VERSION ""

NS_ :

BS_:

BU_: ECM

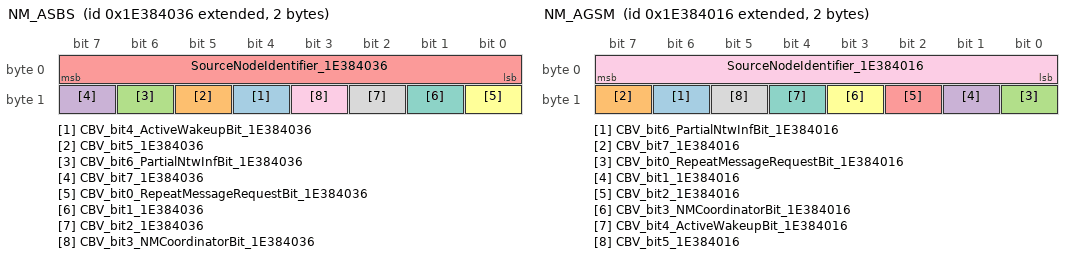
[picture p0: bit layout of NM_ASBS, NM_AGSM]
BO_ 2654486582 NM_ASBS: 2 Vector__XXX
 SG_ CBV_bit4_ActiveWakeupBit_1E384036 : 12|1@0+ (1,0) [0|1] "" ECM
 SG_ CBV_bit5_1E384036 : 13|1@0+ (1,0) [0|1] "" ECM
 SG_ CBV_bit6_PartialNtwInfBit_1E384036 : 14|1@0+ (1,0) [0|1] "" ECM
 SG_ CBV_bit7_1E384036 : 15|1@0+ (1,0) [0|1] "" ECM
 SG_ SourceNodeIdentifier_1E384036 : 7|8@0+ (1,0) [0|255] "-"  ECM
 SG_ CBV_bit0_RepeatMessageRequestBit_1E384036 : 8|1@0+ (1,0) [0|1] "" ECM
 SG_ CBV_bit1_1E384036 : 9|1@0+ (1,0) [0|1] "" ECM
 SG_ CBV_bit2_1E384036 : 10|1@0+ (1,0) [0|1] "" ECM
 SG_ CBV_bit3_NMCoordinatorBit_1E384036 : 11|1@0+ (1,0) [0|1] "" ECM

BO_ 2654486550 NM_AGSM: 2 Vector__XXX
 SG_ CBV_bit6_PartialNtwInfBit_1E384016 : 14|1@0+ (1,0) [0|1] "" ECM
 SG_ CBV_bit7_1E384016 : 15|1@0+ (1,0) [0|1] "" ECM
 SG_ CBV_bit0_RepeatMessageRequestBit_1E384016 : 8|1@0+ (1,0) [0|1] "" ECM
 SG_ CBV_bit1_1E384016 : 9|1@0+ (1,0) [0|1] "" ECM
 SG_ CBV_bit2_1E384016 : 10|1@0+ (1,0) [0|1] "" ECM
 SG_ CBV_bit3_NMCoordinatorBit_1E384016 : 11|1@0+ (1,0) [0|1] "" ECM
 SG_ CBV_bit4_ActiveWakeupBit_1E384016 : 12|1@0+ (1,0) [0|1] "" ECM
 SG_ CBV_bit5_1E384016 : 13|1@0+ (1,0) [0|1] "" ECM
 SG_ SourceNodeIdentifier_1E384016 : 7|8@0+ (1,0) [0|63] "-"  ECM

BO_ 269 HYBRID_POWERTRAIN2: 64 Vector__XXX
 SG_ MaxRegenStat : 299|1@0+ (1,0) [0|1] "" ECM
 SG_ IdleSpeedActiveSts : 302|1@0+ (1,0) [0|0] "-"  ECM
 SG_ CRC_HYBRID_POWERTRAIN2 : 447|8@0+ (1,0) [0|255] "-"  ECM
 SG_ BSGChrgIdleSpeedTarget : 52|13@0+ (1,0) [0|8190] "rpm"  ECM
 SG_ BSGActualTorque : 257|10@0+ (0.32,-163.52) [-163.52|163.2] "Nm"  ECM
 SG_ PropulsionMode : 39|3@0+ (1,0) [0|6] "-"  ECM
 SG_ REPRGD_PFC_CLR_HCP : 303|1@0+ (1,0) [0|1] "-"  ECM
 SG_ EstRegenBrkFWTorq : 371|12@0+ (0.32,-300.16) [-300.16|1009.92] "Nm"  ECM
 SG_ CODE_CLR_HCP : 288|1@0+ (1,0) [0|1] "-"  ECM
 SG_ AeCoast_Ramp : 55|1@0+ (1,0) [0|1] "-"  ECM
 SG_ AHH_ModifyAccel_Req : 4|2@0+ (1,0) [0|2] "" ECM
 SG_ MessageCounter_HYBRID_POWERTRAI_10D : 435|4@0+ (1,0) [0|15] "-"  ECM

BO_ 276 HYBRID_POWERTRAIN1: 64 Vector__XXX
 SG_ TransInpSpdPrfl : 68|13@0+ (1,0) [0|8191] "rpm"  ECM
 SG_ ShiftRangeState : 439|4@0+ (1,0) [0|0] "-"  ECM
 SG_ NiTi_Achieved : 288|1@0+ (1,0) [0|0] "-"  ECM
 SG_ MinCreepWheelTrq_Enable : 286|1@0+ (1,0) [0|1] "" ECM
 SG_ LV_SystemFailure : 421|1@0+ (1,0) [0|0] "-"  ECM
 SG_ InputSpdRaw : 179|12@0+ (1,-2048) [-2048|2046] "rpm"  ECM
 SG_ HybTransSt : 255|8@0+ (1,0) [0|0] "-"  ECM
 SG_ Hybrid_Remedial_Stop : 290|1@0+ (1,0) [0|0] "-"  ECM
 SG_ HybFeedback_Engine : 294|1@0+ (1,0) [0|0] "-"  ECM
 SG_ HybEstEngTorqV : 280|1@0+ (1,0) [0|0] "-"  ECM
 SG_ HybEstEngTorq : 163|12@0+ (0.32,-300.16) [-300.16|1008] "Nm"  ECM
 SG_ HybDFCO_Req : 281|1@0+ (1,0) [0|0] "-"  ECM
 SG_ HybCrnkAbrted : 282|1@0+ (1,0) [0|0] "-"  ECM
 SG_ HybCmndEngTorqRespTyp : 277|2@0+ (1,0) [0|0] "-"  ECM
 SG_ HybCmndEngTorqPrdtd : 147|12@0+ (0.32,-300.16) [-300.16|1008] "Nm"  ECM
 SG_ HybCmndEngTorqImmed : 131|12@0+ (0.32,-300.16) [-300.16|1008] "Nm"  ECM
 SG_ Hyb_EngStrtStopType : 267|4@0+ (1,0) [0|0] "-"  ECM
 SG_ HEV_ESS_Mode : 271|4@0+ (1,0) [0|0] "-"  ECM
 SG_ GeneratorSetpointOverride : 422|1@0+ (1,0) [0|0] "-"  ECM
 SG_ EngTrqReserveCmd : 263|8@0+ (0.32,0) [0|81.28] "Nm"  ECM
 SG_ EngCntrlMode : 283|1@0+ (1,0) [0|0] "-"  ECM
 SG_ EngActDmpgDsblReq : 291|1@0+ (1,0) [0|0] "-"  ECM
 SG_ Eng_Off_Allowed : 292|1@0+ (1,0) [0|0] "-"  ECM
 SG_ ECMPrepIdleRes : 295|1@0+ (1,0) [0|0] "-"  ECM
 SG_ CRC_HYBRID_POWERTRAIN1 : 447|8@0+ (1,0) [0|255] "-"  ECM
 SG_ PropulsionSystemActive : 408|1@0+ (1,0) [0|1] "-"  ECM
 SG_ HybFstTrqRq_Trans : 293|1@0+ (1,0) [0|0] "-"  ECM
 SG_ HCP_Comm_Fail_CAN : 87|3@0+ (1,0) [0|7] "-"  ECM
 SG_ MinCreepWheelTrq : 53|14@0+ (2,-16383) [-16383|16383] "Nm"  ECM
 SG_ NiTi_Disable : 55|1@0+ (1,0) [0|1] "-"  ECM
 SG_ Hyb_MotorB_Speed : 303|16@0+ (1,-16382) [-16382|49152] "rpm"  ECM
 SG_ Hyb_SumTorqueMin : 314|11@0+ (1,-500) [-500|1546] "Nm"  ECM
 SG_ Hyb_SumTorqueMax : 330|11@0+ (1,-500) [-500|1546] "Nm"  ECM
 SG_ Hyb_SumTorqueStatic : 346|11@0+ (1,-500) [-500|1546] "Nm"  ECM
 SG_ DriveModeSts_EPT : 427|4@0+ (1,0) [0|14] "-"  ECM
 SG_ HCP_VTD_Freeze : 7|2@0+ (1,0) [0|3] "-"  ECM
 SG_ MessageCounter_HYBRID_POWERTRAI_114 : 435|4@0+ (1,0) [0|15] "-"  ECM

BO_ 271 ENGINE_HYBD_FD_1: 64 ECM
 SG_ TLC_LRN_Rq : 322|1@0+ (1,0) [0|0] "-"  Vector__XXX
 SG_ T_min_raw_Aggressive : 39|16@0+ (2,-36878) [-36878|94190] "Nm"  Vector__XXX
 SG_ T_max_raw : 55|16@0+ (2,-36878) [-36878|94190] "Nm"  Vector__XXX
 SG_ Sum_FW_ID_Slw : 327|5@0+ (1,0) [0|30] "-"  Vector__XXX
 SG_ Sum_FW_ID_Fst : 367|5@0+ (1,0) [0|30] "-"  Vector__XXX
 SG_ PTCrnkAbrted : 309|1@0+ (1,0) [0|0] "-"  Vector__XXX
 SG_ PT_CrnkAct : 310|1@0+ (1,0) [0|0] "-"  Vector__XXX
 SG_ MinPrdtdEngRunTorqCapV : 213|1@0+ (1,0) [0|0] "-"  Vector__XXX
 SG_ MinPrdtdEngRunTorqCap : 243|12@0+ (0.32,-300.16) [-300.16|1008] "Nm"  Vector__XXX
 SG_ MinImmedEngTorqCapV : 215|1@0+ (1,0) [0|0] "-"  Vector__XXX
 SG_ MinImmedEngTorqCap : 227|12@0+ (0.32,-300.16) [-300.16|1008] "Nm"  Vector__XXX
 SG_ MinEngTorqCapV : 196|1@0+ (1,0) [0|0] "-"  Vector__XXX
 SG_ MinEngTorqCap : 211|12@0+ (0.32,-300.16) [-300.16|1008] "Nm"  Vector__XXX
 SG_ MinAirFlowMinSparkTorqCapV : 197|1@0+ (1,0) [0|0] "-"  Vector__XXX
 SG_ MinAirFlowMinSparkTorqCap : 195|12@0+ (0.32,-300.16) [-300.16|1008] "Nm"  Vector__XXX
 SG_ MessageCounter_ENGINE_HYBD_FD_1 : 435|4@0+ (1,0) [0|15] "-"  Vector__XXX
 SG_ MaxPrdtdEngTorqCapV : 198|1@0+ (1,0) [0|0] "-"  Vector__XXX
 SG_ MaxPrdtdEngTorqCap : 179|12@0+ (0.32,-300.16) [-300.16|1008] "Nm"  Vector__XXX
 SG_ MaxOffEngTorqCap : 163|12@0+ (0.32,-300.16) [-300.16|1008] "Nm"  Vector__XXX
 SG_ HybActEngTorqRespTyp : 149|2@0+ (1,0) [0|0] "-"  Vector__XXX
 SG_ Feedback_HCP : 293|1@0+ (1,0) [0|0] "-"  Vector__XXX
 SG_ ETRQ_Mode : 362|3@0+ (1,0) [0|5] "-"  Vector__XXX
 SG_ ESS_Engine_State_EE : 119|4@0+ (1,0) [0|0] "-"  Vector__XXX
 SG_ EngTrqReserveReq : 351|8@0+ (0.32,0) [0|81.28] "Nm"  Vector__XXX
 SG_ EngSysFld : 294|1@0+ (1,0) [0|0] "-"  Vector__XXX
 SG_ EngRunCrnkAct : 295|1@0+ (1,0) [0|0] "-"  Vector__XXX
 SG_ EngRqStTyp : 103|4@0+ (1,0) [0|0] "-"  Vector__XXX
 SG_ EngOffRecom : 276|1@0+ (1,0) [0|0] "-"  Vector__XXX
 SG_ Engine_Sync_720 : 277|1@0+ (1,0) [0|0] "-"  Vector__XXX
 SG_ EngDFCO_St : 278|1@0+ (1,0) [0|0] "-"  Vector__XXX
 SG_ EngDFCO_Req : 279|1@0+ (1,0) [0|0] "-"  Vector__XXX
 SG_ EngDFCO_Allw : 260|1@0+ (1,0) [0|0] "-"  Vector__XXX
 SG_ EngCmbstnCmnd : 199|1@0+ (1,0) [0|0] "-"  Vector__XXX
 SG_ EngAirFlwStdyStTorqV : 262|1@0+ (1,0) [0|0] "-"  Vector__XXX
 SG_ EngAirFlwStdyStTorq : 275|12@0+ (0.32,-300.16) [-300.16|1008] "Nm"  Vector__XXX
 SG_ EngActuatorsStat : 133|2@0+ (1,0) [0|0] "-"  Vector__XXX
 SG_ EngActStdyStTorqV : 263|1@0+ (1,0) [0|0] "-"  Vector__XXX
 SG_ EngActStdyStTorq : 259|12@0+ (0.32,-300.16) [-300.16|1008] "Nm"  Vector__XXX
 SG_ ECU_A2D_Failure : 244|1@0+ (1,0) [0|0] "-"  Vector__XXX
 SG_ ECM_IMMO_STAT_CANePT : 87|2@0+ (1,0) [0|0] "-"  Vector__XXX
 SG_ DrvrIntndedAxleTorqRawV : 183|1@0+ (1,0) [0|0] "-"  Vector__XXX
 SG_ DrvrIntndedAxleTorqRaw : 23|16@0+ (2,-36878) [-36878|94190] "Nm"  Vector__XXX
 SG_ CylOff : 245|1@0+ (1,0) [0|0] "-"  Vector__XXX
 SG_ CRC_ENGINE_HYBD_FD_1 : 447|8@0+ (1,0) [0|255] "-"  Vector__XXX
 SG_ Crank_Maturing_Fault : 246|1@0+ (1,0) [0|0] "-"  Vector__XXX
 SG_ Crank_Locked : 247|1@0+ (1,0) [0|0] "-"  Vector__XXX
 SG_ CmndFlyWheelTorqRespTyp : 165|2@0+ (1,0) [0|0] "-"  Vector__XXX
 SG_ CmndFlyWheelTorqPrdtd : 115|12@0+ (0.32,-300.16) [-300.16|1008] "Nm"  Vector__XXX
 SG_ CmndFlyWheelTorqPotential : 99|12@0+ (0.32,-300.16) [-300.16|1008] "Nm"  Vector__XXX
 SG_ Cam_Int_2_Locked : 228|1@0+ (1,0) [0|0] "-"  Vector__XXX
 SG_ Cam_Int_1_Locked : 229|1@0+ (1,0) [0|0] "-"  Vector__XXX
 SG_ Cam_Exh_2_Locked : 230|1@0+ (1,0) [0|0] "-"  Vector__XXX
 SG_ Cam_Exh_1_Locked : 231|1@0+ (1,0) [0|0] "-"  Vector__XXX
 SG_ AccPosV : 214|1@0+ (1,0) [0|1] "" Vector__XXX
 SG_ AccPos : 343|8@0+ (0.392157,0) [0|100] "%"  Vector__XXX
 SG_ ECMReq_Remedial_Stop : 135|2@0+ (1,0) [0|0] "-"  Vector__XXX
 SG_ ECM_Comm_Fail_CAN : 375|3@0+ (1,0) [0|7] "-"  Vector__XXX
 SG_ EngCylDeactMd : 151|2@0+ (1,0) [0|0] "-"  Vector__XXX
 SG_ EngCylDeactEnCondMet : 261|1@0+ (1,0) [0|0] "-"  Vector__XXX
 SG_ CmndAxleTorqRespTyp : 167|2@0+ (1,0) [0|0] "-"  Vector__XXX
 SG_ T_Min_Mgate : 7|16@0+ (2,-36878) [-36878|94190] "Nm"  Vector__XXX
 SG_ T_min_raw : 71|16@0+ (2,-36878) [-36878|94190] "Nm"  Vector__XXX
 SG_ ECM_VTD_Freeze : 85|2@0+ (1,0) [0|3] "-"  Vector__XXX
 SG_ MAP_4_BAR_PHEV : 392|9@0+ (0.8,0) [0|408] "kPa"  Vector__XXX
 SG_ RedSpkAuthorityAvbl : 308|1@0+ (1,0) [0|1] "" Vector__XXX
 SG_ EngMinSparkNomCurrAirTorqCap : 82|11@0+ (1,-500) [-500|1547] "Nm"  Vector__XXX

CM_ SG_ 271 MinImmedEngTorqCapV "Minimum immediate engine torque capacity validity; Invalid = [1]";
CM_ SG_ 271 MinPrdtdEngRunTorqCap "Minimum predicted engine run torque capacity (minimum air flow, MBT spark)";
CM_ SG_ 271 HybActEngTorqRespTyp "Hybrid Actual Engine Torque Response Type";
CM_ SG_ 271 MaxOffEngTorqCap "Capacity Max-off";
CM_ SG_ 271 MaxPrdtdEngTorqCap "Maximum predicted engine torque capacity";
CM_ SG_ 271 MaxPrdtdEngTorqCapV "Maximum predicted engine torque capacity validity; Invalid = [1]";
CM_ SG_ 271 MessageCounter_ENGINE_HYBD_FD_1 "This signal is a counter used for safety checks strategies. This counter is incremented of 1 (one) unit at each frame transmission.";
CM_ SG_ 271 MinAirFlowMinSparkTorqCap "Engine Torque capacity at minimum air flow and  minimum spark";
CM_ SG_ 271 EngRunCrnkAct "ECM run crank terminal status, 1=active";
CM_ SG_ 271 EngSysFld "Engine System Failed";
CM_ SG_ 271 EngTrqReserveReq "Engine Torque Reserve Request";
CM_ SG_ 271 ESS_Engine_State_EE "ESS Engine State";
CM_ SG_ 271 ETRQ_Mode "Enumeration of combustion torque mode";
CM_ SG_ 271 Feedback_HCP "Indication that the ECM is receiving valid data from the HCP. 0 - False; 1 - True.";
CM_ SG_ 271 EngDFCO_Allw "Engine deceleration fuel cut off allowed";
CM_ SG_ 271 EngDFCO_Req "Engine deceleration fuel cut off requested";
CM_ SG_ 271 EngDFCO_St "Engine deceleration fuel cut off state";
CM_ SG_ 271 Engine_Sync_720 "Indicates that the crank and cams have synchronized";
CM_ SG_ 271 EngOffRecom "Engine off recommendation";
CM_ SG_ 271 EngRqStTyp "Engine requested start type";
CM_ SG_ 271 EngActStdyStTorq "Engine actual steady state torque (current conditions)";
CM_ SG_ 271 EngActStdyStTorqV "Engine actual steady state torque validity; Invalid = [1]";
CM_ SG_ 271 EngActuatorsStat "Engine Actuator Status for Autostop";
CM_ SG_ 271 EngAirFlwStdyStTorq "Engine airflow steady state torque (potential)";
CM_ SG_ 271 EngAirFlwStdyStTorqV "Engine airflow steady state torque validity; Invalid = [1]";
CM_ SG_ 271 EngCmbstnCmnd "Engine combustion commanded";
CM_ SG_ 271 CRC_ENGINE_HYBD_FD_1 "CRC according to SAE J1850 standard at each frame transmission.";
CM_ SG_ 271 CylOff "Cylinder off due to misfire";
CM_ SG_ 271 DrvrIntndedAxleTorqRaw "Driver Intended Axle Torque Raw";
CM_ SG_ 271 DrvrIntndedAxleTorqRawV "Driver Intended Axle Torque Raw Validity; Invalid = [1]";
CM_ SG_ 271 ECM_IMMO_STAT_CANePT "ECM Immobilizer Status";
CM_ SG_ 271 ECU_A2D_Failure "AVD Failure Flag";
CM_ SG_ 271 Cam_Int_2_Locked "Indicates the camshaft driver has locked the camshaft position (intake cam bank 2)";
CM_ SG_ 271 CmndFlyWheelTorqPotential "Commanded Flywheel Torque Potential";
CM_ SG_ 271 CmndFlyWheelTorqPrdtd "Commanded Flywheel Torque: Predicted Torque";
CM_ SG_ 271 CmndFlyWheelTorqRespTyp "Commanded Flywheel Torque Response Type";
CM_ SG_ 271 Crank_Locked "Indicates that the crankshaft has locked its position";
CM_ SG_ 271 Crank_Maturing_Fault "Indicates ECM is maturing a crank fault diagnostic";
CM_ SG_ 271 ECMReq_Remedial_Stop "Engine Stop Request";
CM_ SG_ 271 AccPos "Accelerator Effective Position";
CM_ SG_ 271 AccPosV "Accelerator Effective Position Validity";
CM_ SG_ 271 Cam_Exh_1_Locked "Indicates the camshaft driver has locked the camshaft position (exhaust cam bank 1)";
CM_ SG_ 271 Cam_Exh_2_Locked "Indicates the camshaft driver has locked the camshaft position (exhaust cam bank 2)";
CM_ SG_ 271 Cam_Int_1_Locked "Indicates the camshaft driver has locked the camshaft position (intake cam bank 1)";
CM_ SG_ 271 EngMinSparkNomCurrAirTorqCap "Engine Torque capacity at current airflow  min and  nominal spark advance.";
CM_ SG_ 271 RedSpkAuthorityAvbl "Reduced Spark Availability Warning";
CM_ SG_ 271 MAP_4_BAR_PHEV "Engine manifold pressure (4 bar range) 10ms cyclic";
CM_ SG_ 271 ECM_VTD_Freeze "ECM request for ITID Freeze";
CM_ SG_ 271 T_min_raw "Driver intended axle torque raw minimum";
CM_ SG_ 271 ECM_Comm_Fail_CAN "Communication fault on CAN detected by ECM.";
CM_ SG_ 271 T_min_raw_Aggressive "Max regen intended torque at min pedal";
CM_ SG_ 271 TLC_LRN_Rq "TLC learning request";
CM_ SG_ 271 T_Min_Mgate "Driver Intended Axle Torque";
CM_ SG_ 271 CmndAxleTorqRespTyp "Commanded Axle Torque Response Type";
CM_ SG_ 271 EngCylDeactEnCondMet "Engine cylinder deactivation enable conditions met";
CM_ SG_ 271 EngCylDeactMd "Engine Cylinder Deactivation Mode";
CM_ SG_ 276 MinCreepWheelTrq_Enable "Enable Minimum Creep Wheel Torque in arbitration";
CM_ SG_ 276 NiTi_Achieved "NiTi is achieved by HCP; True = [1]";
CM_ SG_ 276 ShiftRangeState "Shift range state";
CM_ SG_ 276 TransInpSpdPrfl "Transmission Input Speed Profile";
CM_ SG_ 276 MessageCounter_HYBRID_POWERTRAI_114 "This signal is a counter used for safety checks strategies. This counter is incremented of 1 (one) unit at each frame transmission.";
CM_ SG_ 276 DriveModeSts_EPT "Final eDrive mode status";
CM_ SG_ 276 HybEstEngTorqV "Hybrid estimated engine torque validity. 0 = Valid, 1 = Invalid";
CM_ SG_ 276 HybFeedback_Engine "Indication that the HCP is receiving valid data from the ECM. 0 - False; 1 - True.";
CM_ SG_ 276 Hybrid_Remedial_Stop "Engine Start Allowed.0 = ENG_ON_ALLOWED, 1 = ENG_ON_NOT_ALLOW";
CM_ SG_ 276 HybTransSt "Hybrid transmission state";
CM_ SG_ 276 InputSpdRaw "Trans input speed from HCP.";
CM_ SG_ 276 LV_SystemFailure "Low voltage system failed";
CM_ SG_ 276 HybCmndEngTorqImmed "Hybrid commanded engine torque immediate torque (fast path)";
CM_ SG_ 276 HybCmndEngTorqPrdtd "Hybrid commanded engine torque predicted torque (slow path).";
CM_ SG_ 276 HybCmndEngTorqRespTyp "Hybrid Commanded Engine Torque Response Type";
CM_ SG_ 276 HybCrnkAbrted "Hybrid Crank Aborted";
CM_ SG_ 276 HybDFCO_Req "Hybrid deceleration fuel cut off request";
CM_ SG_ 276 HybEstEngTorq "Hybrid estimated engine torque";
CM_ SG_ 276 EngActDmpgDsblReq "Engine Active Damping Disable Request";
CM_ SG_ 276 EngCntrlMode "EngCntrlMode, [0] = Torque Mode, [1] = Speed Mode";
CM_ SG_ 276 EngTrqReserveCmd "Engine torque reserve command";
CM_ SG_ 276 GeneratorSetpointOverride "Hybrid generator setpoint duty cycle powertrain override active";
CM_ SG_ 276 HEV_ESS_Mode "Engine start stop information:  engine start stop mode";
CM_ SG_ 276 Hyb_EngStrtStopType "Current start/stop type.";
CM_ SG_ 276 HCP_Comm_Fail_CAN "Communication fault on CAN detected by HCP.";
CM_ SG_ 276 HybFstTrqRq_Trans "HCP request for Spark Retard to honor Trans Torque reduction request. 0 - False; 1 - True.";
CM_ SG_ 276 PropulsionSystemActive "Propulsion system active, [1] = active";
CM_ SG_ 276 CRC_HYBRID_POWERTRAIN1 "CRC according to SAE J1850 standard at each frame transmission.";
CM_ SG_ 276 ECMPrepIdleRes "ECM to prep for rolling idle reserve";
CM_ SG_ 276 Eng_Off_Allowed "Engine Stop Allowed. 0 = ENG_OFF_NOT_ALLOWED, 1 = ENG_OFF_ALLOWED";
CM_ SG_ 276 HCP_VTD_Freeze "HCP request for ITID Freeze";
CM_ SG_ 276 Hyb_SumTorqueStatic "Static sum torque (effective sum torque)";
CM_ SG_ 276 Hyb_SumTorqueMax "Maximum sum torque";
CM_ SG_ 276 Hyb_SumTorqueMin "Minimum sum torque";
CM_ SG_ 276 Hyb_MotorB_Speed "Electric motor revolutions per minute";
CM_ SG_ 276 NiTi_Disable "NiTi is disabled by HCP; True = [1]";
CM_ SG_ 276 MinCreepWheelTrq "Minimum Creep  wheel Torque";
CM_ SG_ 269 AHH_ModifyAccel_Req "AHH_ModifyAccel_Req";
CM_ SG_ 269 AeCoast_Ramp "Aggressive E Coasting Ramp rate fro activation / deactivation.";
CM_ SG_ 269 PropulsionMode "Propulsion mode of the vehicle";
CM_ SG_ 269 BSGActualTorque "BSG Actual Torque";
CM_ SG_ 269 BSGChrgIdleSpeedTarget "BSG Charge Idle Speed Target";
CM_ SG_ 269 CRC_HYBRID_POWERTRAIN2 "CRC according to SAE J1850 standard at each frame transmission.";
CM_ SG_ 269 IdleSpeedActiveSts "Flag to indicate idle speed target [1] = TRUE";
CM_ SG_ 269 MaxRegenStat "Availability of Max Regen; Possible = [1].";
CM_ SG_ 269 MessageCounter_HYBRID_POWERTRAI_10D "This signal is a counter used for safety checks strategies. This counter is incremented of 1 (one) unit at each frame transmission.";
CM_ SG_ 269 CODE_CLR_HCP "Clear emission related faults";
CM_ SG_ 269 EstRegenBrkFWTorq "Estimate Regenerative Braking Fly wheel Torque";
CM_ SG_ 269 REPRGD_PFC_CLR_HCP "Set readiness to \"incomplete\"";
CM_ SG_ 2654486550 SourceNodeIdentifier_1E384016 "Source Node Identifier";
CM_ SG_ 2654486550 CBV_bit0_RepeatMessageRequestBit_1E384016 "Repeat Message Request Bit";
CM_ SG_ 2654486550 CBV_bit3_NMCoordinatorBit_1E384016 "NM Coordinator Sleep Bit";
CM_ SG_ 2654486550 CBV_bit4_ActiveWakeupBit_1E384016 "Active Wakeup Bit";
CM_ SG_ 2654486550 CBV_bit6_PartialNtwInfBit_1E384016 "Partial Network Information Bit (PNI)";
CM_ SG_ 2654486582 CBV_bit0_RepeatMessageRequestBit_1E384036 "Repeat Message Request Bit";
CM_ SG_ 2654486582 CBV_bit3_NMCoordinatorBit_1E384036 "NM Coordinator Sleep Bit";
CM_ SG_ 2654486582 CBV_bit4_ActiveWakeupBit_1E384036 "Active Wakeup Bit";
CM_ SG_ 2654486582 CBV_bit6_PartialNtwInfBit_1E384036 "Partial Network Information Bit (PNI)";
CM_ SG_ 2654486582 SourceNodeIdentifier_1E384036 "Source Node Identifier";
CM_ SG_ 271 MinPrdtdEngRunTorqCapV "Minimum predicted engine run torque capacity validity; Invalid = [1]";
CM_ SG_ 271 PT_CrnkAct "Powertrain crank active";
CM_ SG_ 271 PTCrnkAbrted "Powertrain crank aborted";
CM_ SG_ 271 Sum_FW_ID_Fst "Enumeration of system controlling combustion fast path";
CM_ SG_ 271 Sum_FW_ID_Slw "Enumeration of system controlling combustion slow path";
CM_ SG_ 271 T_max_raw "Driver intended axle torque raw maximum";
CM_ SG_ 271 MinAirFlowMinSparkTorqCapV "Engine Torque capacity at minimum air flow and  minimum spark validity; Invalid = [1]";
CM_ SG_ 271 MinEngTorqCap "Minimum engine torque capacity (min air flow, fuel off)";
CM_ SG_ 271 MinEngTorqCapV "Minimum engine torque capacity validity; Invalid = [1]";
CM_ SG_ 271 MinImmedEngTorqCap "Minimum immediate engine torque capacity (current air flow, minimum spark)";
BA_DEF_ SG_ "GenSigTimeoutTime_ADCAM" INT 0 65535;
BA_DEF_ SG_ "GenSigTimeoutTime_EVCU2" INT 0 65535;
BA_DEF_ SG_ "GenSigTimeoutTime_VDCM" INT 0 65535;
BA_DEF_ SG_ "GenSigStartValue" INT 0 2147483647;
BA_DEF_ SG_ "GenSigInactiveValue" INT 0 2147483647;
BA_DEF_ SG_ "GenSigSendType" ENUM "NotUsed","OnWrite","OnWriteWithRepetition","OnChange","OnChangeWithRepetition","IfActive","IfActiveWithRepetition","NoSigSendType";
BA_DEF_ SG_ "SystemSignalLongSymbol" STRING ;
BA_DEF_ SG_ "GenSigTimeoutTime_AGSM" INT 0 65535;
BA_DEF_ SG_ "GenSigTimeoutTime_ASBS" INT 0 65535;
BA_DEF_ SG_ "GenSigTimeoutTime_BCM" INT 0 65535;
BA_DEF_ SG_ "GenSigTimeoutTime_BSM" INT 0 65535;
BA_DEF_ SG_ "GenSigTimeoutTime_CADM" INT 0 65535;
BA_DEF_ SG_ "GenSigTimeoutTime_DMSM" INT 0 65535;
BA_DEF_ SG_ "GenSigTimeoutTime_DTCM" INT 0 65535;
BA_DEF_ SG_ "GenSigTimeoutTime_ECM" INT 0 65535;
BA_DEF_ SG_ "GenSigTimeoutTime_ELSDM" INT 0 65535;
BA_DEF_ SG_ "GenSigTimeoutTime_ESL" INT 0 65535;
BA_DEF_ SG_ "GenSigTimeoutTime_GNMM" INT 0 65535;
BA_DEF_ SG_ "GenSigTimeoutTime_HCP" INT 0 65535;
BA_DEF_ SG_ "GenSigTimeoutTime_IPC" INT 0 65535;
BA_DEF_ SG_ "GenSigTimeoutTime_RFHM" INT 0 65535;
BA_DEF_ SG_ "GenSigTimeoutTime_SGW" INT 0 65535;
BA_DEF_ SG_ "GenSigTimeoutTime_TCM" INT 0 65535;
BA_DEF_ BO_ "DiagRequest" ENUM "No","Yes";
BA_DEF_ BO_ "Type" ENUM "P","C","PE","COC","PE_Cntrl","E","E_Cntrl","OC","S","BAF","DC","EM","MM","ISO-TP","-";
BA_DEF_ BO_ "DiagResponse" ENUM "No","Yes";
BA_DEF_ BO_ "NmMessage" ENUM "No","Yes";
BA_DEF_ BO_ "GenMsgSendType" ENUM "Cyclic","NotUsed","NotUsed","NotUsed","NotUsed","NotUsed","NotUsed","NotUsed","NoMsgSendType";
BA_DEF_ BO_ "GenMsgNrOfRepetition" INT 0 255;
BA_DEF_ BO_ "GenMsgILSupport" ENUM "No","Yes";
BA_DEF_ BO_ "GenMsgStartDelayTime" INT 0 65535;
BA_DEF_ BO_ "GenMsgCycleTimeFast" INT 0 65535;
BA_DEF_ BO_ "GenMsgCycleTime" INT 0 65535;
BA_DEF_ BO_ "GenMsgDelayTime" INT 0 65535;
BA_DEF_ BO_ "NmAsrMessage" ENUM "No","Yes";
BA_DEF_ BO_ "DiagState" ENUM "No","Yes";
BA_DEF_ BO_ "DiagConnection" HEX 0 65535;
BA_DEF_ BO_ "VFrameFormat" ENUM "StandardCAN","ExtendedCAN","reserved","reserved","reserved","reserved","reserved","reserved","reserved","reserved","reserved","reserved","reserved","reserved","StandardCAN_FD","ExtendedCAN_FD";
BA_DEF_ BO_ "CANFD_BRS" ENUM "0","1";
BA_DEF_DEF_ "GenSigTimeoutTime_ADCAM" 2500;
BA_DEF_DEF_ "GenSigTimeoutTime_EVCU2" 2500;
BA_DEF_DEF_ "GenSigTimeoutTime_VDCM" 2500;
BA_DEF_DEF_ "GenSigStartValue" 0;
BA_DEF_DEF_ "GenSigInactiveValue" 0;
BA_DEF_DEF_ "GenSigSendType" "NoSigSendType";
BA_DEF_DEF_ "SystemSignalLongSymbol" "";
BA_DEF_DEF_ "GenSigTimeoutTime_AGSM" 2500;
BA_DEF_DEF_ "GenSigTimeoutTime_ASBS" 2500;
BA_DEF_DEF_ "GenSigTimeoutTime_BCM" 2500;
BA_DEF_DEF_ "GenSigTimeoutTime_BSM" 2500;
BA_DEF_DEF_ "GenSigTimeoutTime_CADM" 2500;
BA_DEF_DEF_ "GenSigTimeoutTime_DMSM" 2500;
BA_DEF_DEF_ "GenSigTimeoutTime_DTCM" 2500;
BA_DEF_DEF_ "GenSigTimeoutTime_ECM" 2500;
BA_DEF_DEF_ "GenSigTimeoutTime_ELSDM" 2500;
BA_DEF_DEF_ "GenSigTimeoutTime_ESL" 2500;
BA_DEF_DEF_ "GenSigTimeoutTime_GNMM" 2500;
BA_DEF_DEF_ "GenSigTimeoutTime_HCP" 2500;
BA_DEF_DEF_ "GenSigTimeoutTime_IPC" 2500;
BA_DEF_DEF_ "GenSigTimeoutTime_RFHM" 2500;
BA_DEF_DEF_ "GenSigTimeoutTime_SGW" 2500;
BA_DEF_DEF_ "GenSigTimeoutTime_TCM" 2500;
BA_DEF_DEF_ "DiagRequest" "No";
BA_DEF_DEF_ "Type" "-";
BA_DEF_DEF_ "DiagResponse" "No";
BA_DEF_DEF_ "NmMessage" "No";
BA_DEF_DEF_ "GenMsgSendType" "NoMsgSendType";
BA_DEF_DEF_ "GenMsgNrOfRepetition" 0;
BA_DEF_DEF_ "GenMsgILSupport" "No";
BA_DEF_DEF_ "GenMsgStartDelayTime" 0;
BA_DEF_DEF_ "GenMsgCycleTimeFast" 0;
BA_DEF_DEF_ "GenMsgCycleTime" 0;
BA_DEF_DEF_ "GenMsgDelayTime" 0;
BA_DEF_DEF_ "NmAsrMessage" "No";
BA_DEF_DEF_ "DiagState" "No";
BA_DEF_DEF_ "DiagConnection" 0;
BA_DEF_DEF_ "VFrameFormat" "StandardCAN_FD";
BA_DEF_DEF_ "CANFD_BRS" "0";
BA_ "GenMsgSendType" BO_ 276 0;
BA_ "GenMsgILSupport" BO_ 276 1;
BA_ "GenMsgCycleTime" BO_ 276 10;
BA_ "CANFD_BRS" BO_ 276 1;
BA_ "Type" BO_ 269 1;
BA_ "GenMsgSendType" BO_ 269 0;
BA_ "GenMsgILSupport" BO_ 269 1;
BA_ "GenMsgStartDelayTime" BO_ 269 50;
BA_ "GenMsgCycleTime" BO_ 269 10;
BA_ "CANFD_BRS" BO_ 269 1;
BA_ "Type" BO_ 2654486550 8;
BA_ "NmMessage" BO_ 2654486550 1;
BA_ "NmAsrMessage" BO_ 2654486550 1;
BA_ "VFrameFormat" BO_ 2654486550 15;
BA_ "CANFD_BRS" BO_ 2654486550 1;
BA_ "Type" BO_ 2654486582 8;
BA_ "NmMessage" BO_ 2654486582 1;
BA_ "NmAsrMessage" BO_ 2654486582 1;
BA_ "VFrameFormat" BO_ 2654486582 15;
BA_ "CANFD_BRS" BO_ 2654486582 1;
BA_ "Type" BO_ 276 1;
BA_ "Type" BO_ 271 1;
BA_ "GenMsgSendType" BO_ 271 0;
BA_ "GenMsgILSupport" BO_ 271 1;
BA_ "GenMsgCycleTime" BO_ 271 10;
BA_ "CANFD_BRS" BO_ 271 1;
BA_ "GenSigTimeoutTime_ADCAM" SG_ 271 MessageCounter_ENGINE_HYBD_FD_1 0;
BA_ "GenSigTimeoutTime_EVCU2" SG_ 271 MessageCounter_ENGINE_HYBD_FD_1 0;
BA_ "GenSigTimeoutTime_VDCM" SG_ 271 MessageCounter_ENGINE_HYBD_FD_1 0;
BA_ "GenSigTimeoutTime_ADCAM" SG_ 271 EngSysFld 0;
BA_ "GenSigTimeoutTime_VDCM" SG_ 271 EngSysFld 0;
BA_ "GenSigTimeoutTime_ADCAM" SG_ 271 CRC_ENGINE_HYBD_FD_1 0;
BA_ "GenSigTimeoutTime_EVCU2" SG_ 271 CRC_ENGINE_HYBD_FD_1 0;
BA_ "GenSigTimeoutTime_VDCM" SG_ 271 CRC_ENGINE_HYBD_FD_1 0;
BA_ "GenSigTimeoutTime_ADCAM" SG_ 271 ECU_A2D_Failure 0;
BA_ "GenSigTimeoutTime_VDCM" SG_ 271 ECU_A2D_Failure 0;
BA_ "GenSigTimeoutTime_AGSM" SG_ 271 MinPrdtdEngRunTorqCapV 0;
BA_ "GenSigTimeoutTime_ASBS" SG_ 271 MinPrdtdEngRunTorqCapV 0;
BA_ "GenSigTimeoutTime_BCM" SG_ 271 MinPrdtdEngRunTorqCapV 0;
BA_ "GenSigTimeoutTime_BSM" SG_ 271 MinPrdtdEngRunTorqCapV 0;
BA_ "GenSigTimeoutTime_CADM" SG_ 271 MinPrdtdEngRunTorqCapV 0;
BA_ "GenSigTimeoutTime_DMSM" SG_ 271 MinPrdtdEngRunTorqCapV 0;
BA_ "GenSigTimeoutTime_DTCM" SG_ 271 MinPrdtdEngRunTorqCapV 0;
BA_ "GenSigTimeoutTime_ECM" SG_ 271 MinPrdtdEngRunTorqCapV 0;
BA_ "GenSigTimeoutTime_ELSDM" SG_ 271 MinPrdtdEngRunTorqCapV 0;
BA_ "GenSigTimeoutTime_ESL" SG_ 271 MinPrdtdEngRunTorqCapV 0;
BA_ "GenSigTimeoutTime_ASBS" SG_ 276 MinCreepWheelTrq 0;
BA_ "GenSigTimeoutTime_BCM" SG_ 276 MinCreepWheelTrq 0;
BA_ "GenSigTimeoutTime_BSM" SG_ 276 MinCreepWheelTrq 0;
BA_ "GenSigTimeoutTime_CADM" SG_ 276 MinCreepWheelTrq 0;
BA_ "GenSigTimeoutTime_DMSM" SG_ 276 MinCreepWheelTrq 0;
BA_ "GenSigTimeoutTime_DTCM" SG_ 276 MinCreepWheelTrq 0;
BA_ "GenSigTimeoutTime_ELSDM" SG_ 276 MinCreepWheelTrq 0;
BA_ "GenSigTimeoutTime_ESL" SG_ 276 MinCreepWheelTrq 0;
BA_ "GenSigTimeoutTime_GNMM" SG_ 276 MinCreepWheelTrq 0;
BA_ "GenSigTimeoutTime_HCP" SG_ 276 MinCreepWheelTrq 0;
BA_ "GenSigTimeoutTime_IPC" SG_ 276 MinCreepWheelTrq 0;
BA_ "GenSigTimeoutTime_RFHM" SG_ 276 MinCreepWheelTrq 0;
BA_ "GenSigTimeoutTime_SGW" SG_ 276 MinCreepWheelTrq 0;
BA_ "GenSigTimeoutTime_TCM" SG_ 276 MinCreepWheelTrq 0;
BA_ "GenSigTimeoutTime_ADCAM" SG_ 269 CODE_CLR_HCP 0;
BA_ "GenSigTimeoutTime_EVCU2" SG_ 269 CODE_CLR_HCP 0;
BA_ "GenSigTimeoutTime_VDCM" SG_ 269 CODE_CLR_HCP 0;
BA_ "GenSigTimeoutTime_ADCAM" SG_ 269 REPRGD_PFC_CLR_HCP 0;
BA_ "GenSigTimeoutTime_EVCU2" SG_ 269 REPRGD_PFC_CLR_HCP 0;
BA_ "GenSigTimeoutTime_VDCM" SG_ 269 REPRGD_PFC_CLR_HCP 0;
BA_ "GenSigTimeoutTime_AGSM" SG_ 269 AHH_ModifyAccel_Req 0;
BA_ "GenSigTimeoutTime_ASBS" SG_ 269 AHH_ModifyAccel_Req 0;
BA_ "GenSigTimeoutTime_BCM" SG_ 269 AHH_ModifyAccel_Req 0;
BA_ "GenSigTimeoutTime_BSM" SG_ 269 AHH_ModifyAccel_Req 0;
BA_ "GenSigTimeoutTime_CADM" SG_ 269 AHH_ModifyAccel_Req 0;
BA_ "GenSigTimeoutTime_DMSM" SG_ 269 AHH_ModifyAccel_Req 0;
BA_ "GenSigTimeoutTime_DTCM" SG_ 269 AHH_ModifyAccel_Req 0;
BA_ "GenSigTimeoutTime_ELSDM" SG_ 269 AHH_ModifyAccel_Req 0;
BA_ "GenSigTimeoutTime_ESL" SG_ 269 AHH_ModifyAccel_Req 0;
BA_ "GenSigTimeoutTime_GNMM" SG_ 269 AHH_ModifyAccel_Req 0;
BA_ "GenSigTimeoutTime_HCP" SG_ 269 AHH_ModifyAccel_Req 0;
BA_ "GenSigTimeoutTime_IPC" SG_ 269 AHH_ModifyAccel_Req 0;
BA_ "GenSigTimeoutTime_RFHM" SG_ 269 AHH_ModifyAccel_Req 0;
BA_ "GenSigTimeoutTime_SGW" SG_ 269 AHH_ModifyAccel_Req 0;
BA_ "GenSigTimeoutTime_TCM" SG_ 269 AHH_ModifyAccel_Req 0;
BA_ "GenSigTimeoutTime_AGSM" SG_ 269 AeCoast_Ramp 0;
BA_ "GenSigTimeoutTime_ASBS" SG_ 269 AeCoast_Ramp 0;
BA_ "GenSigTimeoutTime_BCM" SG_ 269 AeCoast_Ramp 0;
BA_ "GenSigTimeoutTime_BSM" SG_ 269 AeCoast_Ramp 0;
BA_ "GenSigTimeoutTime_CADM" SG_ 269 AeCoast_Ramp 0;
BA_ "GenSigTimeoutTime_DMSM" SG_ 269 AeCoast_Ramp 0;
BA_ "GenSigTimeoutTime_DTCM" SG_ 269 AeCoast_Ramp 0;
BA_ "GenSigTimeoutTime_ELSDM" SG_ 269 AeCoast_Ramp 0;
BA_ "GenSigTimeoutTime_ESL" SG_ 269 AeCoast_Ramp 0;
BA_ "GenSigTimeoutTime_GNMM" SG_ 269 AeCoast_Ramp 0;
BA_ "GenSigTimeoutTime_HCP" SG_ 269 AeCoast_Ramp 0;
BA_ "GenSigTimeoutTime_IPC" SG_ 269 AeCoast_Ramp 0;
BA_ "GenSigTimeoutTime_RFHM" SG_ 269 AeCoast_Ramp 0;
BA_ "GenSigTimeoutTime_SGW" SG_ 269 AeCoast_Ramp 0;
BA_ "GenSigTimeoutTime_TCM" SG_ 269 AeCoast_Ramp 0;
BA_ "GenSigTimeoutTime_AGSM" SG_ 269 PropulsionMode 0;
BA_ "GenSigTimeoutTime_ASBS" SG_ 269 PropulsionMode 0;
BA_ "GenSigTimeoutTime_BCM" SG_ 269 PropulsionMode 0;
BA_ "GenSigTimeoutTime_BSM" SG_ 269 PropulsionMode 0;
BA_ "GenSigTimeoutTime_CADM" SG_ 269 PropulsionMode 0;
BA_ "GenSigTimeoutTime_DMSM" SG_ 269 PropulsionMode 0;
BA_ "GenSigTimeoutTime_DTCM" SG_ 269 PropulsionMode 0;
BA_ "GenSigTimeoutTime_ELSDM" SG_ 269 PropulsionMode 0;
BA_ "GenSigTimeoutTime_ESL" SG_ 269 PropulsionMode 0;
BA_ "GenSigTimeoutTime_GNMM" SG_ 269 PropulsionMode 0;
BA_ "GenSigTimeoutTime_HCP" SG_ 269 PropulsionMode 0;
BA_ "GenSigTimeoutTime_IPC" SG_ 269 PropulsionMode 0;
BA_ "GenSigTimeoutTime_RFHM" SG_ 269 PropulsionMode 0;
BA_ "GenSigTimeoutTime_SGW" SG_ 269 PropulsionMode 0;
BA_ "GenSigTimeoutTime_TCM" SG_ 269 PropulsionMode 0;
BA_ "GenSigTimeoutTime_AGSM" SG_ 269 BSGActualTorque 0;
BA_ "GenSigTimeoutTime_ASBS" SG_ 269 BSGActualTorque 0;
BA_ "GenSigTimeoutTime_BCM" SG_ 269 BSGActualTorque 0;
BA_ "GenSigTimeoutTime_BSM" SG_ 269 BSGActualTorque 0;
BA_ "GenSigTimeoutTime_CADM" SG_ 269 BSGActualTorque 0;
BA_ "GenSigTimeoutTime_DMSM" SG_ 269 BSGActualTorque 0;
BA_ "GenSigTimeoutTime_DTCM" SG_ 269 BSGActualTorque 0;
BA_ "GenSigTimeoutTime_ELSDM" SG_ 269 BSGActualTorque 0;
BA_ "GenSigTimeoutTime_ESL" SG_ 269 BSGActualTorque 0;
BA_ "GenSigTimeoutTime_GNMM" SG_ 269 BSGActualTorque 0;
BA_ "GenSigTimeoutTime_HCP" SG_ 269 BSGActualTorque 0;
BA_ "GenSigTimeoutTime_IPC" SG_ 269 BSGActualTorque 0;
BA_ "GenSigTimeoutTime_RFHM" SG_ 269 BSGActualTorque 0;
BA_ "GenSigTimeoutTime_SGW" SG_ 269 BSGActualTorque 0;
BA_ "GenSigTimeoutTime_TCM" SG_ 269 BSGActualTorque 0;
BA_ "GenSigTimeoutTime_AGSM" SG_ 269 BSGChrgIdleSpeedTarget 0;
BA_ "GenSigTimeoutTime_ASBS" SG_ 269 BSGChrgIdleSpeedTarget 0;
BA_ "GenSigTimeoutTime_BCM" SG_ 269 BSGChrgIdleSpeedTarget 0;
BA_ "GenSigTimeoutTime_BSM" SG_ 269 BSGChrgIdleSpeedTarget 0;
BA_ "GenSigTimeoutTime_CADM" SG_ 269 BSGChrgIdleSpeedTarget 0;
BA_ "GenSigTimeoutTime_DMSM" SG_ 269 BSGChrgIdleSpeedTarget 0;
BA_ "GenSigTimeoutTime_DTCM" SG_ 269 BSGChrgIdleSpeedTarget 0;
BA_ "GenSigTimeoutTime_ELSDM" SG_ 269 BSGChrgIdleSpeedTarget 0;
BA_ "GenSigTimeoutTime_ESL" SG_ 269 BSGChrgIdleSpeedTarget 0;
BA_ "GenSigTimeoutTime_GNMM" SG_ 269 BSGChrgIdleSpeedTarget 0;
BA_ "GenSigTimeoutTime_HCP" SG_ 269 BSGChrgIdleSpeedTarget 0;
BA_ "GenSigTimeoutTime_IPC" SG_ 269 BSGChrgIdleSpeedTarget 0;
BA_ "GenSigTimeoutTime_RFHM" SG_ 269 BSGChrgIdleSpeedTarget 0;
BA_ "GenSigTimeoutTime_SGW" SG_ 269 BSGChrgIdleSpeedTarget 0;
BA_ "GenSigTimeoutTime_TCM" SG_ 269 BSGChrgIdleSpeedTarget 0;
BA_ "GenSigTimeoutTime_AGSM" SG_ 269 CRC_HYBRID_POWERTRAIN2 0;
BA_ "GenSigTimeoutTime_ASBS" SG_ 269 CRC_HYBRID_POWERTRAIN2 0;
BA_ "GenSigTimeoutTime_BCM" SG_ 269 CRC_HYBRID_POWERTRAIN2 0;
BA_ "GenSigTimeoutTime_CADM" SG_ 269 CRC_HYBRID_POWERTRAIN2 0;
BA_ "GenSigTimeoutTime_DMSM" SG_ 269 CRC_HYBRID_POWERTRAIN2 0;
BA_ "GenSigTimeoutTime_DTCM" SG_ 269 CRC_HYBRID_POWERTRAIN2 0;
BA_ "GenSigTimeoutTime_ELSDM" SG_ 269 CRC_HYBRID_POWERTRAIN2 0;
BA_ "GenSigTimeoutTime_ESL" SG_ 269 CRC_HYBRID_POWERTRAIN2 0;
BA_ "GenSigTimeoutTime_GNMM" SG_ 269 CRC_HYBRID_POWERTRAIN2 0;
BA_ "GenSigTimeoutTime_HCP" SG_ 269 CRC_HYBRID_POWERTRAIN2 0;
BA_ "GenSigTimeoutTime_IPC" SG_ 269 CRC_HYBRID_POWERTRAIN2 0;
BA_ "GenSigTimeoutTime_RFHM" SG_ 269 CRC_HYBRID_POWERTRAIN2 0;
BA_ "GenSigTimeoutTime_SGW" SG_ 269 CRC_HYBRID_POWERTRAIN2 0;
BA_ "GenSigTimeoutTime_AGSM" SG_ 269 IdleSpeedActiveSts 0;
BA_ "GenSigTimeoutTime_ASBS" SG_ 269 IdleSpeedActiveSts 0;
BA_ "GenSigTimeoutTime_BCM" SG_ 269 IdleSpeedActiveSts 0;
BA_ "GenSigTimeoutTime_BSM" SG_ 269 IdleSpeedActiveSts 0;
BA_ "GenSigTimeoutTime_CADM" SG_ 269 IdleSpeedActiveSts 0;
BA_ "GenSigTimeoutTime_DMSM" SG_ 269 IdleSpeedActiveSts 0;
BA_ "GenSigTimeoutTime_DTCM" SG_ 269 IdleSpeedActiveSts 0;
BA_ "GenSigTimeoutTime_ELSDM" SG_ 269 IdleSpeedActiveSts 0;
BA_ "GenSigTimeoutTime_ESL" SG_ 269 IdleSpeedActiveSts 0;
BA_ "GenSigTimeoutTime_GNMM" SG_ 269 IdleSpeedActiveSts 0;
BA_ "GenSigTimeoutTime_HCP" SG_ 269 IdleSpeedActiveSts 0;
BA_ "GenSigTimeoutTime_IPC" SG_ 269 IdleSpeedActiveSts 0;
BA_ "GenSigTimeoutTime_RFHM" SG_ 269 IdleSpeedActiveSts 0;
BA_ "GenSigTimeoutTime_SGW" SG_ 269 IdleSpeedActiveSts 0;
BA_ "GenSigTimeoutTime_AGSM" SG_ 269 MaxRegenStat 0;
BA_ "GenSigTimeoutTime_ASBS" SG_ 269 MaxRegenStat 0;
BA_ "GenSigTimeoutTime_BSM" SG_ 269 MaxRegenStat 0;
BA_ "GenSigTimeoutTime_CADM" SG_ 269 MaxRegenStat 0;
BA_ "GenSigTimeoutTime_DMSM" SG_ 269 MaxRegenStat 0;
BA_ "GenSigTimeoutTime_DTCM" SG_ 269 MaxRegenStat 0;
BA_ "GenSigTimeoutTime_ELSDM" SG_ 269 MaxRegenStat 0;
BA_ "GenSigTimeoutTime_ESL" SG_ 269 MaxRegenStat 0;
BA_ "GenSigTimeoutTime_GNMM" SG_ 269 MaxRegenStat 0;
BA_ "GenSigTimeoutTime_HCP" SG_ 269 MaxRegenStat 0;
BA_ "GenSigTimeoutTime_IPC" SG_ 269 MaxRegenStat 0;
BA_ "GenSigTimeoutTime_RFHM" SG_ 269 MaxRegenStat 0;
BA_ "GenSigTimeoutTime_SGW" SG_ 269 MaxRegenStat 0;
BA_ "GenSigTimeoutTime_TCM" SG_ 269 MaxRegenStat 0;
BA_ "SystemSignalLongSymbol" SG_ 269 MessageCounter_HYBRID_POWERTRAI_10D "MessageCounter_HYBRID_POWERTRAIN2";
BA_ "GenSigTimeoutTime_AGSM" SG_ 269 MessageCounter_HYBRID_POWERTRAI_10D 0;
BA_ "GenSigTimeoutTime_ASBS" SG_ 269 MessageCounter_HYBRID_POWERTRAI_10D 0;
BA_ "GenSigTimeoutTime_BCM" SG_ 269 MessageCounter_HYBRID_POWERTRAI_10D 0;
BA_ "GenSigTimeoutTime_CADM" SG_ 269 MessageCounter_HYBRID_POWERTRAI_10D 0;
BA_ "GenSigTimeoutTime_DMSM" SG_ 269 MessageCounter_HYBRID_POWERTRAI_10D 0;
BA_ "GenSigTimeoutTime_DTCM" SG_ 269 MessageCounter_HYBRID_POWERTRAI_10D 0;
BA_ "GenSigTimeoutTime_ELSDM" SG_ 269 MessageCounter_HYBRID_POWERTRAI_10D 0;
BA_ "GenSigTimeoutTime_ESL" SG_ 269 MessageCounter_HYBRID_POWERTRAI_10D 0;
BA_ "GenSigTimeoutTime_GNMM" SG_ 269 MessageCounter_HYBRID_POWERTRAI_10D 0;
BA_ "GenSigTimeoutTime_HCP" SG_ 269 MessageCounter_HYBRID_POWERTRAI_10D 0;
BA_ "GenSigTimeoutTime_IPC" SG_ 269 MessageCounter_HYBRID_POWERTRAI_10D 0;
BA_ "GenSigTimeoutTime_RFHM" SG_ 269 MessageCounter_HYBRID_POWERTRAI_10D 0;
BA_ "GenSigTimeoutTime_SGW" SG_ 269 MessageCounter_HYBRID_POWERTRAI_10D 0;
BA_ "GenSigTimeoutTime_AGSM" SG_ 269 CODE_CLR_HCP 0;
BA_ "GenSigTimeoutTime_ASBS" SG_ 269 CODE_CLR_HCP 0;
BA_ "GenSigTimeoutTime_BCM" SG_ 269 CODE_CLR_HCP 0;
BA_ "GenSigTimeoutTime_BSM" SG_ 269 CODE_CLR_HCP 0;
BA_ "GenSigTimeoutTime_CADM" SG_ 269 CODE_CLR_HCP 0;
BA_ "GenSigTimeoutTime_DMSM" SG_ 269 CODE_CLR_HCP 0;
BA_ "GenSigTimeoutTime_DTCM" SG_ 269 CODE_CLR_HCP 0;
BA_ "GenSigTimeoutTime_ELSDM" SG_ 269 CODE_CLR_HCP 0;
BA_ "GenSigTimeoutTime_ESL" SG_ 269 CODE_CLR_HCP 0;
BA_ "GenSigTimeoutTime_GNMM" SG_ 269 CODE_CLR_HCP 0;
BA_ "GenSigTimeoutTime_HCP" SG_ 269 CODE_CLR_HCP 0;
BA_ "GenSigTimeoutTime_IPC" SG_ 269 CODE_CLR_HCP 0;
BA_ "GenSigTimeoutTime_RFHM" SG_ 269 CODE_CLR_HCP 0;
BA_ "GenSigTimeoutTime_SGW" SG_ 269 CODE_CLR_HCP 0;
BA_ "GenSigTimeoutTime_TCM" SG_ 269 CODE_CLR_HCP 0;
BA_ "GenSigTimeoutTime_AGSM" SG_ 269 EstRegenBrkFWTorq 0;
BA_ "GenSigTimeoutTime_ASBS" SG_ 269 EstRegenBrkFWTorq 0;
BA_ "GenSigTimeoutTime_BCM" SG_ 269 EstRegenBrkFWTorq 0;
BA_ "GenSigTimeoutTime_CADM" SG_ 269 EstRegenBrkFWTorq 0;
BA_ "GenSigTimeoutTime_DMSM" SG_ 269 EstRegenBrkFWTorq 0;
BA_ "GenSigTimeoutTime_DTCM" SG_ 269 EstRegenBrkFWTorq 0;
BA_ "GenSigTimeoutTime_ELSDM" SG_ 269 EstRegenBrkFWTorq 0;
BA_ "GenSigTimeoutTime_ESL" SG_ 269 EstRegenBrkFWTorq 0;
BA_ "GenSigTimeoutTime_GNMM" SG_ 269 EstRegenBrkFWTorq 0;
BA_ "GenSigTimeoutTime_HCP" SG_ 269 EstRegenBrkFWTorq 0;
BA_ "GenSigTimeoutTime_IPC" SG_ 269 EstRegenBrkFWTorq 0;
BA_ "GenSigTimeoutTime_RFHM" SG_ 269 EstRegenBrkFWTorq 0;
BA_ "GenSigTimeoutTime_SGW" SG_ 269 EstRegenBrkFWTorq 0;
BA_ "GenSigTimeoutTime_AGSM" SG_ 269 REPRGD_PFC_CLR_HCP 0;
BA_ "GenSigTimeoutTime_ASBS" SG_ 269 REPRGD_PFC_CLR_HCP 0;
BA_ "GenSigTimeoutTime_BCM" SG_ 269 REPRGD_PFC_CLR_HCP 0;
BA_ "GenSigTimeoutTime_BSM" SG_ 269 REPRGD_PFC_CLR_HCP 0;
BA_ "GenSigTimeoutTime_CADM" SG_ 269 REPRGD_PFC_CLR_HCP 0;
BA_ "GenSigTimeoutTime_DMSM" SG_ 269 REPRGD_PFC_CLR_HCP 0;
BA_ "GenSigTimeoutTime_DTCM" SG_ 269 REPRGD_PFC_CLR_HCP 0;
BA_ "GenSigTimeoutTime_ELSDM" SG_ 269 REPRGD_PFC_CLR_HCP 0;
BA_ "GenSigTimeoutTime_ESL" SG_ 269 REPRGD_PFC_CLR_HCP 0;
BA_ "GenSigTimeoutTime_GNMM" SG_ 269 REPRGD_PFC_CLR_HCP 0;
BA_ "GenSigTimeoutTime_HCP" SG_ 269 REPRGD_PFC_CLR_HCP 0;
BA_ "GenSigTimeoutTime_IPC" SG_ 269 REPRGD_PFC_CLR_HCP 0;
BA_ "GenSigTimeoutTime_RFHM" SG_ 269 REPRGD_PFC_CLR_HCP 0;
BA_ "GenSigTimeoutTime_SGW" SG_ 269 REPRGD_PFC_CLR_HCP 0;
BA_ "GenSigTimeoutTime_TCM" SG_ 269 REPRGD_PFC_CLR_HCP 0;
BA_ "GenSigTimeoutTime_ADCAM" SG_ 2654486550 SourceNodeIdentifier_1E384016 0;
BA_ "GenSigTimeoutTime_EVCU2" SG_ 2654486550 SourceNodeIdentifier_1E384016 0;
BA_ "GenSigTimeoutTime_VDCM" SG_ 2654486550 SourceNodeIdentifier_1E384016 0;
BA_ "GenSigTimeoutTime_ADCAM" SG_ 2654486550 CBV_bit0_RepeatMessageRequestBit_1E384016 0;
BA_ "GenSigTimeoutTime_EVCU2" SG_ 2654486550 CBV_bit0_RepeatMessageRequestBit_1E384016 0;
BA_ "GenSigTimeoutTime_VDCM" SG_ 2654486550 CBV_bit0_RepeatMessageRequestBit_1E384016 0;
BA_ "GenSigTimeoutTime_ADCAM" SG_ 2654486550 CBV_bit1_1E384016 0;
BA_ "GenSigTimeoutTime_EVCU2" SG_ 2654486550 CBV_bit1_1E384016 0;
BA_ "GenSigTimeoutTime_VDCM" SG_ 2654486550 CBV_bit1_1E384016 0;
BA_ "GenSigTimeoutTime_ADCAM" SG_ 2654486550 CBV_bit2_1E384016 0;
BA_ "GenSigTimeoutTime_EVCU2" SG_ 2654486550 CBV_bit2_1E384016 0;
BA_ "GenSigTimeoutTime_VDCM" SG_ 2654486550 CBV_bit2_1E384016 0;
BA_ "GenSigTimeoutTime_ADCAM" SG_ 2654486550 CBV_bit3_NMCoordinatorBit_1E384016 0;
BA_ "GenSigTimeoutTime_EVCU2" SG_ 2654486550 CBV_bit3_NMCoordinatorBit_1E384016 0;
BA_ "GenSigTimeoutTime_VDCM" SG_ 2654486550 CBV_bit3_NMCoordinatorBit_1E384016 0;
BA_ "GenSigTimeoutTime_ADCAM" SG_ 2654486550 CBV_bit4_ActiveWakeupBit_1E384016 0;
BA_ "GenSigTimeoutTime_EVCU2" SG_ 2654486550 CBV_bit4_ActiveWakeupBit_1E384016 0;
BA_ "GenSigTimeoutTime_VDCM" SG_ 2654486550 CBV_bit4_ActiveWakeupBit_1E384016 0;
BA_ "GenSigTimeoutTime_ADCAM" SG_ 2654486550 CBV_bit5_1E384016 0;
BA_ "GenSigTimeoutTime_EVCU2" SG_ 2654486550 CBV_bit5_1E384016 0;
BA_ "GenSigTimeoutTime_VDCM" SG_ 2654486550 CBV_bit5_1E384016 0;
BA_ "GenSigTimeoutTime_ADCAM" SG_ 2654486550 CBV_bit6_PartialNtwInfBit_1E384016 0;
BA_ "GenSigTimeoutTime_EVCU2" SG_ 2654486550 CBV_bit6_PartialNtwInfBit_1E384016 0;
BA_ "GenSigTimeoutTime_VDCM" SG_ 2654486550 CBV_bit6_PartialNtwInfBit_1E384016 0;
BA_ "GenSigTimeoutTime_ADCAM" SG_ 2654486550 CBV_bit7_1E384016 0;
BA_ "GenSigTimeoutTime_EVCU2" SG_ 2654486550 CBV_bit7_1E384016 0;
BA_ "GenSigTimeoutTime_VDCM" SG_ 2654486550 CBV_bit7_1E384016 0;
BA_ "GenSigTimeoutTime_AGSM" SG_ 2654486550 SourceNodeIdentifier_1E384016 0;
BA_ "GenSigTimeoutTime_ASBS" SG_ 2654486550 SourceNodeIdentifier_1E384016 0;
BA_ "GenSigTimeoutTime_BCM" SG_ 2654486550 SourceNodeIdentifier_1E384016 0;
BA_ "GenSigTimeoutTime_BSM" SG_ 2654486550 SourceNodeIdentifier_1E384016 0;
BA_ "GenSigTimeoutTime_CADM" SG_ 2654486550 SourceNodeIdentifier_1E384016 0;
BA_ "GenSigTimeoutTime_DMSM" SG_ 2654486550 SourceNodeIdentifier_1E384016 0;
BA_ "GenSigTimeoutTime_DTCM" SG_ 2654486550 SourceNodeIdentifier_1E384016 0;
BA_ "GenSigTimeoutTime_ECM" SG_ 2654486550 SourceNodeIdentifier_1E384016 0;
BA_ "GenSigTimeoutTime_ELSDM" SG_ 2654486550 SourceNodeIdentifier_1E384016 0;
BA_ "GenSigTimeoutTime_ESL" SG_ 2654486550 SourceNodeIdentifier_1E384016 0;
BA_ "GenSigTimeoutTime_GNMM" SG_ 2654486550 SourceNodeIdentifier_1E384016 0;
BA_ "GenSigTimeoutTime_HCP" SG_ 2654486550 SourceNodeIdentifier_1E384016 0;
BA_ "GenSigTimeoutTime_IPC" SG_ 2654486550 SourceNodeIdentifier_1E384016 0;
BA_ "GenSigTimeoutTime_RFHM" SG_ 2654486550 SourceNodeIdentifier_1E384016 0;
BA_ "GenSigTimeoutTime_SGW" SG_ 2654486550 SourceNodeIdentifier_1E384016 0;
BA_ "GenSigTimeoutTime_TCM" SG_ 2654486550 SourceNodeIdentifier_1E384016 0;
BA_ "GenSigTimeoutTime_AGSM" SG_ 2654486550 CBV_bit0_RepeatMessageRequestBit_1E384016 0;
BA_ "GenSigTimeoutTime_ASBS" SG_ 2654486550 CBV_bit0_RepeatMessageRequestBit_1E384016 0;
BA_ "GenSigTimeoutTime_BCM" SG_ 2654486550 CBV_bit0_RepeatMessageRequestBit_1E384016 0;
BA_ "GenSigTimeoutTime_BSM" SG_ 2654486550 CBV_bit0_RepeatMessageRequestBit_1E384016 0;
BA_ "GenSigTimeoutTime_CADM" SG_ 2654486550 CBV_bit0_RepeatMessageRequestBit_1E384016 0;
BA_ "GenSigTimeoutTime_DMSM" SG_ 2654486550 CBV_bit0_RepeatMessageRequestBit_1E384016 0;
BA_ "GenSigTimeoutTime_DTCM" SG_ 2654486550 CBV_bit0_RepeatMessageRequestBit_1E384016 0;
BA_ "GenSigTimeoutTime_ECM" SG_ 2654486550 CBV_bit0_RepeatMessageRequestBit_1E384016 0;
BA_ "GenSigTimeoutTime_ELSDM" SG_ 2654486550 CBV_bit0_RepeatMessageRequestBit_1E384016 0;
BA_ "GenSigTimeoutTime_ESL" SG_ 2654486550 CBV_bit0_RepeatMessageRequestBit_1E384016 0;
BA_ "GenSigTimeoutTime_GNMM" SG_ 2654486550 CBV_bit0_RepeatMessageRequestBit_1E384016 0;
BA_ "GenSigTimeoutTime_HCP" SG_ 2654486550 CBV_bit0_RepeatMessageRequestBit_1E384016 0;
BA_ "GenSigTimeoutTime_IPC" SG_ 2654486550 CBV_bit0_RepeatMessageRequestBit_1E384016 0;
BA_ "GenSigTimeoutTime_RFHM" SG_ 2654486550 CBV_bit0_RepeatMessageRequestBit_1E384016 0;
BA_ "GenSigTimeoutTime_SGW" SG_ 2654486550 CBV_bit0_RepeatMessageRequestBit_1E384016 0;
BA_ "GenSigTimeoutTime_TCM" SG_ 2654486550 CBV_bit0_RepeatMessageRequestBit_1E384016 0;
BA_ "GenSigTimeoutTime_IPC" SG_ 276 Hyb_MotorB_Speed 0;
BA_ "GenSigTimeoutTime_RFHM" SG_ 276 Hyb_MotorB_Speed 0;
BA_ "GenSigTimeoutTime_SGW" SG_ 276 Hyb_MotorB_Speed 0;
BA_ "GenSigTimeoutTime_TCM" SG_ 276 Hyb_MotorB_Speed 0;
BA_ "GenSigTimeoutTime_AGSM" SG_ 276 NiTi_Disable 0;
BA_ "GenSigTimeoutTime_ASBS" SG_ 276 NiTi_Disable 0;
BA_ "GenSigTimeoutTime_BCM" SG_ 276 NiTi_Disable 0;
BA_ "GenSigTimeoutTime_BSM" SG_ 276 NiTi_Disable 0;
BA_ "GenSigTimeoutTime_CADM" SG_ 276 NiTi_Disable 0;
BA_ "GenSigTimeoutTime_DMSM" SG_ 276 NiTi_Disable 0;
BA_ "GenSigTimeoutTime_DTCM" SG_ 276 NiTi_Disable 0;
BA_ "GenSigTimeoutTime_ELSDM" SG_ 276 NiTi_Disable 0;
BA_ "GenSigTimeoutTime_ESL" SG_ 276 NiTi_Disable 0;
BA_ "GenSigTimeoutTime_GNMM" SG_ 276 NiTi_Disable 0;
BA_ "GenSigTimeoutTime_HCP" SG_ 276 NiTi_Disable 0;
BA_ "GenSigTimeoutTime_IPC" SG_ 276 NiTi_Disable 0;
BA_ "GenSigTimeoutTime_RFHM" SG_ 276 NiTi_Disable 0;
BA_ "GenSigTimeoutTime_SGW" SG_ 276 NiTi_Disable 0;
BA_ "GenSigTimeoutTime_TCM" SG_ 276 NiTi_Disable 0;
BA_ "GenSigStartValue" SG_ 276 MinCreepWheelTrq 8191;
BA_ "GenSigTimeoutTime_AGSM" SG_ 276 MinCreepWheelTrq 0;
BA_ "GenSigTimeoutTime_HCP" SG_ 2654486582 SourceNodeIdentifier_1E384036 0;
BA_ "GenSigTimeoutTime_IPC" SG_ 2654486582 SourceNodeIdentifier_1E384036 0;
BA_ "GenSigTimeoutTime_RFHM" SG_ 2654486582 SourceNodeIdentifier_1E384036 0;
BA_ "GenSigTimeoutTime_SGW" SG_ 2654486582 SourceNodeIdentifier_1E384036 0;
BA_ "GenSigTimeoutTime_TCM" SG_ 2654486582 SourceNodeIdentifier_1E384036 0;
BA_ "GenSigTimeoutTime_HCP" SG_ 276 GeneratorSetpointOverride 0;
BA_ "GenSigTimeoutTime_IPC" SG_ 276 GeneratorSetpointOverride 0;
BA_ "GenSigTimeoutTime_RFHM" SG_ 276 GeneratorSetpointOverride 0;
BA_ "GenSigTimeoutTime_SGW" SG_ 276 GeneratorSetpointOverride 0;
BA_ "GenSigTimeoutTime_TCM" SG_ 276 GeneratorSetpointOverride 0;
BA_ "GenSigTimeoutTime_AGSM" SG_ 276 HEV_ESS_Mode 0;
BA_ "GenSigTimeoutTime_ASBS" SG_ 276 HEV_ESS_Mode 0;
BA_ "GenSigTimeoutTime_BCM" SG_ 276 HEV_ESS_Mode 0;
BA_ "GenSigTimeoutTime_BSM" SG_ 276 HEV_ESS_Mode 0;
BA_ "GenSigTimeoutTime_CADM" SG_ 276 HEV_ESS_Mode 0;
BA_ "GenSigTimeoutTime_DMSM" SG_ 276 HEV_ESS_Mode 0;
BA_ "GenSigTimeoutTime_DTCM" SG_ 276 HEV_ESS_Mode 0;
BA_ "GenSigTimeoutTime_ELSDM" SG_ 276 HEV_ESS_Mode 0;
BA_ "GenSigTimeoutTime_ESL" SG_ 276 HEV_ESS_Mode 0;
BA_ "GenSigTimeoutTime_GNMM" SG_ 276 HEV_ESS_Mode 0;
BA_ "GenSigTimeoutTime_HCP" SG_ 276 HEV_ESS_Mode 0;
BA_ "GenSigTimeoutTime_IPC" SG_ 276 HEV_ESS_Mode 0;
BA_ "GenSigTimeoutTime_RFHM" SG_ 276 HEV_ESS_Mode 0;
BA_ "GenSigTimeoutTime_SGW" SG_ 276 HEV_ESS_Mode 0;
BA_ "GenSigTimeoutTime_TCM" SG_ 276 HEV_ESS_Mode 0;
BA_ "GenSigTimeoutTime_AGSM" SG_ 276 Hyb_EngStrtStopType 0;
BA_ "GenSigTimeoutTime_ASBS" SG_ 276 Hyb_EngStrtStopType 0;
BA_ "GenSigTimeoutTime_BCM" SG_ 276 Hyb_EngStrtStopType 0;
BA_ "GenSigTimeoutTime_BSM" SG_ 276 Hyb_EngStrtStopType 0;
BA_ "GenSigTimeoutTime_CADM" SG_ 276 Hyb_EngStrtStopType 0;
BA_ "GenSigTimeoutTime_DMSM" SG_ 276 Hyb_EngStrtStopType 0;
BA_ "GenSigTimeoutTime_DTCM" SG_ 276 Hyb_EngStrtStopType 0;
BA_ "GenSigTimeoutTime_ELSDM" SG_ 276 Hyb_EngStrtStopType 0;
BA_ "GenSigTimeoutTime_ESL" SG_ 276 Hyb_EngStrtStopType 0;
BA_ "GenSigTimeoutTime_GNMM" SG_ 276 Hyb_EngStrtStopType 0;
BA_ "GenSigTimeoutTime_HCP" SG_ 276 Hyb_EngStrtStopType 0;
BA_ "GenSigTimeoutTime_IPC" SG_ 276 Hyb_EngStrtStopType 0;
BA_ "GenSigTimeoutTime_RFHM" SG_ 276 Hyb_EngStrtStopType 0;
BA_ "GenSigTimeoutTime_SGW" SG_ 276 Hyb_EngStrtStopType 0;
BA_ "GenSigTimeoutTime_TCM" SG_ 276 Hyb_EngStrtStopType 0;
BA_ "GenSigTimeoutTime_AGSM" SG_ 276 HCP_Comm_Fail_CAN 0;
BA_ "GenSigTimeoutTime_ASBS" SG_ 276 HCP_Comm_Fail_CAN 0;
BA_ "GenSigTimeoutTime_BCM" SG_ 276 HCP_Comm_Fail_CAN 0;
BA_ "GenSigTimeoutTime_BSM" SG_ 276 HCP_Comm_Fail_CAN 0;
BA_ "GenSigTimeoutTime_CADM" SG_ 276 HCP_Comm_Fail_CAN 0;
BA_ "GenSigTimeoutTime_DMSM" SG_ 276 HCP_Comm_Fail_CAN 0;
BA_ "GenSigTimeoutTime_DTCM" SG_ 276 HCP_Comm_Fail_CAN 0;
BA_ "GenSigTimeoutTime_ELSDM" SG_ 276 HCP_Comm_Fail_CAN 0;
BA_ "GenSigTimeoutTime_ESL" SG_ 276 HCP_Comm_Fail_CAN 0;
BA_ "GenSigTimeoutTime_GNMM" SG_ 276 HCP_Comm_Fail_CAN 0;
BA_ "GenSigTimeoutTime_HCP" SG_ 276 HCP_Comm_Fail_CAN 0;
BA_ "GenSigTimeoutTime_IPC" SG_ 276 HCP_Comm_Fail_CAN 0;
BA_ "GenSigTimeoutTime_RFHM" SG_ 276 HCP_Comm_Fail_CAN 0;
BA_ "GenSigTimeoutTime_SGW" SG_ 276 HCP_Comm_Fail_CAN 0;
BA_ "GenSigTimeoutTime_AGSM" SG_ 276 HybFstTrqRq_Trans 0;
BA_ "GenSigTimeoutTime_ASBS" SG_ 276 HybFstTrqRq_Trans 0;
BA_ "GenSigTimeoutTime_BCM" SG_ 276 HybFstTrqRq_Trans 0;
BA_ "GenSigTimeoutTime_BSM" SG_ 276 HybFstTrqRq_Trans 0;
BA_ "GenSigTimeoutTime_CADM" SG_ 276 HybFstTrqRq_Trans 0;
BA_ "GenSigTimeoutTime_DMSM" SG_ 276 HybFstTrqRq_Trans 0;
BA_ "GenSigTimeoutTime_DTCM" SG_ 276 HybFstTrqRq_Trans 0;
BA_ "GenSigTimeoutTime_ELSDM" SG_ 276 HybFstTrqRq_Trans 0;
BA_ "GenSigTimeoutTime_ESL" SG_ 276 HybFstTrqRq_Trans 0;
BA_ "GenSigTimeoutTime_GNMM" SG_ 276 HybFstTrqRq_Trans 0;
BA_ "GenSigTimeoutTime_HCP" SG_ 276 HybFstTrqRq_Trans 0;
BA_ "GenSigTimeoutTime_IPC" SG_ 276 HybFstTrqRq_Trans 0;
BA_ "GenSigTimeoutTime_RFHM" SG_ 276 HybFstTrqRq_Trans 0;
BA_ "GenSigTimeoutTime_SGW" SG_ 276 HybFstTrqRq_Trans 0;
BA_ "GenSigTimeoutTime_TCM" SG_ 276 HybFstTrqRq_Trans 0;
BA_ "GenSigTimeoutTime_AGSM" SG_ 276 PropulsionSystemActive 0;
BA_ "GenSigTimeoutTime_ASBS" SG_ 276 PropulsionSystemActive 0;
BA_ "GenSigTimeoutTime_DMSM" SG_ 276 PropulsionSystemActive 0;
BA_ "GenSigTimeoutTime_DTCM" SG_ 276 PropulsionSystemActive 0;
BA_ "GenSigTimeoutTime_ELSDM" SG_ 276 PropulsionSystemActive 0;
BA_ "GenSigTimeoutTime_ESL" SG_ 276 PropulsionSystemActive 0;
BA_ "GenSigTimeoutTime_GNMM" SG_ 276 PropulsionSystemActive 0;
BA_ "GenSigTimeoutTime_HCP" SG_ 276 PropulsionSystemActive 0;
BA_ "GenSigTimeoutTime_RFHM" SG_ 276 PropulsionSystemActive 0;
BA_ "GenSigTimeoutTime_AGSM" SG_ 276 CRC_HYBRID_POWERTRAIN1 0;
BA_ "GenSigTimeoutTime_ASBS" SG_ 276 CRC_HYBRID_POWERTRAIN1 0;
BA_ "GenSigTimeoutTime_BCM" SG_ 276 CRC_HYBRID_POWERTRAIN1 0;
BA_ "GenSigTimeoutTime_DMSM" SG_ 276 CRC_HYBRID_POWERTRAIN1 0;
BA_ "GenSigTimeoutTime_DTCM" SG_ 276 CRC_HYBRID_POWERTRAIN1 0;
BA_ "GenSigTimeoutTime_ELSDM" SG_ 276 CRC_HYBRID_POWERTRAIN1 0;
BA_ "GenSigTimeoutTime_ESL" SG_ 276 CRC_HYBRID_POWERTRAIN1 0;
BA_ "GenSigTimeoutTime_GNMM" SG_ 276 CRC_HYBRID_POWERTRAIN1 0;
BA_ "GenSigTimeoutTime_HCP" SG_ 276 CRC_HYBRID_POWERTRAIN1 0;
BA_ "GenSigTimeoutTime_RFHM" SG_ 276 CRC_HYBRID_POWERTRAIN1 0;
BA_ "GenSigTimeoutTime_SGW" SG_ 276 CRC_HYBRID_POWERTRAIN1 0;
BA_ "GenSigTimeoutTime_AGSM" SG_ 276 ECMPrepIdleRes 0;
BA_ "GenSigTimeoutTime_ASBS" SG_ 276 ECMPrepIdleRes 0;
BA_ "GenSigTimeoutTime_BCM" SG_ 276 ECMPrepIdleRes 0;
BA_ "GenSigTimeoutTime_BSM" SG_ 276 ECMPrepIdleRes 0;
BA_ "GenSigTimeoutTime_CADM" SG_ 276 ECMPrepIdleRes 0;
BA_ "GenSigTimeoutTime_DMSM" SG_ 276 ECMPrepIdleRes 0;
BA_ "GenSigTimeoutTime_DTCM" SG_ 276 ECMPrepIdleRes 0;
BA_ "GenSigTimeoutTime_ELSDM" SG_ 276 ECMPrepIdleRes 0;
BA_ "GenSigTimeoutTime_ESL" SG_ 276 ECMPrepIdleRes 0;
BA_ "GenSigTimeoutTime_GNMM" SG_ 276 ECMPrepIdleRes 0;
BA_ "GenSigTimeoutTime_HCP" SG_ 276 ECMPrepIdleRes 0;
BA_ "GenSigTimeoutTime_IPC" SG_ 276 ECMPrepIdleRes 0;
BA_ "GenSigTimeoutTime_RFHM" SG_ 276 ECMPrepIdleRes 0;
BA_ "GenSigTimeoutTime_SGW" SG_ 276 ECMPrepIdleRes 0;
BA_ "GenSigTimeoutTime_TCM" SG_ 276 ECMPrepIdleRes 0;
BA_ "GenSigTimeoutTime_AGSM" SG_ 276 Eng_Off_Allowed 0;
BA_ "GenSigTimeoutTime_ASBS" SG_ 276 Eng_Off_Allowed 0;
BA_ "GenSigTimeoutTime_BCM" SG_ 276 Eng_Off_Allowed 0;
BA_ "GenSigTimeoutTime_BSM" SG_ 276 Eng_Off_Allowed 0;
BA_ "GenSigTimeoutTime_CADM" SG_ 276 Eng_Off_Allowed 0;
BA_ "GenSigTimeoutTime_DMSM" SG_ 276 Eng_Off_Allowed 0;
BA_ "GenSigTimeoutTime_DTCM" SG_ 276 Eng_Off_Allowed 0;
BA_ "GenSigTimeoutTime_ELSDM" SG_ 276 Eng_Off_Allowed 0;
BA_ "GenSigTimeoutTime_ESL" SG_ 276 Eng_Off_Allowed 0;
BA_ "GenSigTimeoutTime_GNMM" SG_ 276 Eng_Off_Allowed 0;
BA_ "GenSigTimeoutTime_HCP" SG_ 276 Eng_Off_Allowed 0;
BA_ "GenSigTimeoutTime_IPC" SG_ 276 Eng_Off_Allowed 0;
BA_ "GenSigTimeoutTime_RFHM" SG_ 276 Eng_Off_Allowed 0;
BA_ "GenSigTimeoutTime_SGW" SG_ 276 Eng_Off_Allowed 0;
BA_ "GenSigTimeoutTime_TCM" SG_ 276 Eng_Off_Allowed 0;
BA_ "GenSigTimeoutTime_AGSM" SG_ 276 HCP_VTD_Freeze 0;
BA_ "GenSigTimeoutTime_ASBS" SG_ 276 HCP_VTD_Freeze 0;
BA_ "GenSigTimeoutTime_BCM" SG_ 276 HCP_VTD_Freeze 0;
BA_ "GenSigTimeoutTime_BSM" SG_ 276 HCP_VTD_Freeze 0;
BA_ "GenSigTimeoutTime_CADM" SG_ 276 HCP_VTD_Freeze 0;
BA_ "GenSigTimeoutTime_DMSM" SG_ 276 HCP_VTD_Freeze 0;
BA_ "GenSigTimeoutTime_DTCM" SG_ 276 HCP_VTD_Freeze 0;
BA_ "GenSigTimeoutTime_ELSDM" SG_ 276 HCP_VTD_Freeze 0;
BA_ "GenSigTimeoutTime_ESL" SG_ 276 HCP_VTD_Freeze 0;
BA_ "GenSigTimeoutTime_GNMM" SG_ 276 HCP_VTD_Freeze 0;
BA_ "GenSigTimeoutTime_HCP" SG_ 276 HCP_VTD_Freeze 0;
BA_ "GenSigTimeoutTime_IPC" SG_ 276 HCP_VTD_Freeze 0;
BA_ "GenSigTimeoutTime_RFHM" SG_ 276 HCP_VTD_Freeze 0;
BA_ "GenSigTimeoutTime_SGW" SG_ 276 HCP_VTD_Freeze 0;
BA_ "GenSigTimeoutTime_TCM" SG_ 276 HCP_VTD_Freeze 0;
BA_ "GenSigTimeoutTime_AGSM" SG_ 276 Hyb_SumTorqueStatic 0;
BA_ "GenSigTimeoutTime_ASBS" SG_ 276 Hyb_SumTorqueStatic 0;
BA_ "GenSigTimeoutTime_BCM" SG_ 276 Hyb_SumTorqueStatic 0;
BA_ "GenSigTimeoutTime_BSM" SG_ 276 Hyb_SumTorqueStatic 0;
BA_ "GenSigTimeoutTime_CADM" SG_ 276 Hyb_SumTorqueStatic 0;
BA_ "GenSigTimeoutTime_DMSM" SG_ 276 Hyb_SumTorqueStatic 0;
BA_ "GenSigTimeoutTime_DTCM" SG_ 276 Hyb_SumTorqueStatic 0;
BA_ "GenSigTimeoutTime_ELSDM" SG_ 276 Hyb_SumTorqueStatic 0;
BA_ "GenSigTimeoutTime_ESL" SG_ 276 Hyb_SumTorqueStatic 0;
BA_ "GenSigTimeoutTime_GNMM" SG_ 271 MinPrdtdEngRunTorqCapV 0;
BA_ "GenSigTimeoutTime_IPC" SG_ 271 MinPrdtdEngRunTorqCapV 0;
BA_ "GenSigTimeoutTime_RFHM" SG_ 271 MinPrdtdEngRunTorqCapV 0;
BA_ "GenSigTimeoutTime_SGW" SG_ 271 MinPrdtdEngRunTorqCapV 0;
BA_ "GenSigTimeoutTime_TCM" SG_ 271 MinPrdtdEngRunTorqCapV 0;
BA_ "GenSigTimeoutTime_AGSM" SG_ 271 PT_CrnkAct 0;
BA_ "GenSigTimeoutTime_ASBS" SG_ 271 PT_CrnkAct 0;
BA_ "GenSigTimeoutTime_BCM" SG_ 271 PT_CrnkAct 0;
BA_ "GenSigTimeoutTime_BSM" SG_ 271 PT_CrnkAct 0;
BA_ "GenSigTimeoutTime_CADM" SG_ 271 PT_CrnkAct 0;
BA_ "GenSigTimeoutTime_DMSM" SG_ 271 PT_CrnkAct 0;
BA_ "GenSigTimeoutTime_DTCM" SG_ 271 PT_CrnkAct 0;
BA_ "GenSigTimeoutTime_ECM" SG_ 271 PT_CrnkAct 0;
BA_ "GenSigTimeoutTime_ELSDM" SG_ 271 PT_CrnkAct 0;
BA_ "GenSigTimeoutTime_ESL" SG_ 271 PT_CrnkAct 0;
BA_ "GenSigTimeoutTime_GNMM" SG_ 271 PT_CrnkAct 0;
BA_ "GenSigTimeoutTime_IPC" SG_ 271 PT_CrnkAct 0;
BA_ "GenSigTimeoutTime_RFHM" SG_ 271 PT_CrnkAct 0;
BA_ "GenSigTimeoutTime_SGW" SG_ 271 PT_CrnkAct 0;
BA_ "GenSigTimeoutTime_TCM" SG_ 271 PT_CrnkAct 0;
BA_ "GenSigTimeoutTime_AGSM" SG_ 271 PTCrnkAbrted 0;
BA_ "GenSigTimeoutTime_ASBS" SG_ 271 PTCrnkAbrted 0;
BA_ "GenSigTimeoutTime_BCM" SG_ 271 PTCrnkAbrted 0;
BA_ "GenSigTimeoutTime_BSM" SG_ 271 PTCrnkAbrted 0;
BA_ "GenSigTimeoutTime_CADM" SG_ 271 PTCrnkAbrted 0;
BA_ "GenSigTimeoutTime_DMSM" SG_ 271 PTCrnkAbrted 0;
BA_ "GenSigTimeoutTime_DTCM" SG_ 271 PTCrnkAbrted 0;
BA_ "GenSigTimeoutTime_ECM" SG_ 271 PTCrnkAbrted 0;
BA_ "GenSigTimeoutTime_ELSDM" SG_ 271 PTCrnkAbrted 0;
BA_ "GenSigTimeoutTime_ESL" SG_ 271 PTCrnkAbrted 0;
BA_ "GenSigTimeoutTime_GNMM" SG_ 271 PTCrnkAbrted 0;
BA_ "GenSigTimeoutTime_IPC" SG_ 271 PTCrnkAbrted 0;
BA_ "GenSigTimeoutTime_RFHM" SG_ 271 PTCrnkAbrted 0;
BA_ "GenSigTimeoutTime_SGW" SG_ 271 PTCrnkAbrted 0;
BA_ "GenSigTimeoutTime_TCM" SG_ 271 PTCrnkAbrted 0;
BA_ "GenSigStartValue" SG_ 271 Sum_FW_ID_Fst 1;
BA_ "GenSigTimeoutTime_AGSM" SG_ 271 Sum_FW_ID_Fst 0;
BA_ "GenSigTimeoutTime_ASBS" SG_ 271 Sum_FW_ID_Fst 0;
BA_ "GenSigTimeoutTime_BCM" SG_ 271 Sum_FW_ID_Fst 0;
BA_ "GenSigTimeoutTime_BSM" SG_ 271 Sum_FW_ID_Fst 0;
BA_ "GenSigTimeoutTime_CADM" SG_ 271 Sum_FW_ID_Fst 0;
BA_ "GenSigTimeoutTime_DMSM" SG_ 271 Sum_FW_ID_Fst 0;
BA_ "GenSigTimeoutTime_DTCM" SG_ 271 Sum_FW_ID_Fst 0;
BA_ "GenSigTimeoutTime_ECM" SG_ 271 Sum_FW_ID_Fst 0;
BA_ "GenSigTimeoutTime_ELSDM" SG_ 271 Sum_FW_ID_Fst 0;
BA_ "GenSigTimeoutTime_ESL" SG_ 271 Sum_FW_ID_Fst 0;
BA_ "GenSigTimeoutTime_GNMM" SG_ 271 Sum_FW_ID_Fst 0;
BA_ "GenSigTimeoutTime_IPC" SG_ 271 Sum_FW_ID_Fst 0;
BA_ "GenSigTimeoutTime_RFHM" SG_ 271 Sum_FW_ID_Fst 0;
BA_ "GenSigTimeoutTime_SGW" SG_ 271 Sum_FW_ID_Fst 0;
BA_ "GenSigTimeoutTime_TCM" SG_ 271 Sum_FW_ID_Fst 0;
BA_ "GenSigStartValue" SG_ 271 Sum_FW_ID_Slw 1;
BA_ "GenSigTimeoutTime_AGSM" SG_ 271 Sum_FW_ID_Slw 0;
BA_ "GenSigTimeoutTime_ASBS" SG_ 271 Sum_FW_ID_Slw 0;
BA_ "GenSigTimeoutTime_BCM" SG_ 271 Sum_FW_ID_Slw 0;
BA_ "GenSigTimeoutTime_BSM" SG_ 271 Sum_FW_ID_Slw 0;
BA_ "GenSigTimeoutTime_CADM" SG_ 271 Sum_FW_ID_Slw 0;
BA_ "GenSigTimeoutTime_DMSM" SG_ 271 Sum_FW_ID_Slw 0;
BA_ "GenSigTimeoutTime_DTCM" SG_ 271 Sum_FW_ID_Slw 0;
BA_ "GenSigTimeoutTime_ECM" SG_ 271 Sum_FW_ID_Slw 0;
BA_ "GenSigTimeoutTime_ELSDM" SG_ 271 Sum_FW_ID_Slw 0;
BA_ "GenSigTimeoutTime_ESL" SG_ 271 Sum_FW_ID_Slw 0;
BA_ "GenSigTimeoutTime_GNMM" SG_ 271 Sum_FW_ID_Slw 0;
BA_ "GenSigTimeoutTime_IPC" SG_ 271 Sum_FW_ID_Slw 0;
BA_ "GenSigTimeoutTime_RFHM" SG_ 271 Sum_FW_ID_Slw 0;
BA_ "GenSigTimeoutTime_SGW" SG_ 271 Sum_FW_ID_Slw 0;
BA_ "GenSigTimeoutTime_TCM" SG_ 271 Sum_FW_ID_Slw 0;
BA_ "GenSigTimeoutTime_AGSM" SG_ 271 T_max_raw 0;
BA_ "GenSigTimeoutTime_ASBS" SG_ 271 T_max_raw 0;
BA_ "GenSigTimeoutTime_BCM" SG_ 271 T_max_raw 0;
BA_ "GenSigTimeoutTime_BSM" SG_ 271 T_max_raw 0;
BA_ "GenSigTimeoutTime_CADM" SG_ 271 T_max_raw 0;
BA_ "GenSigTimeoutTime_DMSM" SG_ 271 T_max_raw 0;
BA_ "GenSigTimeoutTime_DTCM" SG_ 271 T_max_raw 0;
BA_ "GenSigTimeoutTime_ECM" SG_ 271 T_max_raw 0;
BA_ "GenSigTimeoutTime_ELSDM" SG_ 271 T_max_raw 0;
BA_ "GenSigTimeoutTime_ESL" SG_ 271 T_max_raw 0;
BA_ "GenSigTimeoutTime_GNMM" SG_ 271 T_max_raw 0;
BA_ "GenSigTimeoutTime_IPC" SG_ 271 T_max_raw 0;
BA_ "GenSigTimeoutTime_RFHM" SG_ 271 T_max_raw 0;
BA_ "GenSigTimeoutTime_SGW" SG_ 271 T_max_raw 0;
BA_ "GenSigTimeoutTime_TCM" SG_ 271 T_max_raw 0;
BA_ "GenSigTimeoutTime_AGSM" SG_ 271 MinAirFlowMinSparkTorqCapV 0;
BA_ "GenSigTimeoutTime_ASBS" SG_ 271 MinAirFlowMinSparkTorqCapV 0;
BA_ "GenSigTimeoutTime_BCM" SG_ 271 MinAirFlowMinSparkTorqCapV 0;
BA_ "GenSigTimeoutTime_BSM" SG_ 271 MinAirFlowMinSparkTorqCapV 0;
BA_ "GenSigTimeoutTime_CADM" SG_ 271 MinAirFlowMinSparkTorqCapV 0;
BA_ "GenSigTimeoutTime_DMSM" SG_ 271 MinAirFlowMinSparkTorqCapV 0;
BA_ "GenSigTimeoutTime_DTCM" SG_ 271 MinAirFlowMinSparkTorqCapV 0;
BA_ "GenSigTimeoutTime_ECM" SG_ 271 MinAirFlowMinSparkTorqCapV 0;
BA_ "GenSigTimeoutTime_ELSDM" SG_ 271 MinAirFlowMinSparkTorqCapV 0;
BA_ "GenSigTimeoutTime_ESL" SG_ 271 MinAirFlowMinSparkTorqCapV 0;
BA_ "GenSigTimeoutTime_GNMM" SG_ 271 MinAirFlowMinSparkTorqCapV 0;
BA_ "GenSigTimeoutTime_IPC" SG_ 271 MinAirFlowMinSparkTorqCapV 0;
BA_ "GenSigTimeoutTime_RFHM" SG_ 271 MinAirFlowMinSparkTorqCapV 0;
BA_ "GenSigTimeoutTime_SGW" SG_ 271 MinAirFlowMinSparkTorqCapV 0;
BA_ "GenSigTimeoutTime_TCM" SG_ 271 MinAirFlowMinSparkTorqCapV 0;
BA_ "GenSigStartValue" SG_ 271 MinEngTorqCap 938;
BA_ "GenSigTimeoutTime_AGSM" SG_ 271 MinEngTorqCap 0;
BA_ "GenSigTimeoutTime_ASBS" SG_ 271 MinEngTorqCap 0;
BA_ "GenSigTimeoutTime_BCM" SG_ 271 MinEngTorqCap 0;
BA_ "GenSigTimeoutTime_BSM" SG_ 271 MinEngTorqCap 0;
BA_ "GenSigTimeoutTime_CADM" SG_ 271 MinEngTorqCap 0;
BA_ "GenSigTimeoutTime_DMSM" SG_ 271 MinEngTorqCap 0;
BA_ "GenSigTimeoutTime_DTCM" SG_ 271 MinEngTorqCap 0;
BA_ "GenSigTimeoutTime_ECM" SG_ 271 MinEngTorqCap 0;
BA_ "GenSigTimeoutTime_ELSDM" SG_ 271 MinEngTorqCap 0;
BA_ "GenSigTimeoutTime_ESL" SG_ 271 MinEngTorqCap 0;
BA_ "GenSigTimeoutTime_GNMM" SG_ 271 MinEngTorqCap 0;
BA_ "GenSigTimeoutTime_IPC" SG_ 271 MinEngTorqCap 0;
BA_ "GenSigTimeoutTime_RFHM" SG_ 271 MinEngTorqCap 0;
BA_ "GenSigTimeoutTime_SGW" SG_ 271 MinEngTorqCap 0;
BA_ "GenSigTimeoutTime_TCM" SG_ 271 MinEngTorqCap 0;
BA_ "GenSigTimeoutTime_AGSM" SG_ 271 MinEngTorqCapV 0;
BA_ "GenSigTimeoutTime_ASBS" SG_ 271 MinEngTorqCapV 0;
BA_ "GenSigTimeoutTime_BCM" SG_ 271 MinEngTorqCapV 0;
BA_ "GenSigTimeoutTime_BSM" SG_ 271 MinEngTorqCapV 0;
BA_ "GenSigTimeoutTime_CADM" SG_ 271 MinEngTorqCapV 0;
BA_ "GenSigTimeoutTime_DMSM" SG_ 271 MinEngTorqCapV 0;
BA_ "GenSigTimeoutTime_DTCM" SG_ 271 MinEngTorqCapV 0;
BA_ "GenSigTimeoutTime_ECM" SG_ 271 MinEngTorqCapV 0;
BA_ "GenSigTimeoutTime_ELSDM" SG_ 271 MinEngTorqCapV 0;
BA_ "GenSigTimeoutTime_ESL" SG_ 271 MinEngTorqCapV 0;
BA_ "GenSigTimeoutTime_GNMM" SG_ 271 MinEngTorqCapV 0;
BA_ "GenSigTimeoutTime_IPC" SG_ 271 MinEngTorqCapV 0;
BA_ "GenSigTimeoutTime_RFHM" SG_ 271 MinEngTorqCapV 0;
BA_ "GenSigTimeoutTime_SGW" SG_ 271 MinEngTorqCapV 0;
BA_ "GenSigTimeoutTime_TCM" SG_ 271 MinEngTorqCapV 0;
BA_ "GenSigStartValue" SG_ 271 MinImmedEngTorqCap 938;
BA_ "GenSigTimeoutTime_AGSM" SG_ 271 MinImmedEngTorqCap 0;
BA_ "GenSigTimeoutTime_ASBS" SG_ 271 MinImmedEngTorqCap 0;
BA_ "GenSigTimeoutTime_BCM" SG_ 271 MinImmedEngTorqCap 0;
BA_ "GenSigTimeoutTime_BSM" SG_ 271 MinImmedEngTorqCap 0;
BA_ "GenSigTimeoutTime_CADM" SG_ 271 MinImmedEngTorqCap 0;
BA_ "GenSigTimeoutTime_DMSM" SG_ 271 MinImmedEngTorqCap 0;
BA_ "GenSigTimeoutTime_DTCM" SG_ 271 MinImmedEngTorqCap 0;
BA_ "GenSigTimeoutTime_ECM" SG_ 271 MinImmedEngTorqCap 0;
BA_ "GenSigTimeoutTime_ELSDM" SG_ 271 MinImmedEngTorqCap 0;
BA_ "GenSigTimeoutTime_ESL" SG_ 271 MinImmedEngTorqCap 0;
BA_ "GenSigTimeoutTime_GNMM" SG_ 271 MinImmedEngTorqCap 0;
BA_ "GenSigTimeoutTime_IPC" SG_ 271 MinImmedEngTorqCap 0;
BA_ "GenSigTimeoutTime_RFHM" SG_ 271 MinImmedEngTorqCap 0;
BA_ "GenSigTimeoutTime_SGW" SG_ 271 MinImmedEngTorqCap 0;
BA_ "GenSigTimeoutTime_TCM" SG_ 271 MinImmedEngTorqCap 0;
BA_ "GenSigTimeoutTime_AGSM" SG_ 271 MinImmedEngTorqCapV 0;
BA_ "GenSigTimeoutTime_ASBS" SG_ 271 MinImmedEngTorqCapV 0;
BA_ "GenSigTimeoutTime_BCM" SG_ 271 MinImmedEngTorqCapV 0;
BA_ "GenSigTimeoutTime_BSM" SG_ 271 MinImmedEngTorqCapV 0;
BA_ "GenSigTimeoutTime_CADM" SG_ 271 MinImmedEngTorqCapV 0;
BA_ "GenSigTimeoutTime_DMSM" SG_ 271 MinImmedEngTorqCapV 0;
BA_ "GenSigTimeoutTime_DTCM" SG_ 271 MinImmedEngTorqCapV 0;
BA_ "GenSigTimeoutTime_ECM" SG_ 271 MinImmedEngTorqCapV 0;
BA_ "GenSigTimeoutTime_ELSDM" SG_ 271 MinImmedEngTorqCapV 0;
BA_ "GenSigTimeoutTime_ESL" SG_ 271 MinImmedEngTorqCapV 0;
BA_ "GenSigTimeoutTime_GNMM" SG_ 271 MinImmedEngTorqCapV 0;
BA_ "GenSigTimeoutTime_IPC" SG_ 271 MinImmedEngTorqCapV 0;
BA_ "GenSigTimeoutTime_RFHM" SG_ 271 MinImmedEngTorqCapV 0;
BA_ "GenSigTimeoutTime_SGW" SG_ 271 MinImmedEngTorqCapV 0;
BA_ "GenSigTimeoutTime_TCM" SG_ 271 MinImmedEngTorqCapV 0;
BA_ "GenSigStartValue" SG_ 271 MinPrdtdEngRunTorqCap 938;
BA_ "GenSigTimeoutTime_AGSM" SG_ 271 MinPrdtdEngRunTorqCap 0;
BA_ "GenSigTimeoutTime_ASBS" SG_ 271 MinPrdtdEngRunTorqCap 0;
BA_ "GenSigTimeoutTime_BCM" SG_ 271 MinPrdtdEngRunTorqCap 0;
BA_ "GenSigTimeoutTime_BSM" SG_ 271 MinPrdtdEngRunTorqCap 0;
BA_ "GenSigTimeoutTime_CADM" SG_ 271 MinPrdtdEngRunTorqCap 0;
BA_ "GenSigTimeoutTime_DMSM" SG_ 271 MinPrdtdEngRunTorqCap 0;
BA_ "GenSigTimeoutTime_DTCM" SG_ 271 MinPrdtdEngRunTorqCap 0;
BA_ "GenSigTimeoutTime_ECM" SG_ 271 MinPrdtdEngRunTorqCap 0;
BA_ "GenSigTimeoutTime_ELSDM" SG_ 271 MinPrdtdEngRunTorqCap 0;
BA_ "GenSigTimeoutTime_ESL" SG_ 271 MinPrdtdEngRunTorqCap 0;
BA_ "GenSigTimeoutTime_GNMM" SG_ 271 MinPrdtdEngRunTorqCap 0;
BA_ "GenSigTimeoutTime_IPC" SG_ 271 MinPrdtdEngRunTorqCap 0;
BA_ "GenSigTimeoutTime_RFHM" SG_ 271 MinPrdtdEngRunTorqCap 0;
BA_ "GenSigTimeoutTime_SGW" SG_ 271 MinPrdtdEngRunTorqCap 0;
BA_ "GenSigTimeoutTime_TCM" SG_ 271 MinPrdtdEngRunTorqCap 0;
BA_ "GenSigTimeoutTime_AGSM" SG_ 271 HybActEngTorqRespTyp 0;
BA_ "GenSigTimeoutTime_ASBS" SG_ 271 HybActEngTorqRespTyp 0;
BA_ "GenSigTimeoutTime_BCM" SG_ 271 HybActEngTorqRespTyp 0;
BA_ "GenSigTimeoutTime_BSM" SG_ 271 HybActEngTorqRespTyp 0;
BA_ "GenSigTimeoutTime_CADM" SG_ 271 HybActEngTorqRespTyp 0;
BA_ "GenSigTimeoutTime_DMSM" SG_ 271 HybActEngTorqRespTyp 0;
BA_ "GenSigTimeoutTime_DTCM" SG_ 271 HybActEngTorqRespTyp 0;
BA_ "GenSigTimeoutTime_ECM" SG_ 271 HybActEngTorqRespTyp 0;
BA_ "GenSigTimeoutTime_ELSDM" SG_ 271 HybActEngTorqRespTyp 0;
BA_ "GenSigTimeoutTime_ESL" SG_ 271 HybActEngTorqRespTyp 0;
BA_ "GenSigTimeoutTime_GNMM" SG_ 271 HybActEngTorqRespTyp 0;
BA_ "GenSigTimeoutTime_IPC" SG_ 271 HybActEngTorqRespTyp 0;
BA_ "GenSigTimeoutTime_RFHM" SG_ 271 HybActEngTorqRespTyp 0;
BA_ "GenSigTimeoutTime_SGW" SG_ 271 HybActEngTorqRespTyp 0;
BA_ "GenSigTimeoutTime_TCM" SG_ 271 HybActEngTorqRespTyp 0;
BA_ "GenSigStartValue" SG_ 271 MaxOffEngTorqCap 938;
BA_ "GenSigTimeoutTime_AGSM" SG_ 271 MaxOffEngTorqCap 0;
BA_ "GenSigTimeoutTime_ASBS" SG_ 271 MaxOffEngTorqCap 0;
BA_ "GenSigTimeoutTime_BCM" SG_ 271 MaxOffEngTorqCap 0;
BA_ "GenSigTimeoutTime_BSM" SG_ 271 MaxOffEngTorqCap 0;
BA_ "GenSigTimeoutTime_CADM" SG_ 271 MaxOffEngTorqCap 0;
BA_ "GenSigTimeoutTime_DMSM" SG_ 271 MaxOffEngTorqCap 0;
BA_ "GenSigTimeoutTime_DTCM" SG_ 271 MaxOffEngTorqCap 0;
BA_ "GenSigTimeoutTime_ECM" SG_ 271 MaxOffEngTorqCap 0;
BA_ "GenSigTimeoutTime_ELSDM" SG_ 271 MaxOffEngTorqCap 0;
BA_ "GenSigTimeoutTime_ESL" SG_ 271 MaxOffEngTorqCap 0;
BA_ "GenSigTimeoutTime_GNMM" SG_ 271 MaxOffEngTorqCap 0;
BA_ "GenSigTimeoutTime_IPC" SG_ 271 MaxOffEngTorqCap 0;
BA_ "GenSigTimeoutTime_RFHM" SG_ 271 MaxOffEngTorqCap 0;
BA_ "GenSigTimeoutTime_SGW" SG_ 271 MaxOffEngTorqCap 0;
BA_ "GenSigTimeoutTime_TCM" SG_ 271 MaxOffEngTorqCap 0;
BA_ "GenSigStartValue" SG_ 271 MaxPrdtdEngTorqCap 938;
BA_ "GenSigTimeoutTime_AGSM" SG_ 271 MaxPrdtdEngTorqCap 0;
BA_ "GenSigTimeoutTime_ASBS" SG_ 271 MaxPrdtdEngTorqCap 0;
BA_ "GenSigTimeoutTime_BCM" SG_ 271 MaxPrdtdEngTorqCap 0;
BA_ "GenSigTimeoutTime_BSM" SG_ 271 MaxPrdtdEngTorqCap 0;
BA_ "GenSigTimeoutTime_CADM" SG_ 271 MaxPrdtdEngTorqCap 0;
BA_ "GenSigTimeoutTime_DMSM" SG_ 271 MaxPrdtdEngTorqCap 0;
BA_ "GenSigTimeoutTime_DTCM" SG_ 271 MaxPrdtdEngTorqCap 0;
BA_ "GenSigTimeoutTime_ECM" SG_ 271 MaxPrdtdEngTorqCap 0;
BA_ "GenSigTimeoutTime_ELSDM" SG_ 271 MaxPrdtdEngTorqCap 0;
BA_ "GenSigTimeoutTime_ESL" SG_ 271 MaxPrdtdEngTorqCap 0;
BA_ "GenSigTimeoutTime_GNMM" SG_ 271 MaxPrdtdEngTorqCap 0;
BA_ "GenSigTimeoutTime_IPC" SG_ 271 MaxPrdtdEngTorqCap 0;
BA_ "GenSigTimeoutTime_RFHM" SG_ 271 MaxPrdtdEngTorqCap 0;
BA_ "GenSigTimeoutTime_SGW" SG_ 271 MaxPrdtdEngTorqCap 0;
BA_ "GenSigTimeoutTime_TCM" SG_ 271 MaxPrdtdEngTorqCap 0;
BA_ "GenSigTimeoutTime_AGSM" SG_ 271 MaxPrdtdEngTorqCapV 0;
BA_ "GenSigTimeoutTime_ASBS" SG_ 271 MaxPrdtdEngTorqCapV 0;
BA_ "GenSigTimeoutTime_BCM" SG_ 271 MaxPrdtdEngTorqCapV 0;
BA_ "GenSigTimeoutTime_BSM" SG_ 271 MaxPrdtdEngTorqCapV 0;
BA_ "GenSigTimeoutTime_CADM" SG_ 271 MaxPrdtdEngTorqCapV 0;
BA_ "GenSigTimeoutTime_DMSM" SG_ 271 MaxPrdtdEngTorqCapV 0;
BA_ "GenSigTimeoutTime_DTCM" SG_ 271 MaxPrdtdEngTorqCapV 0;
BA_ "GenSigTimeoutTime_ECM" SG_ 271 MaxPrdtdEngTorqCapV 0;
BA_ "GenSigTimeoutTime_ELSDM" SG_ 271 MaxPrdtdEngTorqCapV 0;
BA_ "GenSigTimeoutTime_ESL" SG_ 271 MaxPrdtdEngTorqCapV 0;
BA_ "GenSigTimeoutTime_GNMM" SG_ 271 MaxPrdtdEngTorqCapV 0;
BA_ "GenSigTimeoutTime_IPC" SG_ 271 MaxPrdtdEngTorqCapV 0;
BA_ "GenSigTimeoutTime_RFHM" SG_ 271 MaxPrdtdEngTorqCapV 0;
BA_ "GenSigTimeoutTime_SGW" SG_ 271 MaxPrdtdEngTorqCapV 0;
BA_ "GenSigTimeoutTime_TCM" SG_ 271 MaxPrdtdEngTorqCapV 0;
BA_ "GenSigTimeoutTime_AGSM" SG_ 271 MessageCounter_ENGINE_HYBD_FD_1 0;
BA_ "GenSigTimeoutTime_ASBS" SG_ 271 MessageCounter_ENGINE_HYBD_FD_1 0;
BA_ "GenSigTimeoutTime_BCM" SG_ 271 MessageCounter_ENGINE_HYBD_FD_1 0;
BA_ "GenSigTimeoutTime_BSM" SG_ 271 MessageCounter_ENGINE_HYBD_FD_1 0;
BA_ "GenSigTimeoutTime_CADM" SG_ 271 MessageCounter_ENGINE_HYBD_FD_1 0;
BA_ "GenSigTimeoutTime_DMSM" SG_ 271 MessageCounter_ENGINE_HYBD_FD_1 0;
BA_ "GenSigTimeoutTime_DTCM" SG_ 271 MessageCounter_ENGINE_HYBD_FD_1 0;
BA_ "GenSigTimeoutTime_ECM" SG_ 271 MessageCounter_ENGINE_HYBD_FD_1 0;
BA_ "GenSigTimeoutTime_ELSDM" SG_ 271 MessageCounter_ENGINE_HYBD_FD_1 0;
BA_ "GenSigTimeoutTime_ESL" SG_ 271 MessageCounter_ENGINE_HYBD_FD_1 0;
BA_ "GenSigTimeoutTime_GNMM" SG_ 271 MessageCounter_ENGINE_HYBD_FD_1 0;
BA_ "GenSigTimeoutTime_IPC" SG_ 271 MessageCounter_ENGINE_HYBD_FD_1 0;
BA_ "GenSigTimeoutTime_RFHM" SG_ 271 MessageCounter_ENGINE_HYBD_FD_1 0;
BA_ "GenSigTimeoutTime_SGW" SG_ 271 MessageCounter_ENGINE_HYBD_FD_1 0;
BA_ "GenSigStartValue" SG_ 271 MinAirFlowMinSparkTorqCap 938;
BA_ "GenSigTimeoutTime_AGSM" SG_ 271 MinAirFlowMinSparkTorqCap 0;
BA_ "GenSigTimeoutTime_ASBS" SG_ 271 MinAirFlowMinSparkTorqCap 0;
BA_ "GenSigTimeoutTime_BCM" SG_ 271 MinAirFlowMinSparkTorqCap 0;
BA_ "GenSigTimeoutTime_BSM" SG_ 271 MinAirFlowMinSparkTorqCap 0;
BA_ "GenSigTimeoutTime_CADM" SG_ 271 MinAirFlowMinSparkTorqCap 0;
BA_ "GenSigTimeoutTime_DMSM" SG_ 271 MinAirFlowMinSparkTorqCap 0;
BA_ "GenSigTimeoutTime_DTCM" SG_ 271 MinAirFlowMinSparkTorqCap 0;
BA_ "GenSigTimeoutTime_ECM" SG_ 271 MinAirFlowMinSparkTorqCap 0;
BA_ "GenSigTimeoutTime_ELSDM" SG_ 271 MinAirFlowMinSparkTorqCap 0;
BA_ "GenSigTimeoutTime_ESL" SG_ 271 MinAirFlowMinSparkTorqCap 0;
BA_ "GenSigTimeoutTime_GNMM" SG_ 271 MinAirFlowMinSparkTorqCap 0;
BA_ "GenSigTimeoutTime_IPC" SG_ 271 MinAirFlowMinSparkTorqCap 0;
BA_ "GenSigTimeoutTime_RFHM" SG_ 271 MinAirFlowMinSparkTorqCap 0;
BA_ "GenSigTimeoutTime_SGW" SG_ 271 MinAirFlowMinSparkTorqCap 0;
BA_ "GenSigTimeoutTime_TCM" SG_ 271 MinAirFlowMinSparkTorqCap 0;
BA_ "GenSigTimeoutTime_AGSM" SG_ 271 EngRunCrnkAct 0;
BA_ "GenSigTimeoutTime_ASBS" SG_ 271 EngRunCrnkAct 0;
BA_ "GenSigTimeoutTime_BCM" SG_ 271 EngRunCrnkAct 0;
BA_ "GenSigTimeoutTime_BSM" SG_ 271 EngRunCrnkAct 0;
BA_ "GenSigTimeoutTime_CADM" SG_ 271 EngRunCrnkAct 0;
BA_ "GenSigTimeoutTime_DMSM" SG_ 271 EngRunCrnkAct 0;
BA_ "GenSigTimeoutTime_DTCM" SG_ 271 EngRunCrnkAct 0;
BA_ "GenSigTimeoutTime_ECM" SG_ 271 EngRunCrnkAct 0;
BA_ "GenSigTimeoutTime_ELSDM" SG_ 271 EngRunCrnkAct 0;
BA_ "GenSigTimeoutTime_ESL" SG_ 271 EngRunCrnkAct 0;
BA_ "GenSigTimeoutTime_GNMM" SG_ 271 EngRunCrnkAct 0;
BA_ "GenSigTimeoutTime_IPC" SG_ 271 EngRunCrnkAct 0;
BA_ "GenSigTimeoutTime_RFHM" SG_ 271 EngRunCrnkAct 0;
BA_ "GenSigTimeoutTime_SGW" SG_ 271 EngRunCrnkAct 0;
BA_ "GenSigTimeoutTime_TCM" SG_ 271 EngRunCrnkAct 0;
BA_ "GenSigTimeoutTime_AGSM" SG_ 271 EngSysFld 0;
BA_ "GenSigTimeoutTime_ASBS" SG_ 271 EngSysFld 0;
BA_ "GenSigTimeoutTime_BCM" SG_ 271 EngSysFld 0;
BA_ "GenSigTimeoutTime_BSM" SG_ 271 EngSysFld 0;
BA_ "GenSigTimeoutTime_CADM" SG_ 271 EngSysFld 0;
BA_ "GenSigTimeoutTime_DMSM" SG_ 271 EngSysFld 0;
BA_ "GenSigTimeoutTime_DTCM" SG_ 271 EngSysFld 0;
BA_ "GenSigTimeoutTime_ECM" SG_ 271 EngSysFld 0;
BA_ "GenSigTimeoutTime_ELSDM" SG_ 271 EngSysFld 0;
BA_ "GenSigTimeoutTime_ESL" SG_ 271 EngSysFld 0;
BA_ "GenSigTimeoutTime_GNMM" SG_ 271 EngSysFld 0;
BA_ "GenSigTimeoutTime_IPC" SG_ 271 EngSysFld 0;
BA_ "GenSigTimeoutTime_RFHM" SG_ 271 EngSysFld 0;
BA_ "GenSigTimeoutTime_SGW" SG_ 271 EngSysFld 0;
BA_ "GenSigTimeoutTime_TCM" SG_ 271 EngSysFld 0;
BA_ "GenSigTimeoutTime_AGSM" SG_ 271 EngTrqReserveReq 0;
BA_ "GenSigTimeoutTime_ASBS" SG_ 271 EngTrqReserveReq 0;
BA_ "GenSigTimeoutTime_BCM" SG_ 271 EngTrqReserveReq 0;
BA_ "GenSigTimeoutTime_BSM" SG_ 271 EngTrqReserveReq 0;
BA_ "GenSigTimeoutTime_CADM" SG_ 271 EngTrqReserveReq 0;
BA_ "GenSigTimeoutTime_DMSM" SG_ 271 EngTrqReserveReq 0;
BA_ "GenSigTimeoutTime_DTCM" SG_ 271 EngTrqReserveReq 0;
BA_ "GenSigTimeoutTime_ECM" SG_ 271 EngTrqReserveReq 0;
BA_ "GenSigTimeoutTime_ELSDM" SG_ 271 EngTrqReserveReq 0;
BA_ "GenSigTimeoutTime_ESL" SG_ 271 EngTrqReserveReq 0;
BA_ "GenSigTimeoutTime_GNMM" SG_ 271 EngTrqReserveReq 0;
BA_ "GenSigTimeoutTime_IPC" SG_ 271 EngTrqReserveReq 0;
BA_ "GenSigTimeoutTime_RFHM" SG_ 271 EngTrqReserveReq 0;
BA_ "GenSigTimeoutTime_SGW" SG_ 271 EngTrqReserveReq 0;
BA_ "GenSigTimeoutTime_TCM" SG_ 271 EngTrqReserveReq 0;
BA_ "GenSigStartValue" SG_ 271 ESS_Engine_State_EE 15;
BA_ "GenSigTimeoutTime_AGSM" SG_ 271 ESS_Engine_State_EE 0;
BA_ "GenSigTimeoutTime_ASBS" SG_ 271 ESS_Engine_State_EE 0;
BA_ "GenSigTimeoutTime_BCM" SG_ 271 ESS_Engine_State_EE 0;
BA_ "GenSigTimeoutTime_BSM" SG_ 271 ESS_Engine_State_EE 0;
BA_ "GenSigTimeoutTime_CADM" SG_ 271 ESS_Engine_State_EE 0;
BA_ "GenSigTimeoutTime_DMSM" SG_ 271 ESS_Engine_State_EE 0;
BA_ "GenSigTimeoutTime_DTCM" SG_ 271 ESS_Engine_State_EE 0;
BA_ "GenSigTimeoutTime_ECM" SG_ 271 ESS_Engine_State_EE 0;
BA_ "GenSigTimeoutTime_ELSDM" SG_ 271 ESS_Engine_State_EE 0;
BA_ "GenSigTimeoutTime_ESL" SG_ 271 ESS_Engine_State_EE 0;
BA_ "GenSigTimeoutTime_GNMM" SG_ 271 ESS_Engine_State_EE 0;
BA_ "GenSigTimeoutTime_IPC" SG_ 271 ESS_Engine_State_EE 0;
BA_ "GenSigTimeoutTime_RFHM" SG_ 271 ESS_Engine_State_EE 0;
BA_ "GenSigTimeoutTime_SGW" SG_ 271 ESS_Engine_State_EE 0;
BA_ "GenSigTimeoutTime_TCM" SG_ 271 ESS_Engine_State_EE 0;
BA_ "GenSigTimeoutTime_AGSM" SG_ 271 ETRQ_Mode 0;
BA_ "GenSigTimeoutTime_ASBS" SG_ 271 ETRQ_Mode 0;
BA_ "GenSigTimeoutTime_BCM" SG_ 271 ETRQ_Mode 0;
BA_ "GenSigTimeoutTime_BSM" SG_ 271 ETRQ_Mode 0;
BA_ "GenSigTimeoutTime_CADM" SG_ 271 ETRQ_Mode 0;
BA_ "GenSigTimeoutTime_DMSM" SG_ 271 ETRQ_Mode 0;
BA_ "GenSigTimeoutTime_DTCM" SG_ 271 ETRQ_Mode 0;
BA_ "GenSigTimeoutTime_ECM" SG_ 271 ETRQ_Mode 0;
BA_ "GenSigTimeoutTime_ELSDM" SG_ 271 ETRQ_Mode 0;
BA_ "GenSigTimeoutTime_ESL" SG_ 271 ETRQ_Mode 0;
BA_ "GenSigTimeoutTime_GNMM" SG_ 271 ETRQ_Mode 0;
BA_ "GenSigTimeoutTime_IPC" SG_ 271 ETRQ_Mode 0;
BA_ "GenSigTimeoutTime_RFHM" SG_ 271 ETRQ_Mode 0;
BA_ "GenSigTimeoutTime_SGW" SG_ 271 ETRQ_Mode 0;
BA_ "GenSigTimeoutTime_TCM" SG_ 271 ETRQ_Mode 0;
BA_ "GenSigTimeoutTime_AGSM" SG_ 271 Feedback_HCP 0;
BA_ "GenSigTimeoutTime_ASBS" SG_ 271 Feedback_HCP 0;
BA_ "GenSigTimeoutTime_BCM" SG_ 271 Feedback_HCP 0;
BA_ "GenSigTimeoutTime_BSM" SG_ 271 Feedback_HCP 0;
BA_ "GenSigTimeoutTime_CADM" SG_ 271 Feedback_HCP 0;
BA_ "GenSigTimeoutTime_DMSM" SG_ 271 Feedback_HCP 0;
BA_ "GenSigTimeoutTime_DTCM" SG_ 271 Feedback_HCP 0;
BA_ "GenSigTimeoutTime_ECM" SG_ 271 Feedback_HCP 0;
BA_ "GenSigTimeoutTime_ELSDM" SG_ 271 Feedback_HCP 0;
BA_ "GenSigTimeoutTime_ESL" SG_ 271 Feedback_HCP 0;
BA_ "GenSigTimeoutTime_GNMM" SG_ 271 Feedback_HCP 0;
BA_ "GenSigTimeoutTime_IPC" SG_ 271 Feedback_HCP 0;
BA_ "GenSigTimeoutTime_RFHM" SG_ 271 Feedback_HCP 0;
BA_ "GenSigTimeoutTime_SGW" SG_ 271 Feedback_HCP 0;
BA_ "GenSigTimeoutTime_TCM" SG_ 271 Feedback_HCP 0;
BA_ "GenSigTimeoutTime_AGSM" SG_ 271 EngDFCO_Allw 0;
BA_ "GenSigTimeoutTime_ASBS" SG_ 271 EngDFCO_Allw 0;
BA_ "GenSigTimeoutTime_BCM" SG_ 271 EngDFCO_Allw 0;
BA_ "GenSigTimeoutTime_BSM" SG_ 271 EngDFCO_Allw 0;
BA_ "GenSigTimeoutTime_CADM" SG_ 271 EngDFCO_Allw 0;
BA_ "GenSigTimeoutTime_DMSM" SG_ 271 EngDFCO_Allw 0;
BA_ "GenSigTimeoutTime_DTCM" SG_ 271 EngDFCO_Allw 0;
BA_ "GenSigTimeoutTime_ECM" SG_ 271 EngDFCO_Allw 0;
BA_ "GenSigTimeoutTime_ELSDM" SG_ 271 EngDFCO_Allw 0;
BA_ "GenSigTimeoutTime_ESL" SG_ 271 EngDFCO_Allw 0;
BA_ "GenSigTimeoutTime_GNMM" SG_ 271 EngDFCO_Allw 0;
BA_ "GenSigTimeoutTime_IPC" SG_ 271 EngDFCO_Allw 0;
BA_ "GenSigTimeoutTime_RFHM" SG_ 271 EngDFCO_Allw 0;
BA_ "GenSigTimeoutTime_SGW" SG_ 271 EngDFCO_Allw 0;
BA_ "GenSigTimeoutTime_TCM" SG_ 271 EngDFCO_Allw 0;
BA_ "GenSigTimeoutTime_AGSM" SG_ 271 EngDFCO_Req 0;
BA_ "GenSigTimeoutTime_ASBS" SG_ 271 EngDFCO_Req 0;
BA_ "GenSigTimeoutTime_BCM" SG_ 271 EngDFCO_Req 0;
BA_ "GenSigTimeoutTime_BSM" SG_ 271 EngDFCO_Req 0;
BA_ "GenSigTimeoutTime_CADM" SG_ 271 EngDFCO_Req 0;
BA_ "GenSigTimeoutTime_DMSM" SG_ 271 EngDFCO_Req 0;
BA_ "GenSigTimeoutTime_DTCM" SG_ 271 EngDFCO_Req 0;
BA_ "GenSigTimeoutTime_ECM" SG_ 271 EngDFCO_Req 0;
BA_ "GenSigTimeoutTime_ELSDM" SG_ 271 EngDFCO_Req 0;
BA_ "GenSigTimeoutTime_ESL" SG_ 271 EngDFCO_Req 0;
BA_ "GenSigTimeoutTime_GNMM" SG_ 271 EngDFCO_Req 0;
BA_ "GenSigTimeoutTime_IPC" SG_ 271 EngDFCO_Req 0;
BA_ "GenSigTimeoutTime_RFHM" SG_ 271 EngDFCO_Req 0;
BA_ "GenSigTimeoutTime_SGW" SG_ 271 EngDFCO_Req 0;
BA_ "GenSigTimeoutTime_TCM" SG_ 271 EngDFCO_Req 0;
BA_ "GenSigTimeoutTime_AGSM" SG_ 271 EngDFCO_St 0;
BA_ "GenSigTimeoutTime_ASBS" SG_ 271 EngDFCO_St 0;
BA_ "GenSigTimeoutTime_BCM" SG_ 271 EngDFCO_St 0;
BA_ "GenSigTimeoutTime_BSM" SG_ 271 EngDFCO_St 0;
BA_ "GenSigTimeoutTime_CADM" SG_ 271 EngDFCO_St 0;
BA_ "GenSigTimeoutTime_DMSM" SG_ 271 EngDFCO_St 0;
BA_ "GenSigTimeoutTime_DTCM" SG_ 271 EngDFCO_St 0;
BA_ "GenSigTimeoutTime_ECM" SG_ 271 EngDFCO_St 0;
BA_ "GenSigTimeoutTime_ELSDM" SG_ 271 EngDFCO_St 0;
BA_ "GenSigTimeoutTime_ESL" SG_ 271 EngDFCO_St 0;
BA_ "GenSigTimeoutTime_GNMM" SG_ 271 EngDFCO_St 0;
BA_ "GenSigTimeoutTime_IPC" SG_ 271 EngDFCO_St 0;
BA_ "GenSigTimeoutTime_RFHM" SG_ 271 EngDFCO_St 0;
BA_ "GenSigTimeoutTime_SGW" SG_ 271 EngDFCO_St 0;
BA_ "GenSigTimeoutTime_TCM" SG_ 271 EngDFCO_St 0;
BA_ "GenSigTimeoutTime_AGSM" SG_ 271 Engine_Sync_720 0;
BA_ "GenSigTimeoutTime_ASBS" SG_ 271 Engine_Sync_720 0;
BA_ "GenSigTimeoutTime_BCM" SG_ 271 Engine_Sync_720 0;
BA_ "GenSigTimeoutTime_BSM" SG_ 271 Engine_Sync_720 0;
BA_ "GenSigTimeoutTime_CADM" SG_ 271 Engine_Sync_720 0;
BA_ "GenSigTimeoutTime_DMSM" SG_ 271 Engine_Sync_720 0;
BA_ "GenSigTimeoutTime_DTCM" SG_ 271 Engine_Sync_720 0;
BA_ "GenSigTimeoutTime_ECM" SG_ 271 Engine_Sync_720 0;
BA_ "GenSigTimeoutTime_ELSDM" SG_ 271 Engine_Sync_720 0;
BA_ "GenSigTimeoutTime_ESL" SG_ 271 Engine_Sync_720 0;
BA_ "GenSigTimeoutTime_GNMM" SG_ 271 Engine_Sync_720 0;
BA_ "GenSigTimeoutTime_HCP" SG_ 271 Engine_Sync_720 0;
BA_ "GenSigTimeoutTime_IPC" SG_ 271 Engine_Sync_720 0;
BA_ "GenSigTimeoutTime_RFHM" SG_ 271 Engine_Sync_720 0;
BA_ "GenSigTimeoutTime_SGW" SG_ 271 Engine_Sync_720 0;
BA_ "GenSigTimeoutTime_TCM" SG_ 271 Engine_Sync_720 0;
BA_ "GenSigTimeoutTime_AGSM" SG_ 271 EngOffRecom 0;
BA_ "GenSigTimeoutTime_ASBS" SG_ 271 EngOffRecom 0;
BA_ "GenSigTimeoutTime_BCM" SG_ 271 EngOffRecom 0;
BA_ "GenSigTimeoutTime_BSM" SG_ 271 EngOffRecom 0;
BA_ "GenSigTimeoutTime_CADM" SG_ 271 EngOffRecom 0;
BA_ "GenSigTimeoutTime_DMSM" SG_ 271 EngOffRecom 0;
BA_ "GenSigTimeoutTime_DTCM" SG_ 271 EngOffRecom 0;
BA_ "GenSigTimeoutTime_ECM" SG_ 271 EngOffRecom 0;
BA_ "GenSigTimeoutTime_ELSDM" SG_ 271 EngOffRecom 0;
BA_ "GenSigTimeoutTime_ESL" SG_ 271 EngOffRecom 0;
BA_ "GenSigTimeoutTime_GNMM" SG_ 271 EngOffRecom 0;
BA_ "GenSigTimeoutTime_IPC" SG_ 271 EngOffRecom 0;
BA_ "GenSigTimeoutTime_RFHM" SG_ 271 EngOffRecom 0;
BA_ "GenSigTimeoutTime_SGW" SG_ 271 EngOffRecom 0;
BA_ "GenSigTimeoutTime_TCM" SG_ 271 EngOffRecom 0;
BA_ "GenSigTimeoutTime_AGSM" SG_ 271 EngRqStTyp 0;
BA_ "GenSigTimeoutTime_ASBS" SG_ 271 EngRqStTyp 0;
BA_ "GenSigTimeoutTime_BCM" SG_ 271 EngRqStTyp 0;
BA_ "GenSigTimeoutTime_BSM" SG_ 271 EngRqStTyp 0;
BA_ "GenSigTimeoutTime_CADM" SG_ 271 EngRqStTyp 0;
BA_ "GenSigTimeoutTime_DMSM" SG_ 271 EngRqStTyp 0;
BA_ "GenSigTimeoutTime_DTCM" SG_ 271 EngRqStTyp 0;
BA_ "GenSigTimeoutTime_ECM" SG_ 271 EngRqStTyp 0;
BA_ "GenSigTimeoutTime_ELSDM" SG_ 271 EngRqStTyp 0;
BA_ "GenSigTimeoutTime_ESL" SG_ 271 EngRqStTyp 0;
BA_ "GenSigTimeoutTime_GNMM" SG_ 271 EngRqStTyp 0;
BA_ "GenSigTimeoutTime_IPC" SG_ 271 EngRqStTyp 0;
BA_ "GenSigTimeoutTime_RFHM" SG_ 271 EngRqStTyp 0;
BA_ "GenSigTimeoutTime_SGW" SG_ 271 EngRqStTyp 0;
BA_ "GenSigTimeoutTime_TCM" SG_ 271 EngRqStTyp 0;
BA_ "GenSigStartValue" SG_ 271 EngActStdyStTorq 938;
BA_ "GenSigTimeoutTime_AGSM" SG_ 271 EngActStdyStTorq 0;
BA_ "GenSigTimeoutTime_ASBS" SG_ 271 EngActStdyStTorq 0;
BA_ "GenSigTimeoutTime_BCM" SG_ 271 EngActStdyStTorq 0;
BA_ "GenSigTimeoutTime_BSM" SG_ 271 EngActStdyStTorq 0;
BA_ "GenSigTimeoutTime_CADM" SG_ 271 EngActStdyStTorq 0;
BA_ "GenSigTimeoutTime_DMSM" SG_ 271 EngActStdyStTorq 0;
BA_ "GenSigTimeoutTime_DTCM" SG_ 271 EngActStdyStTorq 0;
BA_ "GenSigTimeoutTime_ECM" SG_ 271 EngActStdyStTorq 0;
BA_ "GenSigTimeoutTime_ELSDM" SG_ 271 EngActStdyStTorq 0;
BA_ "GenSigTimeoutTime_ESL" SG_ 271 EngActStdyStTorq 0;
BA_ "GenSigTimeoutTime_GNMM" SG_ 271 EngActStdyStTorq 0;
BA_ "GenSigTimeoutTime_IPC" SG_ 271 EngActStdyStTorq 0;
BA_ "GenSigTimeoutTime_RFHM" SG_ 271 EngActStdyStTorq 0;
BA_ "GenSigTimeoutTime_SGW" SG_ 271 EngActStdyStTorq 0;
BA_ "GenSigTimeoutTime_AGSM" SG_ 271 EngActStdyStTorqV 0;
BA_ "GenSigTimeoutTime_ASBS" SG_ 271 EngActStdyStTorqV 0;
BA_ "GenSigTimeoutTime_BCM" SG_ 271 EngActStdyStTorqV 0;
BA_ "GenSigTimeoutTime_BSM" SG_ 271 EngActStdyStTorqV 0;
BA_ "GenSigTimeoutTime_CADM" SG_ 271 EngActStdyStTorqV 0;
BA_ "GenSigTimeoutTime_DMSM" SG_ 271 EngActStdyStTorqV 0;
BA_ "GenSigTimeoutTime_DTCM" SG_ 271 EngActStdyStTorqV 0;
BA_ "GenSigTimeoutTime_ECM" SG_ 271 EngActStdyStTorqV 0;
BA_ "GenSigTimeoutTime_ELSDM" SG_ 271 EngActStdyStTorqV 0;
BA_ "GenSigTimeoutTime_ESL" SG_ 271 EngActStdyStTorqV 0;
BA_ "GenSigTimeoutTime_GNMM" SG_ 271 EngActStdyStTorqV 0;
BA_ "GenSigTimeoutTime_IPC" SG_ 271 EngActStdyStTorqV 0;
BA_ "GenSigTimeoutTime_RFHM" SG_ 271 EngActStdyStTorqV 0;
BA_ "GenSigTimeoutTime_SGW" SG_ 271 EngActStdyStTorqV 0;
BA_ "GenSigTimeoutTime_AGSM" SG_ 271 EngActuatorsStat 0;
BA_ "GenSigTimeoutTime_ASBS" SG_ 271 EngActuatorsStat 0;
BA_ "GenSigTimeoutTime_BCM" SG_ 271 EngActuatorsStat 0;
BA_ "GenSigTimeoutTime_BSM" SG_ 271 EngActuatorsStat 0;
BA_ "GenSigTimeoutTime_CADM" SG_ 271 EngActuatorsStat 0;
BA_ "GenSigTimeoutTime_DMSM" SG_ 271 EngActuatorsStat 0;
BA_ "GenSigTimeoutTime_DTCM" SG_ 271 EngActuatorsStat 0;
BA_ "GenSigTimeoutTime_ECM" SG_ 271 EngActuatorsStat 0;
BA_ "GenSigTimeoutTime_ELSDM" SG_ 271 EngActuatorsStat 0;
BA_ "GenSigTimeoutTime_ESL" SG_ 271 EngActuatorsStat 0;
BA_ "GenSigTimeoutTime_GNMM" SG_ 271 EngActuatorsStat 0;
BA_ "GenSigTimeoutTime_IPC" SG_ 271 EngActuatorsStat 0;
BA_ "GenSigTimeoutTime_RFHM" SG_ 271 EngActuatorsStat 0;
BA_ "GenSigTimeoutTime_SGW" SG_ 271 EngActuatorsStat 0;
BA_ "GenSigTimeoutTime_TCM" SG_ 271 EngActuatorsStat 0;
BA_ "GenSigStartValue" SG_ 271 EngAirFlwStdyStTorq 938;
BA_ "GenSigTimeoutTime_AGSM" SG_ 271 EngAirFlwStdyStTorq 0;
BA_ "GenSigTimeoutTime_ASBS" SG_ 271 EngAirFlwStdyStTorq 0;
BA_ "GenSigTimeoutTime_BCM" SG_ 271 EngAirFlwStdyStTorq 0;
BA_ "GenSigTimeoutTime_BSM" SG_ 271 EngAirFlwStdyStTorq 0;
BA_ "GenSigTimeoutTime_CADM" SG_ 271 EngAirFlwStdyStTorq 0;
BA_ "GenSigTimeoutTime_DMSM" SG_ 271 EngAirFlwStdyStTorq 0;
BA_ "GenSigTimeoutTime_DTCM" SG_ 271 EngAirFlwStdyStTorq 0;
BA_ "GenSigTimeoutTime_ECM" SG_ 271 EngAirFlwStdyStTorq 0;
BA_ "GenSigTimeoutTime_ELSDM" SG_ 271 EngAirFlwStdyStTorq 0;
BA_ "GenSigTimeoutTime_ESL" SG_ 271 EngAirFlwStdyStTorq 0;
BA_ "GenSigTimeoutTime_GNMM" SG_ 271 EngAirFlwStdyStTorq 0;
BA_ "GenSigTimeoutTime_IPC" SG_ 271 EngAirFlwStdyStTorq 0;
BA_ "GenSigTimeoutTime_RFHM" SG_ 271 EngAirFlwStdyStTorq 0;
BA_ "GenSigTimeoutTime_SGW" SG_ 271 EngAirFlwStdyStTorq 0;
BA_ "GenSigTimeoutTime_TCM" SG_ 271 EngAirFlwStdyStTorq 0;
BA_ "GenSigTimeoutTime_AGSM" SG_ 271 EngAirFlwStdyStTorqV 0;
BA_ "GenSigTimeoutTime_ASBS" SG_ 271 EngAirFlwStdyStTorqV 0;
BA_ "GenSigTimeoutTime_BCM" SG_ 271 EngAirFlwStdyStTorqV 0;
BA_ "GenSigTimeoutTime_BSM" SG_ 271 EngAirFlwStdyStTorqV 0;
BA_ "GenSigTimeoutTime_CADM" SG_ 271 EngAirFlwStdyStTorqV 0;
BA_ "GenSigTimeoutTime_DMSM" SG_ 271 EngAirFlwStdyStTorqV 0;
BA_ "GenSigTimeoutTime_DTCM" SG_ 271 EngAirFlwStdyStTorqV 0;
BA_ "GenSigTimeoutTime_ECM" SG_ 271 EngAirFlwStdyStTorqV 0;
BA_ "GenSigTimeoutTime_ELSDM" SG_ 271 EngAirFlwStdyStTorqV 0;
BA_ "GenSigTimeoutTime_ESL" SG_ 271 EngAirFlwStdyStTorqV 0;
BA_ "GenSigTimeoutTime_GNMM" SG_ 271 EngAirFlwStdyStTorqV 0;
BA_ "GenSigTimeoutTime_IPC" SG_ 271 EngAirFlwStdyStTorqV 0;
BA_ "GenSigTimeoutTime_RFHM" SG_ 271 EngAirFlwStdyStTorqV 0;
BA_ "GenSigTimeoutTime_SGW" SG_ 271 EngAirFlwStdyStTorqV 0;
BA_ "GenSigTimeoutTime_TCM" SG_ 271 EngAirFlwStdyStTorqV 0;
BA_ "GenSigTimeoutTime_AGSM" SG_ 271 EngCmbstnCmnd 0;
BA_ "GenSigTimeoutTime_ASBS" SG_ 271 EngCmbstnCmnd 0;
BA_ "GenSigTimeoutTime_BCM" SG_ 271 EngCmbstnCmnd 0;
BA_ "GenSigTimeoutTime_BSM" SG_ 271 EngCmbstnCmnd 0;
BA_ "GenSigTimeoutTime_CADM" SG_ 271 EngCmbstnCmnd 0;
BA_ "GenSigTimeoutTime_DMSM" SG_ 271 EngCmbstnCmnd 0;
BA_ "GenSigTimeoutTime_DTCM" SG_ 271 EngCmbstnCmnd 0;
BA_ "GenSigTimeoutTime_ECM" SG_ 271 EngCmbstnCmnd 0;
BA_ "GenSigTimeoutTime_ELSDM" SG_ 271 EngCmbstnCmnd 0;
BA_ "GenSigTimeoutTime_ESL" SG_ 271 EngCmbstnCmnd 0;
BA_ "GenSigTimeoutTime_GNMM" SG_ 271 EngCmbstnCmnd 0;
BA_ "GenSigTimeoutTime_IPC" SG_ 271 EngCmbstnCmnd 0;
BA_ "GenSigTimeoutTime_RFHM" SG_ 271 EngCmbstnCmnd 0;
BA_ "GenSigTimeoutTime_SGW" SG_ 271 EngCmbstnCmnd 0;
BA_ "GenSigTimeoutTime_TCM" SG_ 271 EngCmbstnCmnd 0;
BA_ "GenSigTimeoutTime_AGSM" SG_ 271 CRC_ENGINE_HYBD_FD_1 0;
BA_ "GenSigTimeoutTime_ASBS" SG_ 271 CRC_ENGINE_HYBD_FD_1 0;
BA_ "GenSigTimeoutTime_BCM" SG_ 271 CRC_ENGINE_HYBD_FD_1 0;
BA_ "GenSigTimeoutTime_BSM" SG_ 271 CRC_ENGINE_HYBD_FD_1 0;
BA_ "GenSigTimeoutTime_CADM" SG_ 271 CRC_ENGINE_HYBD_FD_1 0;
BA_ "GenSigTimeoutTime_DMSM" SG_ 271 CRC_ENGINE_HYBD_FD_1 0;
BA_ "GenSigTimeoutTime_DTCM" SG_ 271 CRC_ENGINE_HYBD_FD_1 0;
BA_ "GenSigTimeoutTime_ECM" SG_ 271 CRC_ENGINE_HYBD_FD_1 0;
BA_ "GenSigTimeoutTime_ELSDM" SG_ 271 CRC_ENGINE_HYBD_FD_1 0;
BA_ "GenSigTimeoutTime_ESL" SG_ 271 CRC_ENGINE_HYBD_FD_1 0;
BA_ "GenSigTimeoutTime_GNMM" SG_ 271 CRC_ENGINE_HYBD_FD_1 0;
BA_ "GenSigTimeoutTime_IPC" SG_ 271 CRC_ENGINE_HYBD_FD_1 0;
BA_ "GenSigTimeoutTime_RFHM" SG_ 271 CRC_ENGINE_HYBD_FD_1 0;
BA_ "GenSigTimeoutTime_SGW" SG_ 271 CRC_ENGINE_HYBD_FD_1 0;
BA_ "GenSigTimeoutTime_AGSM" SG_ 271 CylOff 0;
BA_ "GenSigTimeoutTime_ASBS" SG_ 271 CylOff 0;
BA_ "GenSigTimeoutTime_BCM" SG_ 271 CylOff 0;
BA_ "GenSigTimeoutTime_BSM" SG_ 271 CylOff 0;
BA_ "GenSigTimeoutTime_CADM" SG_ 271 CylOff 0;
BA_ "GenSigTimeoutTime_DMSM" SG_ 271 CylOff 0;
BA_ "GenSigTimeoutTime_DTCM" SG_ 271 CylOff 0;
BA_ "GenSigTimeoutTime_ECM" SG_ 271 CylOff 0;
BA_ "GenSigTimeoutTime_ELSDM" SG_ 271 CylOff 0;
BA_ "GenSigTimeoutTime_ESL" SG_ 271 CylOff 0;
BA_ "GenSigTimeoutTime_GNMM" SG_ 271 CylOff 0;
BA_ "GenSigTimeoutTime_IPC" SG_ 271 CylOff 0;
BA_ "GenSigTimeoutTime_RFHM" SG_ 271 CylOff 0;
BA_ "GenSigTimeoutTime_SGW" SG_ 271 CylOff 0;
BA_ "GenSigTimeoutTime_TCM" SG_ 271 CylOff 0;
BA_ "GenSigTimeoutTime_AGSM" SG_ 271 DrvrIntndedAxleTorqRaw 0;
BA_ "GenSigTimeoutTime_ASBS" SG_ 271 DrvrIntndedAxleTorqRaw 0;
BA_ "GenSigTimeoutTime_BCM" SG_ 271 DrvrIntndedAxleTorqRaw 0;
BA_ "GenSigTimeoutTime_BSM" SG_ 271 DrvrIntndedAxleTorqRaw 0;
BA_ "GenSigTimeoutTime_CADM" SG_ 271 DrvrIntndedAxleTorqRaw 0;
BA_ "GenSigTimeoutTime_DMSM" SG_ 271 DrvrIntndedAxleTorqRaw 0;
BA_ "GenSigTimeoutTime_DTCM" SG_ 271 DrvrIntndedAxleTorqRaw 0;
BA_ "GenSigTimeoutTime_ECM" SG_ 271 DrvrIntndedAxleTorqRaw 0;
BA_ "GenSigTimeoutTime_ELSDM" SG_ 271 DrvrIntndedAxleTorqRaw 0;
BA_ "GenSigTimeoutTime_ESL" SG_ 271 DrvrIntndedAxleTorqRaw 0;
BA_ "GenSigTimeoutTime_GNMM" SG_ 271 DrvrIntndedAxleTorqRaw 0;
BA_ "GenSigTimeoutTime_IPC" SG_ 271 DrvrIntndedAxleTorqRaw 0;
BA_ "GenSigTimeoutTime_RFHM" SG_ 271 DrvrIntndedAxleTorqRaw 0;
BA_ "GenSigTimeoutTime_SGW" SG_ 271 DrvrIntndedAxleTorqRaw 0;
BA_ "GenSigTimeoutTime_TCM" SG_ 271 DrvrIntndedAxleTorqRaw 0;
BA_ "GenSigTimeoutTime_AGSM" SG_ 271 DrvrIntndedAxleTorqRawV 0;
BA_ "GenSigTimeoutTime_ASBS" SG_ 271 DrvrIntndedAxleTorqRawV 0;
BA_ "GenSigTimeoutTime_BCM" SG_ 271 DrvrIntndedAxleTorqRawV 0;
BA_ "GenSigTimeoutTime_BSM" SG_ 271 DrvrIntndedAxleTorqRawV 0;
BA_ "GenSigTimeoutTime_CADM" SG_ 271 DrvrIntndedAxleTorqRawV 0;
BA_ "GenSigTimeoutTime_DMSM" SG_ 271 DrvrIntndedAxleTorqRawV 0;
BA_ "GenSigTimeoutTime_DTCM" SG_ 271 DrvrIntndedAxleTorqRawV 0;
BA_ "GenSigTimeoutTime_ECM" SG_ 271 DrvrIntndedAxleTorqRawV 0;
BA_ "GenSigTimeoutTime_ELSDM" SG_ 271 DrvrIntndedAxleTorqRawV 0;
BA_ "GenSigTimeoutTime_ESL" SG_ 271 DrvrIntndedAxleTorqRawV 0;
BA_ "GenSigTimeoutTime_GNMM" SG_ 271 DrvrIntndedAxleTorqRawV 0;
BA_ "GenSigTimeoutTime_IPC" SG_ 271 DrvrIntndedAxleTorqRawV 0;
BA_ "GenSigTimeoutTime_RFHM" SG_ 271 DrvrIntndedAxleTorqRawV 0;
BA_ "GenSigTimeoutTime_SGW" SG_ 271 DrvrIntndedAxleTorqRawV 0;
BA_ "GenSigTimeoutTime_TCM" SG_ 271 DrvrIntndedAxleTorqRawV 0;
BA_ "GenSigTimeoutTime_AGSM" SG_ 271 ECM_IMMO_STAT_CANePT 0;
BA_ "GenSigTimeoutTime_ASBS" SG_ 271 ECM_IMMO_STAT_CANePT 0;
BA_ "GenSigTimeoutTime_BCM" SG_ 271 ECM_IMMO_STAT_CANePT 0;
BA_ "GenSigTimeoutTime_BSM" SG_ 271 ECM_IMMO_STAT_CANePT 0;
BA_ "GenSigTimeoutTime_CADM" SG_ 271 ECM_IMMO_STAT_CANePT 0;
BA_ "GenSigTimeoutTime_DMSM" SG_ 271 ECM_IMMO_STAT_CANePT 0;
BA_ "GenSigTimeoutTime_DTCM" SG_ 271 ECM_IMMO_STAT_CANePT 0;
BA_ "GenSigTimeoutTime_ECM" SG_ 271 ECM_IMMO_STAT_CANePT 0;
BA_ "GenSigTimeoutTime_ELSDM" SG_ 271 ECM_IMMO_STAT_CANePT 0;
BA_ "GenSigTimeoutTime_ESL" SG_ 271 ECM_IMMO_STAT_CANePT 0;
BA_ "GenSigTimeoutTime_GNMM" SG_ 271 ECM_IMMO_STAT_CANePT 0;
BA_ "GenSigTimeoutTime_IPC" SG_ 271 ECM_IMMO_STAT_CANePT 0;
BA_ "GenSigTimeoutTime_RFHM" SG_ 271 ECM_IMMO_STAT_CANePT 0;
BA_ "GenSigTimeoutTime_SGW" SG_ 271 ECM_IMMO_STAT_CANePT 0;
BA_ "GenSigTimeoutTime_TCM" SG_ 271 ECM_IMMO_STAT_CANePT 0;
BA_ "GenSigTimeoutTime_AGSM" SG_ 271 ECU_A2D_Failure 0;
BA_ "GenSigTimeoutTime_ASBS" SG_ 271 ECU_A2D_Failure 0;
BA_ "GenSigTimeoutTime_BCM" SG_ 271 ECU_A2D_Failure 0;
BA_ "GenSigTimeoutTime_BSM" SG_ 271 ECU_A2D_Failure 0;
BA_ "GenSigTimeoutTime_CADM" SG_ 271 ECU_A2D_Failure 0;
BA_ "GenSigTimeoutTime_DMSM" SG_ 271 ECU_A2D_Failure 0;
BA_ "GenSigTimeoutTime_DTCM" SG_ 271 ECU_A2D_Failure 0;
BA_ "GenSigTimeoutTime_ECM" SG_ 271 ECU_A2D_Failure 0;
BA_ "GenSigTimeoutTime_ELSDM" SG_ 271 ECU_A2D_Failure 0;
BA_ "GenSigTimeoutTime_ESL" SG_ 271 ECU_A2D_Failure 0;
BA_ "GenSigTimeoutTime_GNMM" SG_ 271 ECU_A2D_Failure 0;
BA_ "GenSigTimeoutTime_IPC" SG_ 271 ECU_A2D_Failure 0;
BA_ "GenSigTimeoutTime_RFHM" SG_ 271 ECU_A2D_Failure 0;
BA_ "GenSigTimeoutTime_SGW" SG_ 271 ECU_A2D_Failure 0;
BA_ "GenSigTimeoutTime_TCM" SG_ 271 ECU_A2D_Failure 0;
BA_ "GenSigTimeoutTime_AGSM" SG_ 271 Cam_Int_2_Locked 0;
BA_ "GenSigTimeoutTime_ASBS" SG_ 271 Cam_Int_2_Locked 0;
BA_ "GenSigTimeoutTime_BCM" SG_ 271 Cam_Int_2_Locked 0;
BA_ "GenSigTimeoutTime_BSM" SG_ 271 Cam_Int_2_Locked 0;
BA_ "GenSigTimeoutTime_CADM" SG_ 271 Cam_Int_2_Locked 0;
BA_ "GenSigTimeoutTime_DMSM" SG_ 271 Cam_Int_2_Locked 0;
BA_ "GenSigTimeoutTime_DTCM" SG_ 271 Cam_Int_2_Locked 0;
BA_ "GenSigTimeoutTime_ECM" SG_ 271 Cam_Int_2_Locked 0;
BA_ "GenSigTimeoutTime_ELSDM" SG_ 271 Cam_Int_2_Locked 0;
BA_ "GenSigTimeoutTime_ESL" SG_ 271 Cam_Int_2_Locked 0;
BA_ "GenSigTimeoutTime_GNMM" SG_ 271 Cam_Int_2_Locked 0;
BA_ "GenSigTimeoutTime_HCP" SG_ 271 Cam_Int_2_Locked 0;
BA_ "GenSigTimeoutTime_IPC" SG_ 271 Cam_Int_2_Locked 0;
BA_ "GenSigTimeoutTime_RFHM" SG_ 271 Cam_Int_2_Locked 0;
BA_ "GenSigTimeoutTime_SGW" SG_ 271 Cam_Int_2_Locked 0;
BA_ "GenSigTimeoutTime_TCM" SG_ 271 Cam_Int_2_Locked 0;
BA_ "GenSigStartValue" SG_ 271 CmndFlyWheelTorqPotential 938;
BA_ "GenSigTimeoutTime_AGSM" SG_ 271 CmndFlyWheelTorqPotential 0;
BA_ "GenSigTimeoutTime_ASBS" SG_ 271 CmndFlyWheelTorqPotential 0;
BA_ "GenSigTimeoutTime_BCM" SG_ 271 CmndFlyWheelTorqPotential 0;
BA_ "GenSigTimeoutTime_BSM" SG_ 271 CmndFlyWheelTorqPotential 0;
BA_ "GenSigTimeoutTime_CADM" SG_ 271 CmndFlyWheelTorqPotential 0;
BA_ "GenSigTimeoutTime_DMSM" SG_ 271 CmndFlyWheelTorqPotential 0;
BA_ "GenSigTimeoutTime_DTCM" SG_ 271 CmndFlyWheelTorqPotential 0;
BA_ "GenSigTimeoutTime_ECM" SG_ 271 CmndFlyWheelTorqPotential 0;
BA_ "GenSigTimeoutTime_ELSDM" SG_ 271 CmndFlyWheelTorqPotential 0;
BA_ "GenSigTimeoutTime_ESL" SG_ 271 CmndFlyWheelTorqPotential 0;
BA_ "GenSigTimeoutTime_GNMM" SG_ 271 CmndFlyWheelTorqPotential 0;
BA_ "GenSigTimeoutTime_IPC" SG_ 271 CmndFlyWheelTorqPotential 0;
BA_ "GenSigTimeoutTime_RFHM" SG_ 271 CmndFlyWheelTorqPotential 0;
BA_ "GenSigTimeoutTime_SGW" SG_ 271 CmndFlyWheelTorqPotential 0;
BA_ "GenSigTimeoutTime_TCM" SG_ 271 CmndFlyWheelTorqPotential 0;
BA_ "GenSigStartValue" SG_ 271 CmndFlyWheelTorqPrdtd 938;
BA_ "GenSigTimeoutTime_AGSM" SG_ 271 CmndFlyWheelTorqPrdtd 0;
BA_ "GenSigTimeoutTime_ASBS" SG_ 271 CmndFlyWheelTorqPrdtd 0;
BA_ "GenSigTimeoutTime_BCM" SG_ 271 CmndFlyWheelTorqPrdtd 0;
BA_ "GenSigTimeoutTime_BSM" SG_ 271 CmndFlyWheelTorqPrdtd 0;
BA_ "GenSigTimeoutTime_CADM" SG_ 271 CmndFlyWheelTorqPrdtd 0;
BA_ "GenSigTimeoutTime_DMSM" SG_ 271 CmndFlyWheelTorqPrdtd 0;
BA_ "GenSigTimeoutTime_DTCM" SG_ 271 CmndFlyWheelTorqPrdtd 0;
BA_ "GenSigTimeoutTime_ECM" SG_ 271 CmndFlyWheelTorqPrdtd 0;
BA_ "GenSigTimeoutTime_ELSDM" SG_ 271 CmndFlyWheelTorqPrdtd 0;
BA_ "GenSigTimeoutTime_ESL" SG_ 271 CmndFlyWheelTorqPrdtd 0;
BA_ "GenSigTimeoutTime_GNMM" SG_ 271 CmndFlyWheelTorqPrdtd 0;
BA_ "GenSigTimeoutTime_IPC" SG_ 271 CmndFlyWheelTorqPrdtd 0;
BA_ "GenSigTimeoutTime_RFHM" SG_ 271 CmndFlyWheelTorqPrdtd 0;
BA_ "GenSigTimeoutTime_SGW" SG_ 271 CmndFlyWheelTorqPrdtd 0;
BA_ "GenSigTimeoutTime_TCM" SG_ 271 CmndFlyWheelTorqPrdtd 0;
BA_ "GenSigTimeoutTime_AGSM" SG_ 271 CmndFlyWheelTorqRespTyp 0;
BA_ "GenSigTimeoutTime_ASBS" SG_ 271 CmndFlyWheelTorqRespTyp 0;
BA_ "GenSigTimeoutTime_BCM" SG_ 271 CmndFlyWheelTorqRespTyp 0;
BA_ "GenSigTimeoutTime_BSM" SG_ 271 CmndFlyWheelTorqRespTyp 0;
BA_ "GenSigTimeoutTime_CADM" SG_ 271 CmndFlyWheelTorqRespTyp 0;
BA_ "GenSigTimeoutTime_DMSM" SG_ 271 CmndFlyWheelTorqRespTyp 0;
BA_ "GenSigTimeoutTime_DTCM" SG_ 271 CmndFlyWheelTorqRespTyp 0;
BA_ "GenSigTimeoutTime_ECM" SG_ 271 CmndFlyWheelTorqRespTyp 0;
BA_ "GenSigTimeoutTime_ELSDM" SG_ 271 CmndFlyWheelTorqRespTyp 0;
BA_ "GenSigTimeoutTime_ESL" SG_ 271 CmndFlyWheelTorqRespTyp 0;
BA_ "GenSigTimeoutTime_GNMM" SG_ 271 CmndFlyWheelTorqRespTyp 0;
BA_ "GenSigTimeoutTime_IPC" SG_ 271 CmndFlyWheelTorqRespTyp 0;
BA_ "GenSigTimeoutTime_RFHM" SG_ 271 CmndFlyWheelTorqRespTyp 0;
BA_ "GenSigTimeoutTime_SGW" SG_ 271 CmndFlyWheelTorqRespTyp 0;
BA_ "GenSigTimeoutTime_TCM" SG_ 271 CmndFlyWheelTorqRespTyp 0;
BA_ "GenSigTimeoutTime_AGSM" SG_ 271 Crank_Locked 0;
BA_ "GenSigTimeoutTime_ASBS" SG_ 271 Crank_Locked 0;
BA_ "GenSigTimeoutTime_BCM" SG_ 271 Crank_Locked 0;
BA_ "GenSigTimeoutTime_BSM" SG_ 271 Crank_Locked 0;
BA_ "GenSigTimeoutTime_CADM" SG_ 271 Crank_Locked 0;
BA_ "GenSigTimeoutTime_DMSM" SG_ 271 Crank_Locked 0;
BA_ "GenSigTimeoutTime_DTCM" SG_ 271 Crank_Locked 0;
BA_ "GenSigTimeoutTime_ECM" SG_ 271 Crank_Locked 0;
BA_ "GenSigTimeoutTime_ELSDM" SG_ 271 Crank_Locked 0;
BA_ "GenSigTimeoutTime_ESL" SG_ 271 Crank_Locked 0;
BA_ "GenSigTimeoutTime_GNMM" SG_ 271 Crank_Locked 0;
BA_ "GenSigTimeoutTime_HCP" SG_ 271 Crank_Locked 0;
BA_ "GenSigTimeoutTime_IPC" SG_ 271 Crank_Locked 0;
BA_ "GenSigTimeoutTime_RFHM" SG_ 271 Crank_Locked 0;
BA_ "GenSigTimeoutTime_SGW" SG_ 271 Crank_Locked 0;
BA_ "GenSigTimeoutTime_TCM" SG_ 271 Crank_Locked 0;
BA_ "GenSigTimeoutTime_AGSM" SG_ 271 Crank_Maturing_Fault 0;
BA_ "GenSigTimeoutTime_ASBS" SG_ 271 Crank_Maturing_Fault 0;
BA_ "GenSigTimeoutTime_BCM" SG_ 271 Crank_Maturing_Fault 0;
BA_ "GenSigTimeoutTime_BSM" SG_ 271 Crank_Maturing_Fault 0;
BA_ "GenSigTimeoutTime_CADM" SG_ 271 Crank_Maturing_Fault 0;
BA_ "GenSigTimeoutTime_DMSM" SG_ 271 Crank_Maturing_Fault 0;
BA_ "GenSigTimeoutTime_DTCM" SG_ 271 Crank_Maturing_Fault 0;
BA_ "GenSigTimeoutTime_ECM" SG_ 271 Crank_Maturing_Fault 0;
BA_ "GenSigTimeoutTime_ELSDM" SG_ 271 Crank_Maturing_Fault 0;
BA_ "GenSigTimeoutTime_ESL" SG_ 271 Crank_Maturing_Fault 0;
BA_ "GenSigTimeoutTime_GNMM" SG_ 271 Crank_Maturing_Fault 0;
BA_ "GenSigTimeoutTime_IPC" SG_ 271 Crank_Maturing_Fault 0;
BA_ "GenSigTimeoutTime_RFHM" SG_ 271 Crank_Maturing_Fault 0;
BA_ "GenSigTimeoutTime_SGW" SG_ 271 Crank_Maturing_Fault 0;
BA_ "GenSigTimeoutTime_TCM" SG_ 271 Crank_Maturing_Fault 0;
BA_ "GenSigTimeoutTime_AGSM" SG_ 271 ECMReq_Remedial_Stop 0;
BA_ "GenSigTimeoutTime_ASBS" SG_ 271 ECMReq_Remedial_Stop 0;
BA_ "GenSigTimeoutTime_BCM" SG_ 271 ECMReq_Remedial_Stop 0;
BA_ "GenSigTimeoutTime_BSM" SG_ 271 ECMReq_Remedial_Stop 0;
BA_ "GenSigTimeoutTime_CADM" SG_ 271 ECMReq_Remedial_Stop 0;
BA_ "GenSigTimeoutTime_DMSM" SG_ 271 ECMReq_Remedial_Stop 0;
BA_ "GenSigTimeoutTime_DTCM" SG_ 271 ECMReq_Remedial_Stop 0;
BA_ "GenSigTimeoutTime_ECM" SG_ 271 ECMReq_Remedial_Stop 0;
BA_ "GenSigTimeoutTime_ELSDM" SG_ 271 ECMReq_Remedial_Stop 0;
BA_ "GenSigTimeoutTime_ESL" SG_ 271 ECMReq_Remedial_Stop 0;
BA_ "GenSigTimeoutTime_GNMM" SG_ 271 ECMReq_Remedial_Stop 0;
BA_ "GenSigTimeoutTime_IPC" SG_ 271 ECMReq_Remedial_Stop 0;
BA_ "GenSigTimeoutTime_RFHM" SG_ 271 ECMReq_Remedial_Stop 0;
BA_ "GenSigTimeoutTime_SGW" SG_ 271 ECMReq_Remedial_Stop 0;
BA_ "GenSigTimeoutTime_TCM" SG_ 271 ECMReq_Remedial_Stop 0;
BA_ "GenSigTimeoutTime_AGSM" SG_ 271 AccPos 0;
BA_ "GenSigTimeoutTime_ASBS" SG_ 271 AccPos 0;
BA_ "GenSigTimeoutTime_BCM" SG_ 271 AccPos 0;
BA_ "GenSigTimeoutTime_BSM" SG_ 271 AccPos 0;
BA_ "GenSigTimeoutTime_CADM" SG_ 271 AccPos 0;
BA_ "GenSigTimeoutTime_DMSM" SG_ 271 AccPos 0;
BA_ "GenSigTimeoutTime_DTCM" SG_ 271 AccPos 0;
BA_ "GenSigTimeoutTime_ECM" SG_ 271 AccPos 0;
BA_ "GenSigTimeoutTime_ELSDM" SG_ 271 AccPos 0;
BA_ "GenSigTimeoutTime_ESL" SG_ 271 AccPos 0;
BA_ "GenSigTimeoutTime_GNMM" SG_ 271 AccPos 0;
BA_ "GenSigTimeoutTime_IPC" SG_ 271 AccPos 0;
BA_ "GenSigTimeoutTime_RFHM" SG_ 271 AccPos 0;
BA_ "GenSigTimeoutTime_SGW" SG_ 271 AccPos 0;
BA_ "GenSigTimeoutTime_TCM" SG_ 271 AccPos 0;
BA_ "GenSigTimeoutTime_AGSM" SG_ 271 AccPosV 0;
BA_ "GenSigTimeoutTime_ASBS" SG_ 271 AccPosV 0;
BA_ "GenSigTimeoutTime_BCM" SG_ 271 AccPosV 0;
BA_ "GenSigTimeoutTime_BSM" SG_ 271 AccPosV 0;
BA_ "GenSigTimeoutTime_CADM" SG_ 271 AccPosV 0;
BA_ "GenSigTimeoutTime_DMSM" SG_ 271 AccPosV 0;
BA_ "GenSigTimeoutTime_DTCM" SG_ 271 AccPosV 0;
BA_ "GenSigTimeoutTime_ECM" SG_ 271 AccPosV 0;
BA_ "GenSigTimeoutTime_ELSDM" SG_ 271 AccPosV 0;
BA_ "GenSigTimeoutTime_ESL" SG_ 271 AccPosV 0;
BA_ "GenSigTimeoutTime_GNMM" SG_ 271 AccPosV 0;
BA_ "GenSigTimeoutTime_IPC" SG_ 271 AccPosV 0;
BA_ "GenSigTimeoutTime_RFHM" SG_ 271 AccPosV 0;
BA_ "GenSigTimeoutTime_SGW" SG_ 271 AccPosV 0;
BA_ "GenSigTimeoutTime_TCM" SG_ 271 AccPosV 0;
BA_ "GenSigTimeoutTime_AGSM" SG_ 271 Cam_Exh_1_Locked 0;
BA_ "GenSigTimeoutTime_ASBS" SG_ 271 Cam_Exh_1_Locked 0;
BA_ "GenSigTimeoutTime_BCM" SG_ 271 Cam_Exh_1_Locked 0;
BA_ "GenSigTimeoutTime_BSM" SG_ 271 Cam_Exh_1_Locked 0;
BA_ "GenSigTimeoutTime_CADM" SG_ 271 Cam_Exh_1_Locked 0;
BA_ "GenSigTimeoutTime_DMSM" SG_ 271 Cam_Exh_1_Locked 0;
BA_ "GenSigTimeoutTime_DTCM" SG_ 271 Cam_Exh_1_Locked 0;
BA_ "GenSigTimeoutTime_ECM" SG_ 271 Cam_Exh_1_Locked 0;
BA_ "GenSigTimeoutTime_ELSDM" SG_ 271 Cam_Exh_1_Locked 0;
BA_ "GenSigTimeoutTime_ESL" SG_ 271 Cam_Exh_1_Locked 0;
BA_ "GenSigTimeoutTime_GNMM" SG_ 271 Cam_Exh_1_Locked 0;
BA_ "GenSigTimeoutTime_HCP" SG_ 271 Cam_Exh_1_Locked 0;
BA_ "GenSigTimeoutTime_IPC" SG_ 271 Cam_Exh_1_Locked 0;
BA_ "GenSigTimeoutTime_RFHM" SG_ 271 Cam_Exh_1_Locked 0;
BA_ "GenSigTimeoutTime_SGW" SG_ 271 Cam_Exh_1_Locked 0;
BA_ "GenSigTimeoutTime_TCM" SG_ 271 Cam_Exh_1_Locked 0;
BA_ "GenSigTimeoutTime_AGSM" SG_ 271 Cam_Exh_2_Locked 0;
BA_ "GenSigTimeoutTime_ASBS" SG_ 271 Cam_Exh_2_Locked 0;
BA_ "GenSigTimeoutTime_BCM" SG_ 271 Cam_Exh_2_Locked 0;
BA_ "GenSigTimeoutTime_BSM" SG_ 271 Cam_Exh_2_Locked 0;
BA_ "GenSigTimeoutTime_CADM" SG_ 271 Cam_Exh_2_Locked 0;
BA_ "GenSigTimeoutTime_DMSM" SG_ 271 Cam_Exh_2_Locked 0;
BA_ "GenSigTimeoutTime_DTCM" SG_ 271 Cam_Exh_2_Locked 0;
BA_ "GenSigTimeoutTime_ECM" SG_ 271 Cam_Exh_2_Locked 0;
BA_ "GenSigTimeoutTime_ELSDM" SG_ 271 Cam_Exh_2_Locked 0;
BA_ "GenSigTimeoutTime_ESL" SG_ 271 Cam_Exh_2_Locked 0;
BA_ "GenSigTimeoutTime_GNMM" SG_ 271 Cam_Exh_2_Locked 0;
BA_ "GenSigTimeoutTime_HCP" SG_ 271 Cam_Exh_2_Locked 0;
BA_ "GenSigTimeoutTime_IPC" SG_ 271 Cam_Exh_2_Locked 0;
BA_ "GenSigTimeoutTime_RFHM" SG_ 271 Cam_Exh_2_Locked 0;
BA_ "GenSigTimeoutTime_SGW" SG_ 271 Cam_Exh_2_Locked 0;
BA_ "GenSigTimeoutTime_TCM" SG_ 271 Cam_Exh_2_Locked 0;
BA_ "GenSigTimeoutTime_AGSM" SG_ 271 Cam_Int_1_Locked 0;
BA_ "GenSigTimeoutTime_ASBS" SG_ 271 Cam_Int_1_Locked 0;
BA_ "GenSigTimeoutTime_BCM" SG_ 271 Cam_Int_1_Locked 0;
BA_ "GenSigTimeoutTime_BSM" SG_ 271 Cam_Int_1_Locked 0;
BA_ "GenSigTimeoutTime_CADM" SG_ 271 Cam_Int_1_Locked 0;
BA_ "GenSigTimeoutTime_DMSM" SG_ 271 Cam_Int_1_Locked 0;
BA_ "GenSigTimeoutTime_DTCM" SG_ 271 Cam_Int_1_Locked 0;
BA_ "GenSigTimeoutTime_ECM" SG_ 271 Cam_Int_1_Locked 0;
BA_ "GenSigTimeoutTime_ELSDM" SG_ 271 Cam_Int_1_Locked 0;
BA_ "GenSigTimeoutTime_ESL" SG_ 271 Cam_Int_1_Locked 0;
BA_ "GenSigTimeoutTime_GNMM" SG_ 271 Cam_Int_1_Locked 0;
BA_ "GenSigTimeoutTime_HCP" SG_ 271 Cam_Int_1_Locked 0;
BA_ "GenSigTimeoutTime_IPC" SG_ 271 Cam_Int_1_Locked 0;
BA_ "GenSigTimeoutTime_RFHM" SG_ 271 Cam_Int_1_Locked 0;
BA_ "GenSigTimeoutTime_SGW" SG_ 271 Cam_Int_1_Locked 0;
BA_ "GenSigTimeoutTime_TCM" SG_ 271 Cam_Int_1_Locked 0;
BA_ "GenSigTimeoutTime_AGSM" SG_ 271 EngMinSparkNomCurrAirTorqCap 0;
BA_ "GenSigTimeoutTime_ASBS" SG_ 271 EngMinSparkNomCurrAirTorqCap 0;
BA_ "GenSigTimeoutTime_BCM" SG_ 271 EngMinSparkNomCurrAirTorqCap 0;
BA_ "GenSigTimeoutTime_BSM" SG_ 271 EngMinSparkNomCurrAirTorqCap 0;
BA_ "GenSigTimeoutTime_CADM" SG_ 271 EngMinSparkNomCurrAirTorqCap 0;
BA_ "GenSigTimeoutTime_DMSM" SG_ 271 EngMinSparkNomCurrAirTorqCap 0;
BA_ "GenSigTimeoutTime_DTCM" SG_ 271 EngMinSparkNomCurrAirTorqCap 0;
BA_ "GenSigTimeoutTime_ECM" SG_ 271 EngMinSparkNomCurrAirTorqCap 0;
BA_ "GenSigTimeoutTime_ELSDM" SG_ 271 EngMinSparkNomCurrAirTorqCap 0;
BA_ "GenSigTimeoutTime_ESL" SG_ 271 EngMinSparkNomCurrAirTorqCap 0;
BA_ "GenSigTimeoutTime_GNMM" SG_ 271 EngMinSparkNomCurrAirTorqCap 0;
BA_ "GenSigTimeoutTime_IPC" SG_ 271 EngMinSparkNomCurrAirTorqCap 0;
BA_ "GenSigTimeoutTime_RFHM" SG_ 271 EngMinSparkNomCurrAirTorqCap 0;
BA_ "GenSigTimeoutTime_SGW" SG_ 271 EngMinSparkNomCurrAirTorqCap 0;
BA_ "GenSigTimeoutTime_TCM" SG_ 271 EngMinSparkNomCurrAirTorqCap 0;
BA_ "GenSigTimeoutTime_AGSM" SG_ 271 RedSpkAuthorityAvbl 0;
BA_ "GenSigTimeoutTime_ASBS" SG_ 271 RedSpkAuthorityAvbl 0;
BA_ "GenSigTimeoutTime_BCM" SG_ 271 RedSpkAuthorityAvbl 0;
BA_ "GenSigTimeoutTime_BSM" SG_ 271 RedSpkAuthorityAvbl 0;
BA_ "GenSigTimeoutTime_CADM" SG_ 271 RedSpkAuthorityAvbl 0;
BA_ "GenSigTimeoutTime_DMSM" SG_ 271 RedSpkAuthorityAvbl 0;
BA_ "GenSigTimeoutTime_DTCM" SG_ 271 RedSpkAuthorityAvbl 0;
BA_ "GenSigTimeoutTime_ECM" SG_ 271 RedSpkAuthorityAvbl 0;
BA_ "GenSigTimeoutTime_ELSDM" SG_ 271 RedSpkAuthorityAvbl 0;
BA_ "GenSigTimeoutTime_ESL" SG_ 271 RedSpkAuthorityAvbl 0;
BA_ "GenSigTimeoutTime_GNMM" SG_ 271 RedSpkAuthorityAvbl 0;
BA_ "GenSigTimeoutTime_IPC" SG_ 271 RedSpkAuthorityAvbl 0;
BA_ "GenSigTimeoutTime_RFHM" SG_ 271 RedSpkAuthorityAvbl 0;
BA_ "GenSigTimeoutTime_SGW" SG_ 271 RedSpkAuthorityAvbl 0;
BA_ "GenSigTimeoutTime_TCM" SG_ 271 RedSpkAuthorityAvbl 0;
BA_ "GenSigStartValue" SG_ 271 MAP_4_BAR_PHEV 511;
BA_ "GenSigTimeoutTime_AGSM" SG_ 271 MAP_4_BAR_PHEV 0;
BA_ "GenSigTimeoutTime_ASBS" SG_ 271 MAP_4_BAR_PHEV 0;
BA_ "GenSigTimeoutTime_BCM" SG_ 271 MAP_4_BAR_PHEV 0;
BA_ "GenSigTimeoutTime_BSM" SG_ 271 MAP_4_BAR_PHEV 0;
BA_ "GenSigTimeoutTime_CADM" SG_ 271 MAP_4_BAR_PHEV 0;
BA_ "GenSigTimeoutTime_DMSM" SG_ 271 MAP_4_BAR_PHEV 0;
BA_ "GenSigTimeoutTime_DTCM" SG_ 271 MAP_4_BAR_PHEV 0;
BA_ "GenSigTimeoutTime_ECM" SG_ 271 MAP_4_BAR_PHEV 0;
BA_ "GenSigTimeoutTime_ELSDM" SG_ 271 MAP_4_BAR_PHEV 0;
BA_ "GenSigTimeoutTime_ESL" SG_ 271 MAP_4_BAR_PHEV 0;
BA_ "GenSigTimeoutTime_GNMM" SG_ 271 MAP_4_BAR_PHEV 0;
BA_ "GenSigTimeoutTime_IPC" SG_ 271 MAP_4_BAR_PHEV 0;
BA_ "GenSigTimeoutTime_RFHM" SG_ 271 MAP_4_BAR_PHEV 0;
BA_ "GenSigTimeoutTime_SGW" SG_ 271 MAP_4_BAR_PHEV 0;
BA_ "GenSigTimeoutTime_TCM" SG_ 271 MAP_4_BAR_PHEV 0;
BA_ "GenSigTimeoutTime_AGSM" SG_ 271 ECM_VTD_Freeze 0;
BA_ "GenSigTimeoutTime_ASBS" SG_ 271 ECM_VTD_Freeze 0;
BA_ "GenSigTimeoutTime_BCM" SG_ 271 ECM_VTD_Freeze 0;
BA_ "GenSigTimeoutTime_BSM" SG_ 271 ECM_VTD_Freeze 0;
BA_ "GenSigTimeoutTime_CADM" SG_ 271 ECM_VTD_Freeze 0;
BA_ "GenSigTimeoutTime_DMSM" SG_ 271 ECM_VTD_Freeze 0;
BA_ "GenSigTimeoutTime_DTCM" SG_ 271 ECM_VTD_Freeze 0;
BA_ "GenSigTimeoutTime_ECM" SG_ 271 ECM_VTD_Freeze 0;
BA_ "GenSigTimeoutTime_ELSDM" SG_ 271 ECM_VTD_Freeze 0;
BA_ "GenSigTimeoutTime_ESL" SG_ 271 ECM_VTD_Freeze 0;
BA_ "GenSigTimeoutTime_GNMM" SG_ 271 ECM_VTD_Freeze 0;
BA_ "GenSigTimeoutTime_IPC" SG_ 271 ECM_VTD_Freeze 0;
BA_ "GenSigTimeoutTime_RFHM" SG_ 271 ECM_VTD_Freeze 0;
BA_ "GenSigTimeoutTime_SGW" SG_ 271 ECM_VTD_Freeze 0;
BA_ "GenSigTimeoutTime_TCM" SG_ 271 ECM_VTD_Freeze 0;
BA_ "GenSigTimeoutTime_AGSM" SG_ 271 T_min_raw 0;
BA_ "GenSigTimeoutTime_ASBS" SG_ 271 T_min_raw 0;
BA_ "GenSigTimeoutTime_BCM" SG_ 271 T_min_raw 0;
BA_ "GenSigTimeoutTime_BSM" SG_ 271 T_min_raw 0;
BA_ "GenSigTimeoutTime_CADM" SG_ 271 T_min_raw 0;
BA_ "GenSigTimeoutTime_DMSM" SG_ 271 T_min_raw 0;
BA_ "GenSigTimeoutTime_DTCM" SG_ 271 T_min_raw 0;
BA_ "GenSigTimeoutTime_ECM" SG_ 271 T_min_raw 0;
BA_ "GenSigTimeoutTime_ELSDM" SG_ 271 T_min_raw 0;
BA_ "GenSigTimeoutTime_ESL" SG_ 271 T_min_raw 0;
BA_ "GenSigTimeoutTime_GNMM" SG_ 271 T_min_raw 0;
BA_ "GenSigTimeoutTime_IPC" SG_ 271 T_min_raw 0;
BA_ "GenSigTimeoutTime_RFHM" SG_ 271 T_min_raw 0;
BA_ "GenSigTimeoutTime_SGW" SG_ 271 T_min_raw 0;
BA_ "GenSigTimeoutTime_TCM" SG_ 271 T_min_raw 0;
BA_ "GenSigTimeoutTime_AGSM" SG_ 271 ECM_Comm_Fail_CAN 0;
BA_ "GenSigTimeoutTime_ASBS" SG_ 271 ECM_Comm_Fail_CAN 0;
BA_ "GenSigTimeoutTime_BCM" SG_ 271 ECM_Comm_Fail_CAN 0;
BA_ "GenSigTimeoutTime_BSM" SG_ 271 ECM_Comm_Fail_CAN 0;
BA_ "GenSigTimeoutTime_CADM" SG_ 271 ECM_Comm_Fail_CAN 0;
BA_ "GenSigTimeoutTime_DMSM" SG_ 271 ECM_Comm_Fail_CAN 0;
BA_ "GenSigTimeoutTime_DTCM" SG_ 271 ECM_Comm_Fail_CAN 0;
BA_ "GenSigTimeoutTime_ECM" SG_ 271 ECM_Comm_Fail_CAN 0;
BA_ "GenSigTimeoutTime_ELSDM" SG_ 271 ECM_Comm_Fail_CAN 0;
BA_ "GenSigTimeoutTime_ESL" SG_ 271 ECM_Comm_Fail_CAN 0;
BA_ "GenSigTimeoutTime_GNMM" SG_ 271 ECM_Comm_Fail_CAN 0;
BA_ "GenSigTimeoutTime_IPC" SG_ 271 ECM_Comm_Fail_CAN 0;
BA_ "GenSigTimeoutTime_RFHM" SG_ 271 ECM_Comm_Fail_CAN 0;
BA_ "GenSigTimeoutTime_SGW" SG_ 271 ECM_Comm_Fail_CAN 0;
BA_ "GenSigTimeoutTime_AGSM" SG_ 271 T_min_raw_Aggressive 0;
BA_ "GenSigTimeoutTime_ASBS" SG_ 271 T_min_raw_Aggressive 0;
BA_ "GenSigTimeoutTime_BCM" SG_ 271 T_min_raw_Aggressive 0;
BA_ "GenSigTimeoutTime_BSM" SG_ 271 T_min_raw_Aggressive 0;
BA_ "GenSigTimeoutTime_CADM" SG_ 271 T_min_raw_Aggressive 0;
BA_ "GenSigTimeoutTime_DMSM" SG_ 271 T_min_raw_Aggressive 0;
BA_ "GenSigTimeoutTime_DTCM" SG_ 271 T_min_raw_Aggressive 0;
BA_ "GenSigTimeoutTime_ECM" SG_ 271 T_min_raw_Aggressive 0;
BA_ "GenSigTimeoutTime_ELSDM" SG_ 271 T_min_raw_Aggressive 0;
BA_ "GenSigTimeoutTime_ESL" SG_ 271 T_min_raw_Aggressive 0;
BA_ "GenSigTimeoutTime_GNMM" SG_ 271 T_min_raw_Aggressive 0;
BA_ "GenSigTimeoutTime_IPC" SG_ 271 T_min_raw_Aggressive 0;
BA_ "GenSigTimeoutTime_RFHM" SG_ 271 T_min_raw_Aggressive 0;
BA_ "GenSigTimeoutTime_SGW" SG_ 271 T_min_raw_Aggressive 0;
BA_ "GenSigTimeoutTime_TCM" SG_ 271 T_min_raw_Aggressive 0;
BA_ "GenSigTimeoutTime_AGSM" SG_ 271 TLC_LRN_Rq 0;
BA_ "GenSigTimeoutTime_ASBS" SG_ 271 TLC_LRN_Rq 0;
BA_ "GenSigTimeoutTime_BCM" SG_ 271 TLC_LRN_Rq 0;
BA_ "GenSigTimeoutTime_BSM" SG_ 271 TLC_LRN_Rq 0;
BA_ "GenSigTimeoutTime_CADM" SG_ 271 TLC_LRN_Rq 0;
BA_ "GenSigTimeoutTime_DMSM" SG_ 271 TLC_LRN_Rq 0;
BA_ "GenSigTimeoutTime_DTCM" SG_ 271 TLC_LRN_Rq 0;
BA_ "GenSigTimeoutTime_ECM" SG_ 271 TLC_LRN_Rq 0;
BA_ "GenSigTimeoutTime_ELSDM" SG_ 271 TLC_LRN_Rq 0;
BA_ "GenSigTimeoutTime_ESL" SG_ 271 TLC_LRN_Rq 0;
BA_ "GenSigTimeoutTime_GNMM" SG_ 271 TLC_LRN_Rq 0;
BA_ "GenSigTimeoutTime_IPC" SG_ 271 TLC_LRN_Rq 0;
BA_ "GenSigTimeoutTime_RFHM" SG_ 271 TLC_LRN_Rq 0;
BA_ "GenSigTimeoutTime_SGW" SG_ 271 TLC_LRN_Rq 0;
BA_ "GenSigTimeoutTime_TCM" SG_ 271 TLC_LRN_Rq 0;
BA_ "GenSigTimeoutTime_AGSM" SG_ 271 T_Min_Mgate 0;
BA_ "GenSigTimeoutTime_ASBS" SG_ 271 T_Min_Mgate 0;
BA_ "GenSigTimeoutTime_BCM" SG_ 271 T_Min_Mgate 0;
BA_ "GenSigTimeoutTime_BSM" SG_ 271 T_Min_Mgate 0;
BA_ "GenSigTimeoutTime_CADM" SG_ 271 T_Min_Mgate 0;
BA_ "GenSigTimeoutTime_DMSM" SG_ 271 T_Min_Mgate 0;
BA_ "GenSigTimeoutTime_DTCM" SG_ 271 T_Min_Mgate 0;
BA_ "GenSigTimeoutTime_ECM" SG_ 271 T_Min_Mgate 0;
BA_ "GenSigTimeoutTime_ELSDM" SG_ 271 T_Min_Mgate 0;
BA_ "GenSigTimeoutTime_ESL" SG_ 271 T_Min_Mgate 0;
BA_ "GenSigTimeoutTime_GNMM" SG_ 271 T_Min_Mgate 0;
BA_ "GenSigTimeoutTime_IPC" SG_ 271 T_Min_Mgate 0;
BA_ "GenSigTimeoutTime_RFHM" SG_ 271 T_Min_Mgate 0;
BA_ "GenSigTimeoutTime_SGW" SG_ 271 T_Min_Mgate 0;
BA_ "GenSigTimeoutTime_TCM" SG_ 271 T_Min_Mgate 0;
BA_ "GenSigTimeoutTime_AGSM" SG_ 271 CmndAxleTorqRespTyp 0;
BA_ "GenSigTimeoutTime_ASBS" SG_ 271 CmndAxleTorqRespTyp 0;
BA_ "GenSigTimeoutTime_BCM" SG_ 271 CmndAxleTorqRespTyp 0;
BA_ "GenSigTimeoutTime_BSM" SG_ 271 CmndAxleTorqRespTyp 0;
BA_ "GenSigTimeoutTime_CADM" SG_ 271 CmndAxleTorqRespTyp 0;
BA_ "GenSigTimeoutTime_DMSM" SG_ 271 CmndAxleTorqRespTyp 0;
BA_ "GenSigTimeoutTime_DTCM" SG_ 271 CmndAxleTorqRespTyp 0;
BA_ "GenSigTimeoutTime_ECM" SG_ 271 CmndAxleTorqRespTyp 0;
BA_ "GenSigTimeoutTime_ELSDM" SG_ 271 CmndAxleTorqRespTyp 0;
BA_ "GenSigTimeoutTime_ESL" SG_ 271 CmndAxleTorqRespTyp 0;
BA_ "GenSigTimeoutTime_GNMM" SG_ 271 CmndAxleTorqRespTyp 0;
BA_ "GenSigTimeoutTime_IPC" SG_ 271 CmndAxleTorqRespTyp 0;
BA_ "GenSigTimeoutTime_RFHM" SG_ 271 CmndAxleTorqRespTyp 0;
BA_ "GenSigTimeoutTime_SGW" SG_ 271 CmndAxleTorqRespTyp 0;
BA_ "GenSigTimeoutTime_TCM" SG_ 271 CmndAxleTorqRespTyp 0;
BA_ "GenSigTimeoutTime_AGSM" SG_ 271 EngCylDeactEnCondMet 0;
BA_ "GenSigTimeoutTime_ASBS" SG_ 271 EngCylDeactEnCondMet 0;
BA_ "GenSigTimeoutTime_BCM" SG_ 271 EngCylDeactEnCondMet 0;
BA_ "GenSigTimeoutTime_BSM" SG_ 271 EngCylDeactEnCondMet 0;
BA_ "GenSigTimeoutTime_CADM" SG_ 271 EngCylDeactEnCondMet 0;
BA_ "GenSigTimeoutTime_DMSM" SG_ 271 EngCylDeactEnCondMet 0;
BA_ "GenSigTimeoutTime_DTCM" SG_ 271 EngCylDeactEnCondMet 0;
BA_ "GenSigTimeoutTime_ECM" SG_ 271 EngCylDeactEnCondMet 0;
BA_ "GenSigTimeoutTime_ELSDM" SG_ 271 EngCylDeactEnCondMet 0;
BA_ "GenSigTimeoutTime_ESL" SG_ 271 EngCylDeactEnCondMet 0;
BA_ "GenSigTimeoutTime_GNMM" SG_ 271 EngCylDeactEnCondMet 0;
BA_ "GenSigTimeoutTime_IPC" SG_ 271 EngCylDeactEnCondMet 0;
BA_ "GenSigTimeoutTime_RFHM" SG_ 271 EngCylDeactEnCondMet 0;
BA_ "GenSigTimeoutTime_SGW" SG_ 271 EngCylDeactEnCondMet 0;
BA_ "GenSigTimeoutTime_TCM" SG_ 271 EngCylDeactEnCondMet 0;
BA_ "GenSigTimeoutTime_AGSM" SG_ 271 EngCylDeactMd 0;
BA_ "GenSigTimeoutTime_ASBS" SG_ 271 EngCylDeactMd 0;
BA_ "GenSigTimeoutTime_BCM" SG_ 271 EngCylDeactMd 0;
BA_ "GenSigTimeoutTime_BSM" SG_ 271 EngCylDeactMd 0;
BA_ "GenSigTimeoutTime_CADM" SG_ 271 EngCylDeactMd 0;
BA_ "GenSigTimeoutTime_DMSM" SG_ 271 EngCylDeactMd 0;
BA_ "GenSigTimeoutTime_DTCM" SG_ 271 EngCylDeactMd 0;
BA_ "GenSigTimeoutTime_ECM" SG_ 271 EngCylDeactMd 0;
BA_ "GenSigTimeoutTime_ELSDM" SG_ 271 EngCylDeactMd 0;
BA_ "GenSigTimeoutTime_ESL" SG_ 271 EngCylDeactMd 0;
BA_ "GenSigTimeoutTime_GNMM" SG_ 271 EngCylDeactMd 0;
BA_ "GenSigTimeoutTime_IPC" SG_ 271 EngCylDeactMd 0;
BA_ "GenSigTimeoutTime_RFHM" SG_ 271 EngCylDeactMd 0;
BA_ "GenSigTimeoutTime_SGW" SG_ 271 EngCylDeactMd 0;
BA_ "GenSigTimeoutTime_TCM" SG_ 271 EngCylDeactMd 0;
BA_ "GenSigTimeoutTime_AGSM" SG_ 276 MinCreepWheelTrq_Enable 0;
BA_ "GenSigTimeoutTime_ASBS" SG_ 276 MinCreepWheelTrq_Enable 0;
BA_ "GenSigTimeoutTime_BCM" SG_ 276 MinCreepWheelTrq_Enable 0;
BA_ "GenSigTimeoutTime_BSM" SG_ 276 MinCreepWheelTrq_Enable 0;
BA_ "GenSigTimeoutTime_CADM" SG_ 276 MinCreepWheelTrq_Enable 0;
BA_ "GenSigTimeoutTime_DMSM" SG_ 276 MinCreepWheelTrq_Enable 0;
BA_ "GenSigTimeoutTime_DTCM" SG_ 276 MinCreepWheelTrq_Enable 0;
BA_ "GenSigTimeoutTime_ELSDM" SG_ 276 MinCreepWheelTrq_Enable 0;
BA_ "GenSigTimeoutTime_ESL" SG_ 276 MinCreepWheelTrq_Enable 0;
BA_ "GenSigTimeoutTime_GNMM" SG_ 276 MinCreepWheelTrq_Enable 0;
BA_ "GenSigTimeoutTime_HCP" SG_ 276 MinCreepWheelTrq_Enable 0;
BA_ "GenSigTimeoutTime_IPC" SG_ 276 MinCreepWheelTrq_Enable 0;
BA_ "GenSigTimeoutTime_RFHM" SG_ 276 MinCreepWheelTrq_Enable 0;
BA_ "GenSigTimeoutTime_SGW" SG_ 276 MinCreepWheelTrq_Enable 0;
BA_ "GenSigTimeoutTime_TCM" SG_ 276 MinCreepWheelTrq_Enable 0;
BA_ "GenSigTimeoutTime_AGSM" SG_ 276 NiTi_Achieved 0;
BA_ "GenSigTimeoutTime_ASBS" SG_ 276 NiTi_Achieved 0;
BA_ "GenSigTimeoutTime_BCM" SG_ 276 NiTi_Achieved 0;
BA_ "GenSigTimeoutTime_BSM" SG_ 276 NiTi_Achieved 0;
BA_ "GenSigTimeoutTime_CADM" SG_ 276 NiTi_Achieved 0;
BA_ "GenSigTimeoutTime_DMSM" SG_ 276 NiTi_Achieved 0;
BA_ "GenSigTimeoutTime_DTCM" SG_ 276 NiTi_Achieved 0;
BA_ "GenSigTimeoutTime_ELSDM" SG_ 276 NiTi_Achieved 0;
BA_ "GenSigTimeoutTime_ESL" SG_ 276 NiTi_Achieved 0;
BA_ "GenSigTimeoutTime_GNMM" SG_ 276 NiTi_Achieved 0;
BA_ "GenSigTimeoutTime_HCP" SG_ 276 NiTi_Achieved 0;
BA_ "GenSigTimeoutTime_IPC" SG_ 276 NiTi_Achieved 0;
BA_ "GenSigTimeoutTime_RFHM" SG_ 276 NiTi_Achieved 0;
BA_ "GenSigTimeoutTime_SGW" SG_ 276 NiTi_Achieved 0;
BA_ "GenSigTimeoutTime_TCM" SG_ 276 NiTi_Achieved 0;
BA_ "GenSigTimeoutTime_AGSM" SG_ 276 ShiftRangeState 0;
BA_ "GenSigTimeoutTime_ASBS" SG_ 276 ShiftRangeState 0;
BA_ "GenSigTimeoutTime_BCM" SG_ 276 ShiftRangeState 0;
BA_ "GenSigTimeoutTime_BSM" SG_ 276 ShiftRangeState 0;
BA_ "GenSigTimeoutTime_CADM" SG_ 276 ShiftRangeState 0;
BA_ "GenSigTimeoutTime_DMSM" SG_ 276 ShiftRangeState 0;
BA_ "GenSigTimeoutTime_DTCM" SG_ 276 ShiftRangeState 0;
BA_ "GenSigTimeoutTime_ELSDM" SG_ 276 ShiftRangeState 0;
BA_ "GenSigTimeoutTime_ESL" SG_ 276 ShiftRangeState 0;
BA_ "GenSigTimeoutTime_GNMM" SG_ 276 ShiftRangeState 0;
BA_ "GenSigTimeoutTime_HCP" SG_ 276 ShiftRangeState 0;
BA_ "GenSigTimeoutTime_IPC" SG_ 276 ShiftRangeState 0;
BA_ "GenSigTimeoutTime_RFHM" SG_ 276 ShiftRangeState 0;
BA_ "GenSigTimeoutTime_SGW" SG_ 276 ShiftRangeState 0;
BA_ "GenSigTimeoutTime_TCM" SG_ 276 ShiftRangeState 0;
BA_ "GenSigTimeoutTime_AGSM" SG_ 276 TransInpSpdPrfl 0;
BA_ "GenSigTimeoutTime_ASBS" SG_ 276 TransInpSpdPrfl 0;
BA_ "GenSigTimeoutTime_BCM" SG_ 276 TransInpSpdPrfl 0;
BA_ "GenSigTimeoutTime_BSM" SG_ 276 TransInpSpdPrfl 0;
BA_ "GenSigTimeoutTime_CADM" SG_ 276 TransInpSpdPrfl 0;
BA_ "GenSigTimeoutTime_DMSM" SG_ 276 TransInpSpdPrfl 0;
BA_ "GenSigTimeoutTime_DTCM" SG_ 276 TransInpSpdPrfl 0;
BA_ "GenSigTimeoutTime_ELSDM" SG_ 276 TransInpSpdPrfl 0;
BA_ "GenSigTimeoutTime_ESL" SG_ 276 TransInpSpdPrfl 0;
BA_ "GenSigTimeoutTime_GNMM" SG_ 276 TransInpSpdPrfl 0;
BA_ "GenSigTimeoutTime_HCP" SG_ 276 TransInpSpdPrfl 0;
BA_ "GenSigTimeoutTime_IPC" SG_ 276 TransInpSpdPrfl 0;
BA_ "GenSigTimeoutTime_RFHM" SG_ 276 TransInpSpdPrfl 0;
BA_ "GenSigTimeoutTime_SGW" SG_ 276 TransInpSpdPrfl 0;
BA_ "SystemSignalLongSymbol" SG_ 276 MessageCounter_HYBRID_POWERTRAI_114 "MessageCounter_HYBRID_POWERTRAIN1";
BA_ "GenSigTimeoutTime_AGSM" SG_ 276 MessageCounter_HYBRID_POWERTRAI_114 0;
BA_ "GenSigTimeoutTime_ASBS" SG_ 276 MessageCounter_HYBRID_POWERTRAI_114 0;
BA_ "GenSigTimeoutTime_BCM" SG_ 276 MessageCounter_HYBRID_POWERTRAI_114 0;
BA_ "GenSigTimeoutTime_DMSM" SG_ 276 MessageCounter_HYBRID_POWERTRAI_114 0;
BA_ "GenSigTimeoutTime_DTCM" SG_ 276 MessageCounter_HYBRID_POWERTRAI_114 0;
BA_ "GenSigTimeoutTime_ELSDM" SG_ 276 MessageCounter_HYBRID_POWERTRAI_114 0;
BA_ "GenSigTimeoutTime_ESL" SG_ 276 MessageCounter_HYBRID_POWERTRAI_114 0;
BA_ "GenSigTimeoutTime_GNMM" SG_ 276 MessageCounter_HYBRID_POWERTRAI_114 0;
BA_ "GenSigTimeoutTime_HCP" SG_ 276 MessageCounter_HYBRID_POWERTRAI_114 0;
BA_ "GenSigTimeoutTime_RFHM" SG_ 276 MessageCounter_HYBRID_POWERTRAI_114 0;
BA_ "GenSigTimeoutTime_SGW" SG_ 276 MessageCounter_HYBRID_POWERTRAI_114 0;
BA_ "GenSigTimeoutTime_AGSM" SG_ 276 DriveModeSts_EPT 0;
BA_ "GenSigTimeoutTime_ASBS" SG_ 276 DriveModeSts_EPT 0;
BA_ "GenSigTimeoutTime_BSM" SG_ 276 DriveModeSts_EPT 0;
BA_ "GenSigTimeoutTime_CADM" SG_ 276 DriveModeSts_EPT 0;
BA_ "GenSigTimeoutTime_DMSM" SG_ 276 DriveModeSts_EPT 0;
BA_ "GenSigTimeoutTime_DTCM" SG_ 276 DriveModeSts_EPT 0;
BA_ "GenSigTimeoutTime_ELSDM" SG_ 276 DriveModeSts_EPT 0;
BA_ "GenSigTimeoutTime_ESL" SG_ 276 DriveModeSts_EPT 0;
BA_ "GenSigTimeoutTime_GNMM" SG_ 276 DriveModeSts_EPT 0;
BA_ "GenSigTimeoutTime_HCP" SG_ 276 DriveModeSts_EPT 0;
BA_ "GenSigTimeoutTime_RFHM" SG_ 276 DriveModeSts_EPT 0;
BA_ "GenSigTimeoutTime_AGSM" SG_ 276 HybEstEngTorqV 0;
BA_ "GenSigTimeoutTime_ASBS" SG_ 276 HybEstEngTorqV 0;
BA_ "GenSigTimeoutTime_BCM" SG_ 276 HybEstEngTorqV 0;
BA_ "GenSigTimeoutTime_BSM" SG_ 276 HybEstEngTorqV 0;
BA_ "GenSigTimeoutTime_CADM" SG_ 276 HybEstEngTorqV 0;
BA_ "GenSigTimeoutTime_DMSM" SG_ 276 HybEstEngTorqV 0;
BA_ "GenSigTimeoutTime_DTCM" SG_ 276 HybEstEngTorqV 0;
BA_ "GenSigTimeoutTime_ELSDM" SG_ 276 HybEstEngTorqV 0;
BA_ "GenSigTimeoutTime_ESL" SG_ 276 HybEstEngTorqV 0;
BA_ "GenSigTimeoutTime_GNMM" SG_ 276 HybEstEngTorqV 0;
BA_ "GenSigTimeoutTime_HCP" SG_ 276 HybEstEngTorqV 0;
BA_ "GenSigTimeoutTime_IPC" SG_ 276 HybEstEngTorqV 0;
BA_ "GenSigTimeoutTime_RFHM" SG_ 276 HybEstEngTorqV 0;
BA_ "GenSigTimeoutTime_SGW" SG_ 276 HybEstEngTorqV 0;
BA_ "GenSigTimeoutTime_TCM" SG_ 276 HybEstEngTorqV 0;
BA_ "GenSigTimeoutTime_AGSM" SG_ 276 HybFeedback_Engine 0;
BA_ "GenSigTimeoutTime_ASBS" SG_ 276 HybFeedback_Engine 0;
BA_ "GenSigTimeoutTime_BCM" SG_ 276 HybFeedback_Engine 0;
BA_ "GenSigTimeoutTime_BSM" SG_ 276 HybFeedback_Engine 0;
BA_ "GenSigTimeoutTime_CADM" SG_ 276 HybFeedback_Engine 0;
BA_ "GenSigTimeoutTime_DMSM" SG_ 276 HybFeedback_Engine 0;
BA_ "GenSigTimeoutTime_DTCM" SG_ 276 HybFeedback_Engine 0;
BA_ "GenSigTimeoutTime_ELSDM" SG_ 276 HybFeedback_Engine 0;
BA_ "GenSigTimeoutTime_ESL" SG_ 276 HybFeedback_Engine 0;
BA_ "GenSigTimeoutTime_GNMM" SG_ 276 HybFeedback_Engine 0;
BA_ "GenSigTimeoutTime_HCP" SG_ 276 HybFeedback_Engine 0;
BA_ "GenSigTimeoutTime_IPC" SG_ 276 HybFeedback_Engine 0;
BA_ "GenSigTimeoutTime_RFHM" SG_ 276 HybFeedback_Engine 0;
BA_ "GenSigTimeoutTime_SGW" SG_ 276 HybFeedback_Engine 0;
BA_ "GenSigTimeoutTime_TCM" SG_ 276 HybFeedback_Engine 0;
BA_ "GenSigTimeoutTime_AGSM" SG_ 276 Hybrid_Remedial_Stop 0;
BA_ "GenSigTimeoutTime_ASBS" SG_ 276 Hybrid_Remedial_Stop 0;
BA_ "GenSigTimeoutTime_BCM" SG_ 276 Hybrid_Remedial_Stop 0;
BA_ "GenSigTimeoutTime_BSM" SG_ 276 Hybrid_Remedial_Stop 0;
BA_ "GenSigTimeoutTime_CADM" SG_ 276 Hybrid_Remedial_Stop 0;
BA_ "GenSigTimeoutTime_DMSM" SG_ 276 Hybrid_Remedial_Stop 0;
BA_ "GenSigTimeoutTime_DTCM" SG_ 276 Hybrid_Remedial_Stop 0;
BA_ "GenSigTimeoutTime_ELSDM" SG_ 276 Hybrid_Remedial_Stop 0;
BA_ "GenSigTimeoutTime_ESL" SG_ 276 Hybrid_Remedial_Stop 0;
BA_ "GenSigTimeoutTime_GNMM" SG_ 276 Hybrid_Remedial_Stop 0;
BA_ "GenSigTimeoutTime_HCP" SG_ 276 Hybrid_Remedial_Stop 0;
BA_ "GenSigTimeoutTime_IPC" SG_ 276 Hybrid_Remedial_Stop 0;
BA_ "GenSigTimeoutTime_RFHM" SG_ 276 Hybrid_Remedial_Stop 0;
BA_ "GenSigTimeoutTime_SGW" SG_ 276 Hybrid_Remedial_Stop 0;
BA_ "GenSigTimeoutTime_TCM" SG_ 276 Hybrid_Remedial_Stop 0;
BA_ "GenSigTimeoutTime_AGSM" SG_ 276 HybTransSt 0;
BA_ "GenSigTimeoutTime_ASBS" SG_ 276 HybTransSt 0;
BA_ "GenSigTimeoutTime_BCM" SG_ 276 HybTransSt 0;
BA_ "GenSigTimeoutTime_BSM" SG_ 276 HybTransSt 0;
BA_ "GenSigTimeoutTime_CADM" SG_ 276 HybTransSt 0;
BA_ "GenSigTimeoutTime_DMSM" SG_ 276 HybTransSt 0;
BA_ "GenSigTimeoutTime_DTCM" SG_ 276 HybTransSt 0;
BA_ "GenSigTimeoutTime_ELSDM" SG_ 276 HybTransSt 0;
BA_ "GenSigTimeoutTime_ESL" SG_ 276 HybTransSt 0;
BA_ "GenSigTimeoutTime_GNMM" SG_ 276 HybTransSt 0;
BA_ "GenSigTimeoutTime_HCP" SG_ 276 HybTransSt 0;
BA_ "GenSigTimeoutTime_IPC" SG_ 276 HybTransSt 0;
BA_ "GenSigTimeoutTime_RFHM" SG_ 276 HybTransSt 0;
BA_ "GenSigTimeoutTime_SGW" SG_ 276 HybTransSt 0;
BA_ "GenSigTimeoutTime_TCM" SG_ 276 HybTransSt 0;
BA_ "GenSigTimeoutTime_AGSM" SG_ 276 InputSpdRaw 0;
BA_ "GenSigTimeoutTime_ASBS" SG_ 276 InputSpdRaw 0;
BA_ "GenSigTimeoutTime_BCM" SG_ 276 InputSpdRaw 0;
BA_ "GenSigTimeoutTime_BSM" SG_ 276 InputSpdRaw 0;
BA_ "GenSigTimeoutTime_CADM" SG_ 276 InputSpdRaw 0;
BA_ "GenSigTimeoutTime_DMSM" SG_ 276 InputSpdRaw 0;
BA_ "GenSigTimeoutTime_DTCM" SG_ 276 InputSpdRaw 0;
BA_ "GenSigTimeoutTime_ELSDM" SG_ 276 InputSpdRaw 0;
BA_ "GenSigTimeoutTime_ESL" SG_ 276 InputSpdRaw 0;
BA_ "GenSigTimeoutTime_GNMM" SG_ 276 InputSpdRaw 0;
BA_ "GenSigTimeoutTime_HCP" SG_ 276 InputSpdRaw 0;
BA_ "GenSigTimeoutTime_IPC" SG_ 276 InputSpdRaw 0;
BA_ "GenSigTimeoutTime_RFHM" SG_ 276 InputSpdRaw 0;
BA_ "GenSigTimeoutTime_SGW" SG_ 276 InputSpdRaw 0;
BA_ "GenSigTimeoutTime_TCM" SG_ 276 InputSpdRaw 0;
BA_ "GenSigTimeoutTime_AGSM" SG_ 276 LV_SystemFailure 0;
BA_ "GenSigTimeoutTime_ASBS" SG_ 276 LV_SystemFailure 0;
BA_ "GenSigTimeoutTime_BCM" SG_ 276 LV_SystemFailure 0;
BA_ "GenSigTimeoutTime_BSM" SG_ 276 LV_SystemFailure 0;
BA_ "GenSigTimeoutTime_CADM" SG_ 276 LV_SystemFailure 0;
BA_ "GenSigTimeoutTime_DMSM" SG_ 276 LV_SystemFailure 0;
BA_ "GenSigTimeoutTime_DTCM" SG_ 276 LV_SystemFailure 0;
BA_ "GenSigTimeoutTime_ELSDM" SG_ 276 LV_SystemFailure 0;
BA_ "GenSigTimeoutTime_ESL" SG_ 276 LV_SystemFailure 0;
BA_ "GenSigTimeoutTime_GNMM" SG_ 276 LV_SystemFailure 0;
BA_ "GenSigTimeoutTime_HCP" SG_ 276 LV_SystemFailure 0;
BA_ "GenSigTimeoutTime_IPC" SG_ 276 LV_SystemFailure 0;
BA_ "GenSigTimeoutTime_RFHM" SG_ 276 LV_SystemFailure 0;
BA_ "GenSigTimeoutTime_SGW" SG_ 276 LV_SystemFailure 0;
BA_ "GenSigTimeoutTime_TCM" SG_ 276 LV_SystemFailure 0;
BA_ "GenSigStartValue" SG_ 276 HybCmndEngTorqImmed 938;
BA_ "GenSigTimeoutTime_AGSM" SG_ 276 HybCmndEngTorqImmed 0;
BA_ "GenSigTimeoutTime_ASBS" SG_ 276 HybCmndEngTorqImmed 0;
BA_ "GenSigTimeoutTime_BCM" SG_ 276 HybCmndEngTorqImmed 0;
BA_ "GenSigTimeoutTime_BSM" SG_ 276 HybCmndEngTorqImmed 0;
BA_ "GenSigTimeoutTime_CADM" SG_ 276 HybCmndEngTorqImmed 0;
BA_ "GenSigTimeoutTime_DMSM" SG_ 276 HybCmndEngTorqImmed 0;
BA_ "GenSigTimeoutTime_DTCM" SG_ 276 HybCmndEngTorqImmed 0;
BA_ "GenSigTimeoutTime_ELSDM" SG_ 276 HybCmndEngTorqImmed 0;
BA_ "GenSigTimeoutTime_ESL" SG_ 276 HybCmndEngTorqImmed 0;
BA_ "GenSigTimeoutTime_GNMM" SG_ 276 HybCmndEngTorqImmed 0;
BA_ "GenSigTimeoutTime_HCP" SG_ 276 HybCmndEngTorqImmed 0;
BA_ "GenSigTimeoutTime_IPC" SG_ 276 HybCmndEngTorqImmed 0;
BA_ "GenSigTimeoutTime_RFHM" SG_ 276 HybCmndEngTorqImmed 0;
BA_ "GenSigTimeoutTime_SGW" SG_ 276 HybCmndEngTorqImmed 0;
BA_ "GenSigTimeoutTime_TCM" SG_ 276 HybCmndEngTorqImmed 0;
BA_ "GenSigStartValue" SG_ 276 HybCmndEngTorqPrdtd 938;
BA_ "GenSigTimeoutTime_AGSM" SG_ 276 HybCmndEngTorqPrdtd 0;
BA_ "GenSigTimeoutTime_ASBS" SG_ 276 HybCmndEngTorqPrdtd 0;
BA_ "GenSigTimeoutTime_BCM" SG_ 276 HybCmndEngTorqPrdtd 0;
BA_ "GenSigTimeoutTime_BSM" SG_ 276 HybCmndEngTorqPrdtd 0;
BA_ "GenSigTimeoutTime_CADM" SG_ 276 HybCmndEngTorqPrdtd 0;
BA_ "GenSigTimeoutTime_DMSM" SG_ 276 HybCmndEngTorqPrdtd 0;
BA_ "GenSigTimeoutTime_DTCM" SG_ 276 HybCmndEngTorqPrdtd 0;
BA_ "GenSigTimeoutTime_ELSDM" SG_ 276 HybCmndEngTorqPrdtd 0;
BA_ "GenSigTimeoutTime_ESL" SG_ 276 HybCmndEngTorqPrdtd 0;
BA_ "GenSigTimeoutTime_GNMM" SG_ 276 HybCmndEngTorqPrdtd 0;
BA_ "GenSigTimeoutTime_HCP" SG_ 276 HybCmndEngTorqPrdtd 0;
BA_ "GenSigTimeoutTime_IPC" SG_ 276 HybCmndEngTorqPrdtd 0;
BA_ "GenSigTimeoutTime_RFHM" SG_ 276 HybCmndEngTorqPrdtd 0;
BA_ "GenSigTimeoutTime_SGW" SG_ 276 HybCmndEngTorqPrdtd 0;
BA_ "GenSigTimeoutTime_TCM" SG_ 276 HybCmndEngTorqPrdtd 0;
BA_ "GenSigTimeoutTime_AGSM" SG_ 276 HybCmndEngTorqRespTyp 0;
BA_ "GenSigTimeoutTime_ASBS" SG_ 276 HybCmndEngTorqRespTyp 0;
BA_ "GenSigTimeoutTime_BCM" SG_ 276 HybCmndEngTorqRespTyp 0;
BA_ "GenSigTimeoutTime_BSM" SG_ 276 HybCmndEngTorqRespTyp 0;
BA_ "GenSigTimeoutTime_CADM" SG_ 276 HybCmndEngTorqRespTyp 0;
BA_ "GenSigTimeoutTime_DMSM" SG_ 276 HybCmndEngTorqRespTyp 0;
BA_ "GenSigTimeoutTime_DTCM" SG_ 276 HybCmndEngTorqRespTyp 0;
BA_ "GenSigTimeoutTime_AGSM" SG_ 2654486550 CBV_bit1_1E384016 0;
BA_ "GenSigTimeoutTime_ASBS" SG_ 2654486550 CBV_bit1_1E384016 0;
BA_ "GenSigTimeoutTime_BCM" SG_ 2654486550 CBV_bit1_1E384016 0;
BA_ "GenSigTimeoutTime_BSM" SG_ 2654486550 CBV_bit1_1E384016 0;
BA_ "GenSigTimeoutTime_CADM" SG_ 2654486550 CBV_bit1_1E384016 0;
BA_ "GenSigTimeoutTime_DMSM" SG_ 2654486550 CBV_bit1_1E384016 0;
BA_ "GenSigTimeoutTime_DTCM" SG_ 2654486550 CBV_bit1_1E384016 0;
BA_ "GenSigTimeoutTime_ECM" SG_ 2654486550 CBV_bit1_1E384016 0;
BA_ "GenSigTimeoutTime_ELSDM" SG_ 2654486550 CBV_bit1_1E384016 0;
BA_ "GenSigTimeoutTime_ESL" SG_ 2654486550 CBV_bit1_1E384016 0;
BA_ "GenSigTimeoutTime_GNMM" SG_ 2654486550 CBV_bit1_1E384016 0;
BA_ "GenSigTimeoutTime_HCP" SG_ 2654486550 CBV_bit1_1E384016 0;
BA_ "GenSigTimeoutTime_IPC" SG_ 2654486550 CBV_bit1_1E384016 0;
BA_ "GenSigTimeoutTime_RFHM" SG_ 2654486550 CBV_bit1_1E384016 0;
BA_ "GenSigTimeoutTime_SGW" SG_ 2654486550 CBV_bit1_1E384016 0;
BA_ "GenSigTimeoutTime_TCM" SG_ 2654486550 CBV_bit1_1E384016 0;
BA_ "GenSigTimeoutTime_AGSM" SG_ 2654486550 CBV_bit2_1E384016 0;
BA_ "GenSigTimeoutTime_ASBS" SG_ 2654486550 CBV_bit2_1E384016 0;
BA_ "GenSigTimeoutTime_BCM" SG_ 2654486550 CBV_bit2_1E384016 0;
BA_ "GenSigTimeoutTime_BSM" SG_ 2654486550 CBV_bit2_1E384016 0;
BA_ "GenSigTimeoutTime_CADM" SG_ 2654486550 CBV_bit2_1E384016 0;
BA_ "GenSigTimeoutTime_DMSM" SG_ 2654486550 CBV_bit2_1E384016 0;
BA_ "GenSigTimeoutTime_DTCM" SG_ 2654486550 CBV_bit2_1E384016 0;
BA_ "GenSigTimeoutTime_ECM" SG_ 2654486550 CBV_bit2_1E384016 0;
BA_ "GenSigTimeoutTime_ELSDM" SG_ 2654486550 CBV_bit2_1E384016 0;
BA_ "GenSigTimeoutTime_ESL" SG_ 2654486550 CBV_bit2_1E384016 0;
BA_ "GenSigTimeoutTime_GNMM" SG_ 2654486550 CBV_bit2_1E384016 0;
BA_ "GenSigTimeoutTime_HCP" SG_ 2654486550 CBV_bit2_1E384016 0;
BA_ "GenSigTimeoutTime_IPC" SG_ 2654486550 CBV_bit2_1E384016 0;
BA_ "GenSigTimeoutTime_RFHM" SG_ 2654486550 CBV_bit2_1E384016 0;
BA_ "GenSigTimeoutTime_SGW" SG_ 2654486550 CBV_bit2_1E384016 0;
BA_ "GenSigTimeoutTime_TCM" SG_ 2654486550 CBV_bit2_1E384016 0;
BA_ "GenSigTimeoutTime_AGSM" SG_ 2654486550 CBV_bit3_NMCoordinatorBit_1E384016 0;
BA_ "GenSigTimeoutTime_ASBS" SG_ 2654486550 CBV_bit3_NMCoordinatorBit_1E384016 0;
BA_ "GenSigTimeoutTime_BCM" SG_ 2654486550 CBV_bit3_NMCoordinatorBit_1E384016 0;
BA_ "GenSigTimeoutTime_BSM" SG_ 2654486550 CBV_bit3_NMCoordinatorBit_1E384016 0;
BA_ "GenSigTimeoutTime_CADM" SG_ 2654486550 CBV_bit3_NMCoordinatorBit_1E384016 0;
BA_ "GenSigTimeoutTime_DMSM" SG_ 2654486550 CBV_bit3_NMCoordinatorBit_1E384016 0;
BA_ "GenSigTimeoutTime_DTCM" SG_ 2654486550 CBV_bit3_NMCoordinatorBit_1E384016 0;
BA_ "GenSigTimeoutTime_ECM" SG_ 2654486550 CBV_bit3_NMCoordinatorBit_1E384016 0;
BA_ "GenSigTimeoutTime_ELSDM" SG_ 2654486550 CBV_bit3_NMCoordinatorBit_1E384016 0;
BA_ "GenSigTimeoutTime_ESL" SG_ 2654486550 CBV_bit3_NMCoordinatorBit_1E384016 0;
BA_ "GenSigTimeoutTime_GNMM" SG_ 2654486550 CBV_bit3_NMCoordinatorBit_1E384016 0;
BA_ "GenSigTimeoutTime_HCP" SG_ 2654486550 CBV_bit3_NMCoordinatorBit_1E384016 0;
BA_ "GenSigTimeoutTime_IPC" SG_ 2654486550 CBV_bit3_NMCoordinatorBit_1E384016 0;
BA_ "GenSigTimeoutTime_RFHM" SG_ 2654486550 CBV_bit3_NMCoordinatorBit_1E384016 0;
BA_ "GenSigTimeoutTime_SGW" SG_ 2654486550 CBV_bit3_NMCoordinatorBit_1E384016 0;
BA_ "GenSigTimeoutTime_TCM" SG_ 2654486550 CBV_bit3_NMCoordinatorBit_1E384016 0;
BA_ "GenSigTimeoutTime_AGSM" SG_ 2654486550 CBV_bit4_ActiveWakeupBit_1E384016 0;
BA_ "GenSigTimeoutTime_ASBS" SG_ 2654486550 CBV_bit4_ActiveWakeupBit_1E384016 0;
BA_ "GenSigTimeoutTime_BCM" SG_ 2654486550 CBV_bit4_ActiveWakeupBit_1E384016 0;
BA_ "GenSigTimeoutTime_BSM" SG_ 2654486550 CBV_bit4_ActiveWakeupBit_1E384016 0;
BA_ "GenSigTimeoutTime_CADM" SG_ 2654486550 CBV_bit4_ActiveWakeupBit_1E384016 0;
BA_ "GenSigTimeoutTime_DMSM" SG_ 2654486550 CBV_bit4_ActiveWakeupBit_1E384016 0;
BA_ "GenSigTimeoutTime_DTCM" SG_ 2654486550 CBV_bit4_ActiveWakeupBit_1E384016 0;
BA_ "GenSigTimeoutTime_ECM" SG_ 2654486550 CBV_bit4_ActiveWakeupBit_1E384016 0;
BA_ "GenSigTimeoutTime_ELSDM" SG_ 2654486550 CBV_bit4_ActiveWakeupBit_1E384016 0;
BA_ "GenSigTimeoutTime_ESL" SG_ 2654486550 CBV_bit4_ActiveWakeupBit_1E384016 0;
BA_ "GenSigTimeoutTime_GNMM" SG_ 2654486550 CBV_bit4_ActiveWakeupBit_1E384016 0;
BA_ "GenSigTimeoutTime_HCP" SG_ 2654486550 CBV_bit4_ActiveWakeupBit_1E384016 0;
BA_ "GenSigTimeoutTime_IPC" SG_ 2654486550 CBV_bit4_ActiveWakeupBit_1E384016 0;
BA_ "GenSigTimeoutTime_RFHM" SG_ 2654486550 CBV_bit4_ActiveWakeupBit_1E384016 0;
BA_ "GenSigTimeoutTime_SGW" SG_ 2654486550 CBV_bit4_ActiveWakeupBit_1E384016 0;
BA_ "GenSigTimeoutTime_TCM" SG_ 2654486550 CBV_bit4_ActiveWakeupBit_1E384016 0;
BA_ "GenSigTimeoutTime_AGSM" SG_ 2654486550 CBV_bit5_1E384016 0;
BA_ "GenSigTimeoutTime_ASBS" SG_ 2654486550 CBV_bit5_1E384016 0;
BA_ "GenSigTimeoutTime_BCM" SG_ 2654486550 CBV_bit5_1E384016 0;
BA_ "GenSigTimeoutTime_BSM" SG_ 2654486550 CBV_bit5_1E384016 0;
BA_ "GenSigTimeoutTime_CADM" SG_ 2654486550 CBV_bit5_1E384016 0;
BA_ "GenSigTimeoutTime_DMSM" SG_ 2654486550 CBV_bit5_1E384016 0;
BA_ "GenSigTimeoutTime_DTCM" SG_ 2654486550 CBV_bit5_1E384016 0;
BA_ "GenSigTimeoutTime_ECM" SG_ 2654486550 CBV_bit5_1E384016 0;
BA_ "GenSigTimeoutTime_ELSDM" SG_ 2654486550 CBV_bit5_1E384016 0;
BA_ "GenSigTimeoutTime_ESL" SG_ 2654486550 CBV_bit5_1E384016 0;
BA_ "GenSigTimeoutTime_GNMM" SG_ 2654486550 CBV_bit5_1E384016 0;
BA_ "GenSigTimeoutTime_HCP" SG_ 2654486550 CBV_bit5_1E384016 0;
BA_ "GenSigTimeoutTime_IPC" SG_ 2654486550 CBV_bit5_1E384016 0;
BA_ "GenSigTimeoutTime_RFHM" SG_ 2654486550 CBV_bit5_1E384016 0;
BA_ "GenSigTimeoutTime_SGW" SG_ 2654486550 CBV_bit5_1E384016 0;
BA_ "GenSigTimeoutTime_TCM" SG_ 2654486550 CBV_bit5_1E384016 0;
BA_ "GenSigTimeoutTime_AGSM" SG_ 2654486550 CBV_bit6_PartialNtwInfBit_1E384016 0;
BA_ "GenSigTimeoutTime_ASBS" SG_ 2654486550 CBV_bit6_PartialNtwInfBit_1E384016 0;
BA_ "GenSigTimeoutTime_BCM" SG_ 2654486550 CBV_bit6_PartialNtwInfBit_1E384016 0;
BA_ "GenSigTimeoutTime_BSM" SG_ 2654486550 CBV_bit6_PartialNtwInfBit_1E384016 0;
BA_ "GenSigTimeoutTime_CADM" SG_ 2654486550 CBV_bit6_PartialNtwInfBit_1E384016 0;
BA_ "GenSigTimeoutTime_DMSM" SG_ 2654486550 CBV_bit6_PartialNtwInfBit_1E384016 0;
BA_ "GenSigTimeoutTime_DTCM" SG_ 2654486550 CBV_bit6_PartialNtwInfBit_1E384016 0;
BA_ "GenSigTimeoutTime_ECM" SG_ 2654486550 CBV_bit6_PartialNtwInfBit_1E384016 0;
BA_ "GenSigTimeoutTime_ELSDM" SG_ 2654486550 CBV_bit6_PartialNtwInfBit_1E384016 0;
BA_ "GenSigTimeoutTime_ESL" SG_ 2654486550 CBV_bit6_PartialNtwInfBit_1E384016 0;
BA_ "GenSigTimeoutTime_GNMM" SG_ 2654486550 CBV_bit6_PartialNtwInfBit_1E384016 0;
BA_ "GenSigTimeoutTime_HCP" SG_ 2654486550 CBV_bit6_PartialNtwInfBit_1E384016 0;
BA_ "GenSigTimeoutTime_IPC" SG_ 2654486550 CBV_bit6_PartialNtwInfBit_1E384016 0;
BA_ "GenSigTimeoutTime_RFHM" SG_ 2654486550 CBV_bit6_PartialNtwInfBit_1E384016 0;
BA_ "GenSigTimeoutTime_SGW" SG_ 2654486550 CBV_bit6_PartialNtwInfBit_1E384016 0;
BA_ "GenSigTimeoutTime_TCM" SG_ 2654486550 CBV_bit6_PartialNtwInfBit_1E384016 0;
BA_ "GenSigTimeoutTime_AGSM" SG_ 2654486550 CBV_bit7_1E384016 0;
BA_ "GenSigTimeoutTime_ASBS" SG_ 2654486550 CBV_bit7_1E384016 0;
BA_ "GenSigTimeoutTime_BCM" SG_ 2654486550 CBV_bit7_1E384016 0;
BA_ "GenSigTimeoutTime_BSM" SG_ 2654486550 CBV_bit7_1E384016 0;
BA_ "GenSigTimeoutTime_CADM" SG_ 2654486550 CBV_bit7_1E384016 0;
BA_ "GenSigTimeoutTime_DMSM" SG_ 2654486550 CBV_bit7_1E384016 0;
BA_ "GenSigTimeoutTime_DTCM" SG_ 2654486550 CBV_bit7_1E384016 0;
BA_ "GenSigTimeoutTime_ECM" SG_ 2654486550 CBV_bit7_1E384016 0;
BA_ "GenSigTimeoutTime_ELSDM" SG_ 2654486550 CBV_bit7_1E384016 0;
BA_ "GenSigTimeoutTime_ESL" SG_ 2654486550 CBV_bit7_1E384016 0;
BA_ "GenSigTimeoutTime_GNMM" SG_ 2654486550 CBV_bit7_1E384016 0;
BA_ "GenSigTimeoutTime_HCP" SG_ 2654486550 CBV_bit7_1E384016 0;
BA_ "GenSigTimeoutTime_IPC" SG_ 2654486550 CBV_bit7_1E384016 0;
BA_ "GenSigTimeoutTime_RFHM" SG_ 2654486550 CBV_bit7_1E384016 0;
BA_ "GenSigTimeoutTime_SGW" SG_ 2654486550 CBV_bit7_1E384016 0;
BA_ "GenSigTimeoutTime_TCM" SG_ 2654486550 CBV_bit7_1E384016 0;
BA_ "GenSigTimeoutTime_AGSM" SG_ 2654486582 CBV_bit0_RepeatMessageRequestBit_1E384036 0;
BA_ "GenSigTimeoutTime_ASBS" SG_ 2654486582 CBV_bit0_RepeatMessageRequestBit_1E384036 0;
BA_ "GenSigTimeoutTime_BCM" SG_ 2654486582 CBV_bit0_RepeatMessageRequestBit_1E384036 0;
BA_ "GenSigTimeoutTime_BSM" SG_ 2654486582 CBV_bit0_RepeatMessageRequestBit_1E384036 0;
BA_ "GenSigTimeoutTime_CADM" SG_ 2654486582 CBV_bit0_RepeatMessageRequestBit_1E384036 0;
BA_ "GenSigTimeoutTime_DMSM" SG_ 2654486582 CBV_bit0_RepeatMessageRequestBit_1E384036 0;
BA_ "GenSigTimeoutTime_DTCM" SG_ 2654486582 CBV_bit0_RepeatMessageRequestBit_1E384036 0;
BA_ "GenSigTimeoutTime_ECM" SG_ 2654486582 CBV_bit0_RepeatMessageRequestBit_1E384036 0;
BA_ "GenSigTimeoutTime_ELSDM" SG_ 2654486582 CBV_bit0_RepeatMessageRequestBit_1E384036 0;
BA_ "GenSigTimeoutTime_ESL" SG_ 2654486582 CBV_bit0_RepeatMessageRequestBit_1E384036 0;
BA_ "GenSigTimeoutTime_GNMM" SG_ 2654486582 CBV_bit0_RepeatMessageRequestBit_1E384036 0;
BA_ "GenSigTimeoutTime_HCP" SG_ 2654486582 CBV_bit0_RepeatMessageRequestBit_1E384036 0;
BA_ "GenSigTimeoutTime_IPC" SG_ 2654486582 CBV_bit0_RepeatMessageRequestBit_1E384036 0;
BA_ "GenSigTimeoutTime_RFHM" SG_ 2654486582 CBV_bit0_RepeatMessageRequestBit_1E384036 0;
BA_ "GenSigTimeoutTime_SGW" SG_ 2654486582 CBV_bit0_RepeatMessageRequestBit_1E384036 0;
BA_ "GenSigTimeoutTime_TCM" SG_ 2654486582 CBV_bit0_RepeatMessageRequestBit_1E384036 0;
BA_ "GenSigTimeoutTime_AGSM" SG_ 2654486582 CBV_bit1_1E384036 0;
BA_ "GenSigTimeoutTime_ASBS" SG_ 2654486582 CBV_bit1_1E384036 0;
BA_ "GenSigTimeoutTime_BCM" SG_ 2654486582 CBV_bit1_1E384036 0;
BA_ "GenSigTimeoutTime_BSM" SG_ 2654486582 CBV_bit1_1E384036 0;
BA_ "GenSigTimeoutTime_CADM" SG_ 2654486582 CBV_bit1_1E384036 0;
BA_ "GenSigTimeoutTime_DMSM" SG_ 2654486582 CBV_bit1_1E384036 0;
BA_ "GenSigTimeoutTime_DTCM" SG_ 2654486582 CBV_bit1_1E384036 0;
BA_ "GenSigTimeoutTime_ECM" SG_ 2654486582 CBV_bit1_1E384036 0;
BA_ "GenSigTimeoutTime_ELSDM" SG_ 2654486582 CBV_bit1_1E384036 0;
BA_ "GenSigTimeoutTime_ESL" SG_ 2654486582 CBV_bit1_1E384036 0;
BA_ "GenSigTimeoutTime_GNMM" SG_ 2654486582 CBV_bit1_1E384036 0;
BA_ "GenSigTimeoutTime_HCP" SG_ 2654486582 CBV_bit1_1E384036 0;
BA_ "GenSigTimeoutTime_IPC" SG_ 2654486582 CBV_bit1_1E384036 0;
BA_ "GenSigTimeoutTime_RFHM" SG_ 2654486582 CBV_bit1_1E384036 0;
BA_ "GenSigTimeoutTime_SGW" SG_ 2654486582 CBV_bit1_1E384036 0;
BA_ "GenSigTimeoutTime_TCM" SG_ 2654486582 CBV_bit1_1E384036 0;
BA_ "GenSigTimeoutTime_AGSM" SG_ 2654486582 CBV_bit2_1E384036 0;
BA_ "GenSigTimeoutTime_ASBS" SG_ 2654486582 CBV_bit2_1E384036 0;
BA_ "GenSigTimeoutTime_BCM" SG_ 2654486582 CBV_bit2_1E384036 0;
BA_ "GenSigTimeoutTime_BSM" SG_ 2654486582 CBV_bit2_1E384036 0;
BA_ "GenSigTimeoutTime_CADM" SG_ 2654486582 CBV_bit2_1E384036 0;
BA_ "GenSigTimeoutTime_DMSM" SG_ 2654486582 CBV_bit2_1E384036 0;
BA_ "GenSigTimeoutTime_DTCM" SG_ 2654486582 CBV_bit2_1E384036 0;
BA_ "GenSigTimeoutTime_ECM" SG_ 2654486582 CBV_bit2_1E384036 0;
BA_ "GenSigTimeoutTime_ELSDM" SG_ 2654486582 CBV_bit2_1E384036 0;
BA_ "GenSigTimeoutTime_ESL" SG_ 2654486582 CBV_bit2_1E384036 0;
BA_ "GenSigTimeoutTime_GNMM" SG_ 2654486582 CBV_bit2_1E384036 0;
BA_ "GenSigTimeoutTime_HCP" SG_ 2654486582 CBV_bit2_1E384036 0;
BA_ "GenSigTimeoutTime_IPC" SG_ 2654486582 CBV_bit2_1E384036 0;
BA_ "GenSigTimeoutTime_RFHM" SG_ 2654486582 CBV_bit2_1E384036 0;
BA_ "GenSigTimeoutTime_SGW" SG_ 2654486582 CBV_bit2_1E384036 0;
BA_ "GenSigTimeoutTime_TCM" SG_ 2654486582 CBV_bit2_1E384036 0;
BA_ "GenSigTimeoutTime_AGSM" SG_ 2654486582 CBV_bit3_NMCoordinatorBit_1E384036 0;
BA_ "GenSigTimeoutTime_ASBS" SG_ 2654486582 CBV_bit3_NMCoordinatorBit_1E384036 0;
BA_ "GenSigTimeoutTime_BCM" SG_ 2654486582 CBV_bit3_NMCoordinatorBit_1E384036 0;
BA_ "GenSigTimeoutTime_BSM" SG_ 2654486582 CBV_bit3_NMCoordinatorBit_1E384036 0;
BA_ "GenSigTimeoutTime_CADM" SG_ 2654486582 CBV_bit3_NMCoordinatorBit_1E384036 0;
BA_ "GenSigTimeoutTime_DMSM" SG_ 2654486582 CBV_bit3_NMCoordinatorBit_1E384036 0;
BA_ "GenSigTimeoutTime_DTCM" SG_ 2654486582 CBV_bit3_NMCoordinatorBit_1E384036 0;
BA_ "GenSigTimeoutTime_ECM" SG_ 2654486582 CBV_bit3_NMCoordinatorBit_1E384036 0;
BA_ "GenSigTimeoutTime_ELSDM" SG_ 2654486582 CBV_bit3_NMCoordinatorBit_1E384036 0;
BA_ "GenSigTimeoutTime_ESL" SG_ 2654486582 CBV_bit3_NMCoordinatorBit_1E384036 0;
BA_ "GenSigTimeoutTime_GNMM" SG_ 2654486582 CBV_bit3_NMCoordinatorBit_1E384036 0;
BA_ "GenSigTimeoutTime_HCP" SG_ 2654486582 CBV_bit3_NMCoordinatorBit_1E384036 0;
BA_ "GenSigTimeoutTime_IPC" SG_ 2654486582 CBV_bit3_NMCoordinatorBit_1E384036 0;
BA_ "GenSigTimeoutTime_RFHM" SG_ 2654486582 CBV_bit3_NMCoordinatorBit_1E384036 0;
BA_ "GenSigTimeoutTime_SGW" SG_ 2654486582 CBV_bit3_NMCoordinatorBit_1E384036 0;
BA_ "GenSigTimeoutTime_TCM" SG_ 2654486582 CBV_bit3_NMCoordinatorBit_1E384036 0;
BA_ "GenSigTimeoutTime_AGSM" SG_ 2654486582 CBV_bit4_ActiveWakeupBit_1E384036 0;
BA_ "GenSigTimeoutTime_ASBS" SG_ 2654486582 CBV_bit4_ActiveWakeupBit_1E384036 0;
BA_ "GenSigTimeoutTime_BCM" SG_ 2654486582 CBV_bit4_ActiveWakeupBit_1E384036 0;
BA_ "GenSigTimeoutTime_BSM" SG_ 2654486582 CBV_bit4_ActiveWakeupBit_1E384036 0;
BA_ "GenSigTimeoutTime_CADM" SG_ 2654486582 CBV_bit4_ActiveWakeupBit_1E384036 0;
BA_ "GenSigTimeoutTime_DMSM" SG_ 2654486582 CBV_bit4_ActiveWakeupBit_1E384036 0;
BA_ "GenSigTimeoutTime_DTCM" SG_ 2654486582 CBV_bit4_ActiveWakeupBit_1E384036 0;
BA_ "GenSigTimeoutTime_ECM" SG_ 2654486582 CBV_bit4_ActiveWakeupBit_1E384036 0;
BA_ "GenSigTimeoutTime_ELSDM" SG_ 2654486582 CBV_bit4_ActiveWakeupBit_1E384036 0;
BA_ "GenSigTimeoutTime_ESL" SG_ 2654486582 CBV_bit4_ActiveWakeupBit_1E384036 0;
BA_ "GenSigTimeoutTime_GNMM" SG_ 2654486582 CBV_bit4_ActiveWakeupBit_1E384036 0;
BA_ "GenSigTimeoutTime_HCP" SG_ 2654486582 CBV_bit4_ActiveWakeupBit_1E384036 0;
BA_ "GenSigTimeoutTime_IPC" SG_ 2654486582 CBV_bit4_ActiveWakeupBit_1E384036 0;
BA_ "GenSigTimeoutTime_RFHM" SG_ 2654486582 CBV_bit4_ActiveWakeupBit_1E384036 0;
BA_ "GenSigTimeoutTime_SGW" SG_ 2654486582 CBV_bit4_ActiveWakeupBit_1E384036 0;
BA_ "GenSigTimeoutTime_TCM" SG_ 2654486582 CBV_bit4_ActiveWakeupBit_1E384036 0;
BA_ "GenSigTimeoutTime_AGSM" SG_ 2654486582 CBV_bit5_1E384036 0;
BA_ "GenSigTimeoutTime_ASBS" SG_ 2654486582 CBV_bit5_1E384036 0;
BA_ "GenSigTimeoutTime_BCM" SG_ 2654486582 CBV_bit5_1E384036 0;
BA_ "GenSigTimeoutTime_BSM" SG_ 2654486582 CBV_bit5_1E384036 0;
BA_ "GenSigTimeoutTime_CADM" SG_ 2654486582 CBV_bit5_1E384036 0;
BA_ "GenSigTimeoutTime_DMSM" SG_ 2654486582 CBV_bit5_1E384036 0;
BA_ "GenSigTimeoutTime_DTCM" SG_ 2654486582 CBV_bit5_1E384036 0;
BA_ "GenSigTimeoutTime_ECM" SG_ 2654486582 CBV_bit5_1E384036 0;
BA_ "GenSigTimeoutTime_ELSDM" SG_ 2654486582 CBV_bit5_1E384036 0;
BA_ "GenSigTimeoutTime_ESL" SG_ 2654486582 CBV_bit5_1E384036 0;
BA_ "GenSigTimeoutTime_GNMM" SG_ 2654486582 CBV_bit5_1E384036 0;
BA_ "GenSigTimeoutTime_HCP" SG_ 2654486582 CBV_bit5_1E384036 0;
BA_ "GenSigTimeoutTime_IPC" SG_ 2654486582 CBV_bit5_1E384036 0;
BA_ "GenSigTimeoutTime_RFHM" SG_ 2654486582 CBV_bit5_1E384036 0;
BA_ "GenSigTimeoutTime_SGW" SG_ 2654486582 CBV_bit5_1E384036 0;
BA_ "GenSigTimeoutTime_TCM" SG_ 2654486582 CBV_bit5_1E384036 0;
BA_ "GenSigTimeoutTime_AGSM" SG_ 2654486582 CBV_bit6_PartialNtwInfBit_1E384036 0;
BA_ "GenSigTimeoutTime_ASBS" SG_ 2654486582 CBV_bit6_PartialNtwInfBit_1E384036 0;
BA_ "GenSigTimeoutTime_BCM" SG_ 2654486582 CBV_bit6_PartialNtwInfBit_1E384036 0;
BA_ "GenSigTimeoutTime_BSM" SG_ 2654486582 CBV_bit6_PartialNtwInfBit_1E384036 0;
BA_ "GenSigTimeoutTime_CADM" SG_ 2654486582 CBV_bit6_PartialNtwInfBit_1E384036 0;
BA_ "GenSigTimeoutTime_DMSM" SG_ 2654486582 CBV_bit6_PartialNtwInfBit_1E384036 0;
BA_ "GenSigTimeoutTime_DTCM" SG_ 2654486582 CBV_bit6_PartialNtwInfBit_1E384036 0;
BA_ "GenSigTimeoutTime_ECM" SG_ 2654486582 CBV_bit6_PartialNtwInfBit_1E384036 0;
BA_ "GenSigTimeoutTime_ELSDM" SG_ 2654486582 CBV_bit6_PartialNtwInfBit_1E384036 0;
BA_ "GenSigTimeoutTime_ESL" SG_ 2654486582 CBV_bit6_PartialNtwInfBit_1E384036 0;
BA_ "GenSigTimeoutTime_GNMM" SG_ 2654486582 CBV_bit6_PartialNtwInfBit_1E384036 0;
BA_ "GenSigTimeoutTime_HCP" SG_ 2654486582 CBV_bit6_PartialNtwInfBit_1E384036 0;
BA_ "GenSigTimeoutTime_IPC" SG_ 2654486582 CBV_bit6_PartialNtwInfBit_1E384036 0;
BA_ "GenSigTimeoutTime_RFHM" SG_ 2654486582 CBV_bit6_PartialNtwInfBit_1E384036 0;
BA_ "GenSigTimeoutTime_SGW" SG_ 2654486582 CBV_bit6_PartialNtwInfBit_1E384036 0;
BA_ "GenSigTimeoutTime_TCM" SG_ 2654486582 CBV_bit6_PartialNtwInfBit_1E384036 0;
BA_ "GenSigTimeoutTime_AGSM" SG_ 2654486582 CBV_bit7_1E384036 0;
BA_ "GenSigTimeoutTime_ASBS" SG_ 2654486582 CBV_bit7_1E384036 0;
BA_ "GenSigTimeoutTime_BCM" SG_ 2654486582 CBV_bit7_1E384036 0;
BA_ "GenSigTimeoutTime_BSM" SG_ 2654486582 CBV_bit7_1E384036 0;
BA_ "GenSigTimeoutTime_CADM" SG_ 2654486582 CBV_bit7_1E384036 0;
BA_ "GenSigTimeoutTime_DMSM" SG_ 2654486582 CBV_bit7_1E384036 0;
BA_ "GenSigTimeoutTime_DTCM" SG_ 2654486582 CBV_bit7_1E384036 0;
BA_ "GenSigTimeoutTime_ECM" SG_ 2654486582 CBV_bit7_1E384036 0;
BA_ "GenSigTimeoutTime_ELSDM" SG_ 2654486582 CBV_bit7_1E384036 0;
BA_ "GenSigTimeoutTime_ESL" SG_ 2654486582 CBV_bit7_1E384036 0;
BA_ "GenSigTimeoutTime_GNMM" SG_ 2654486582 CBV_bit7_1E384036 0;
BA_ "GenSigTimeoutTime_HCP" SG_ 2654486582 CBV_bit7_1E384036 0;
BA_ "GenSigTimeoutTime_IPC" SG_ 2654486582 CBV_bit7_1E384036 0;
BA_ "GenSigTimeoutTime_RFHM" SG_ 2654486582 CBV_bit7_1E384036 0;
BA_ "GenSigTimeoutTime_SGW" SG_ 2654486582 CBV_bit7_1E384036 0;
BA_ "GenSigTimeoutTime_TCM" SG_ 2654486582 CBV_bit7_1E384036 0;
BA_ "GenSigTimeoutTime_AGSM" SG_ 2654486582 SourceNodeIdentifier_1E384036 0;
BA_ "GenSigTimeoutTime_ASBS" SG_ 2654486582 SourceNodeIdentifier_1E384036 0;
BA_ "GenSigTimeoutTime_BCM" SG_ 2654486582 SourceNodeIdentifier_1E384036 0;
BA_ "GenSigTimeoutTime_BSM" SG_ 2654486582 SourceNodeIdentifier_1E384036 0;
BA_ "GenSigTimeoutTime_CADM" SG_ 2654486582 SourceNodeIdentifier_1E384036 0;
BA_ "GenSigTimeoutTime_DMSM" SG_ 2654486582 SourceNodeIdentifier_1E384036 0;
BA_ "GenSigTimeoutTime_DTCM" SG_ 2654486582 SourceNodeIdentifier_1E384036 0;
BA_ "GenSigTimeoutTime_ECM" SG_ 2654486582 SourceNodeIdentifier_1E384036 0;
BA_ "GenSigTimeoutTime_ELSDM" SG_ 2654486582 SourceNodeIdentifier_1E384036 0;
BA_ "GenSigTimeoutTime_ESL" SG_ 2654486582 SourceNodeIdentifier_1E384036 0;
BA_ "GenSigTimeoutTime_GNMM" SG_ 2654486582 SourceNodeIdentifier_1E384036 0;
BA_ "GenSigTimeoutTime_GNMM" SG_ 276 Hyb_SumTorqueStatic 0;
BA_ "GenSigTimeoutTime_HCP" SG_ 276 Hyb_SumTorqueStatic 0;
BA_ "GenSigTimeoutTime_IPC" SG_ 276 Hyb_SumTorqueStatic 0;
BA_ "GenSigTimeoutTime_RFHM" SG_ 276 Hyb_SumTorqueStatic 0;
BA_ "GenSigTimeoutTime_SGW" SG_ 276 Hyb_SumTorqueStatic 0;
BA_ "GenSigTimeoutTime_TCM" SG_ 276 Hyb_SumTorqueStatic 0;
BA_ "GenSigTimeoutTime_AGSM" SG_ 276 Hyb_SumTorqueMax 0;
BA_ "GenSigTimeoutTime_ASBS" SG_ 276 Hyb_SumTorqueMax 0;
BA_ "GenSigTimeoutTime_BCM" SG_ 276 Hyb_SumTorqueMax 0;
BA_ "GenSigTimeoutTime_BSM" SG_ 276 Hyb_SumTorqueMax 0;
BA_ "GenSigTimeoutTime_CADM" SG_ 276 Hyb_SumTorqueMax 0;
BA_ "GenSigTimeoutTime_DMSM" SG_ 276 Hyb_SumTorqueMax 0;
BA_ "GenSigTimeoutTime_DTCM" SG_ 276 Hyb_SumTorqueMax 0;
BA_ "GenSigTimeoutTime_ELSDM" SG_ 276 Hyb_SumTorqueMax 0;
BA_ "GenSigTimeoutTime_ESL" SG_ 276 Hyb_SumTorqueMax 0;
BA_ "GenSigTimeoutTime_GNMM" SG_ 276 Hyb_SumTorqueMax 0;
BA_ "GenSigTimeoutTime_HCP" SG_ 276 Hyb_SumTorqueMax 0;
BA_ "GenSigTimeoutTime_IPC" SG_ 276 Hyb_SumTorqueMax 0;
BA_ "GenSigTimeoutTime_RFHM" SG_ 276 Hyb_SumTorqueMax 0;
BA_ "GenSigTimeoutTime_SGW" SG_ 276 Hyb_SumTorqueMax 0;
BA_ "GenSigTimeoutTime_TCM" SG_ 276 Hyb_SumTorqueMax 0;
BA_ "GenSigTimeoutTime_AGSM" SG_ 276 Hyb_SumTorqueMin 0;
BA_ "GenSigTimeoutTime_ASBS" SG_ 276 Hyb_SumTorqueMin 0;
BA_ "GenSigTimeoutTime_BCM" SG_ 276 Hyb_SumTorqueMin 0;
BA_ "GenSigTimeoutTime_CADM" SG_ 276 Hyb_SumTorqueMin 0;
BA_ "GenSigTimeoutTime_DMSM" SG_ 276 Hyb_SumTorqueMin 0;
BA_ "GenSigTimeoutTime_DTCM" SG_ 276 Hyb_SumTorqueMin 0;
BA_ "GenSigTimeoutTime_ELSDM" SG_ 276 Hyb_SumTorqueMin 0;
BA_ "GenSigTimeoutTime_ESL" SG_ 276 Hyb_SumTorqueMin 0;
BA_ "GenSigTimeoutTime_GNMM" SG_ 276 Hyb_SumTorqueMin 0;
BA_ "GenSigTimeoutTime_HCP" SG_ 276 Hyb_SumTorqueMin 0;
BA_ "GenSigTimeoutTime_IPC" SG_ 276 Hyb_SumTorqueMin 0;
BA_ "GenSigTimeoutTime_RFHM" SG_ 276 Hyb_SumTorqueMin 0;
BA_ "GenSigTimeoutTime_SGW" SG_ 276 Hyb_SumTorqueMin 0;
BA_ "GenSigTimeoutTime_TCM" SG_ 276 Hyb_SumTorqueMin 0;
BA_ "GenSigStartValue" SG_ 276 Hyb_MotorB_Speed 65534;
BA_ "GenSigTimeoutTime_AGSM" SG_ 276 Hyb_MotorB_Speed 0;
BA_ "GenSigTimeoutTime_ASBS" SG_ 276 Hyb_MotorB_Speed 0;
BA_ "GenSigTimeoutTime_BCM" SG_ 276 Hyb_MotorB_Speed 0;
BA_ "GenSigTimeoutTime_BSM" SG_ 276 Hyb_MotorB_Speed 0;
BA_ "GenSigTimeoutTime_CADM" SG_ 276 Hyb_MotorB_Speed 0;
BA_ "GenSigTimeoutTime_DMSM" SG_ 276 Hyb_MotorB_Speed 0;
BA_ "GenSigTimeoutTime_DTCM" SG_ 276 Hyb_MotorB_Speed 0;
BA_ "GenSigTimeoutTime_ELSDM" SG_ 276 Hyb_MotorB_Speed 0;
BA_ "GenSigTimeoutTime_ESL" SG_ 276 Hyb_MotorB_Speed 0;
BA_ "GenSigTimeoutTime_GNMM" SG_ 276 Hyb_MotorB_Speed 0;
BA_ "GenSigTimeoutTime_HCP" SG_ 276 Hyb_MotorB_Speed 0;
BA_ "GenSigTimeoutTime_ELSDM" SG_ 276 HybCmndEngTorqRespTyp 0;
BA_ "GenSigTimeoutTime_ESL" SG_ 276 HybCmndEngTorqRespTyp 0;
BA_ "GenSigTimeoutTime_GNMM" SG_ 276 HybCmndEngTorqRespTyp 0;
BA_ "GenSigTimeoutTime_HCP" SG_ 276 HybCmndEngTorqRespTyp 0;
BA_ "GenSigTimeoutTime_IPC" SG_ 276 HybCmndEngTorqRespTyp 0;
BA_ "GenSigTimeoutTime_RFHM" SG_ 276 HybCmndEngTorqRespTyp 0;
BA_ "GenSigTimeoutTime_SGW" SG_ 276 HybCmndEngTorqRespTyp 0;
BA_ "GenSigTimeoutTime_TCM" SG_ 276 HybCmndEngTorqRespTyp 0;
BA_ "GenSigTimeoutTime_AGSM" SG_ 276 HybCrnkAbrted 0;
BA_ "GenSigTimeoutTime_ASBS" SG_ 276 HybCrnkAbrted 0;
BA_ "GenSigTimeoutTime_BCM" SG_ 276 HybCrnkAbrted 0;
BA_ "GenSigTimeoutTime_BSM" SG_ 276 HybCrnkAbrted 0;
BA_ "GenSigTimeoutTime_CADM" SG_ 276 HybCrnkAbrted 0;
BA_ "GenSigTimeoutTime_DMSM" SG_ 276 HybCrnkAbrted 0;
BA_ "GenSigTimeoutTime_DTCM" SG_ 276 HybCrnkAbrted 0;
BA_ "GenSigTimeoutTime_ELSDM" SG_ 276 HybCrnkAbrted 0;
BA_ "GenSigTimeoutTime_ESL" SG_ 276 HybCrnkAbrted 0;
BA_ "GenSigTimeoutTime_GNMM" SG_ 276 HybCrnkAbrted 0;
BA_ "GenSigTimeoutTime_HCP" SG_ 276 HybCrnkAbrted 0;
BA_ "GenSigTimeoutTime_IPC" SG_ 276 HybCrnkAbrted 0;
BA_ "GenSigTimeoutTime_RFHM" SG_ 276 HybCrnkAbrted 0;
BA_ "GenSigTimeoutTime_SGW" SG_ 276 HybCrnkAbrted 0;
BA_ "GenSigTimeoutTime_TCM" SG_ 276 HybCrnkAbrted 0;
BA_ "GenSigTimeoutTime_AGSM" SG_ 276 HybDFCO_Req 0;
BA_ "GenSigTimeoutTime_ASBS" SG_ 276 HybDFCO_Req 0;
BA_ "GenSigTimeoutTime_BCM" SG_ 276 HybDFCO_Req 0;
BA_ "GenSigTimeoutTime_BSM" SG_ 276 HybDFCO_Req 0;
BA_ "GenSigTimeoutTime_CADM" SG_ 276 HybDFCO_Req 0;
BA_ "GenSigTimeoutTime_DMSM" SG_ 276 HybDFCO_Req 0;
BA_ "GenSigTimeoutTime_DTCM" SG_ 276 HybDFCO_Req 0;
BA_ "GenSigTimeoutTime_ELSDM" SG_ 276 HybDFCO_Req 0;
BA_ "GenSigTimeoutTime_ESL" SG_ 276 HybDFCO_Req 0;
BA_ "GenSigTimeoutTime_GNMM" SG_ 276 HybDFCO_Req 0;
BA_ "GenSigTimeoutTime_HCP" SG_ 276 HybDFCO_Req 0;
BA_ "GenSigTimeoutTime_IPC" SG_ 276 HybDFCO_Req 0;
BA_ "GenSigTimeoutTime_RFHM" SG_ 276 HybDFCO_Req 0;
BA_ "GenSigTimeoutTime_SGW" SG_ 276 HybDFCO_Req 0;
BA_ "GenSigTimeoutTime_TCM" SG_ 276 HybDFCO_Req 0;
BA_ "GenSigStartValue" SG_ 276 HybEstEngTorq 938;
BA_ "GenSigTimeoutTime_AGSM" SG_ 276 HybEstEngTorq 0;
BA_ "GenSigTimeoutTime_ASBS" SG_ 276 HybEstEngTorq 0;
BA_ "GenSigTimeoutTime_BCM" SG_ 276 HybEstEngTorq 0;
BA_ "GenSigTimeoutTime_BSM" SG_ 276 HybEstEngTorq 0;
BA_ "GenSigTimeoutTime_CADM" SG_ 276 HybEstEngTorq 0;
BA_ "GenSigTimeoutTime_DMSM" SG_ 276 HybEstEngTorq 0;
BA_ "GenSigTimeoutTime_DTCM" SG_ 276 HybEstEngTorq 0;
BA_ "GenSigTimeoutTime_ELSDM" SG_ 276 HybEstEngTorq 0;
BA_ "GenSigTimeoutTime_ESL" SG_ 276 HybEstEngTorq 0;
BA_ "GenSigTimeoutTime_GNMM" SG_ 276 HybEstEngTorq 0;
BA_ "GenSigTimeoutTime_HCP" SG_ 276 HybEstEngTorq 0;
BA_ "GenSigTimeoutTime_IPC" SG_ 276 HybEstEngTorq 0;
BA_ "GenSigTimeoutTime_RFHM" SG_ 276 HybEstEngTorq 0;
BA_ "GenSigTimeoutTime_SGW" SG_ 276 HybEstEngTorq 0;
BA_ "GenSigTimeoutTime_TCM" SG_ 276 HybEstEngTorq 0;
BA_ "GenSigTimeoutTime_AGSM" SG_ 276 EngActDmpgDsblReq 0;
BA_ "GenSigTimeoutTime_ASBS" SG_ 276 EngActDmpgDsblReq 0;
BA_ "GenSigTimeoutTime_BCM" SG_ 276 EngActDmpgDsblReq 0;
BA_ "GenSigTimeoutTime_BSM" SG_ 276 EngActDmpgDsblReq 0;
BA_ "GenSigTimeoutTime_CADM" SG_ 276 EngActDmpgDsblReq 0;
BA_ "GenSigTimeoutTime_DMSM" SG_ 276 EngActDmpgDsblReq 0;
BA_ "GenSigTimeoutTime_DTCM" SG_ 276 EngActDmpgDsblReq 0;
BA_ "GenSigTimeoutTime_ELSDM" SG_ 276 EngActDmpgDsblReq 0;
BA_ "GenSigTimeoutTime_ESL" SG_ 276 EngActDmpgDsblReq 0;
BA_ "GenSigTimeoutTime_GNMM" SG_ 276 EngActDmpgDsblReq 0;
BA_ "GenSigTimeoutTime_HCP" SG_ 276 EngActDmpgDsblReq 0;
BA_ "GenSigTimeoutTime_IPC" SG_ 276 EngActDmpgDsblReq 0;
BA_ "GenSigTimeoutTime_RFHM" SG_ 276 EngActDmpgDsblReq 0;
BA_ "GenSigTimeoutTime_SGW" SG_ 276 EngActDmpgDsblReq 0;
BA_ "GenSigTimeoutTime_TCM" SG_ 276 EngActDmpgDsblReq 0;
BA_ "GenSigTimeoutTime_AGSM" SG_ 276 EngCntrlMode 0;
BA_ "GenSigTimeoutTime_ASBS" SG_ 276 EngCntrlMode 0;
BA_ "GenSigTimeoutTime_BCM" SG_ 276 EngCntrlMode 0;
BA_ "GenSigTimeoutTime_BSM" SG_ 276 EngCntrlMode 0;
BA_ "GenSigTimeoutTime_CADM" SG_ 276 EngCntrlMode 0;
BA_ "GenSigTimeoutTime_DMSM" SG_ 276 EngCntrlMode 0;
BA_ "GenSigTimeoutTime_DTCM" SG_ 276 EngCntrlMode 0;
BA_ "GenSigTimeoutTime_ELSDM" SG_ 276 EngCntrlMode 0;
BA_ "GenSigTimeoutTime_ESL" SG_ 276 EngCntrlMode 0;
BA_ "GenSigTimeoutTime_GNMM" SG_ 276 EngCntrlMode 0;
BA_ "GenSigTimeoutTime_HCP" SG_ 276 EngCntrlMode 0;
BA_ "GenSigTimeoutTime_IPC" SG_ 276 EngCntrlMode 0;
BA_ "GenSigTimeoutTime_RFHM" SG_ 276 EngCntrlMode 0;
BA_ "GenSigTimeoutTime_SGW" SG_ 276 EngCntrlMode 0;
BA_ "GenSigTimeoutTime_TCM" SG_ 276 EngCntrlMode 0;
BA_ "GenSigTimeoutTime_AGSM" SG_ 276 EngTrqReserveCmd 0;
BA_ "GenSigTimeoutTime_ASBS" SG_ 276 EngTrqReserveCmd 0;
BA_ "GenSigTimeoutTime_BCM" SG_ 276 EngTrqReserveCmd 0;
BA_ "GenSigTimeoutTime_BSM" SG_ 276 EngTrqReserveCmd 0;
BA_ "GenSigTimeoutTime_CADM" SG_ 276 EngTrqReserveCmd 0;
BA_ "GenSigTimeoutTime_DMSM" SG_ 276 EngTrqReserveCmd 0;
BA_ "GenSigTimeoutTime_DTCM" SG_ 276 EngTrqReserveCmd 0;
BA_ "GenSigTimeoutTime_ELSDM" SG_ 276 EngTrqReserveCmd 0;
BA_ "GenSigTimeoutTime_ESL" SG_ 276 EngTrqReserveCmd 0;
BA_ "GenSigTimeoutTime_GNMM" SG_ 276 EngTrqReserveCmd 0;
BA_ "GenSigTimeoutTime_HCP" SG_ 276 EngTrqReserveCmd 0;
BA_ "GenSigTimeoutTime_IPC" SG_ 276 EngTrqReserveCmd 0;
BA_ "GenSigTimeoutTime_RFHM" SG_ 276 EngTrqReserveCmd 0;
BA_ "GenSigTimeoutTime_SGW" SG_ 276 EngTrqReserveCmd 0;
BA_ "GenSigTimeoutTime_TCM" SG_ 276 EngTrqReserveCmd 0;
BA_ "GenSigTimeoutTime_AGSM" SG_ 276 GeneratorSetpointOverride 0;
BA_ "GenSigTimeoutTime_ASBS" SG_ 276 GeneratorSetpointOverride 0;
BA_ "GenSigTimeoutTime_BCM" SG_ 276 GeneratorSetpointOverride 0;
BA_ "GenSigTimeoutTime_BSM" SG_ 276 GeneratorSetpointOverride 0;
BA_ "GenSigTimeoutTime_CADM" SG_ 276 GeneratorSetpointOverride 0;
BA_ "GenSigTimeoutTime_DMSM" SG_ 276 GeneratorSetpointOverride 0;
BA_ "GenSigTimeoutTime_DTCM" SG_ 276 GeneratorSetpointOverride 0;
BA_ "GenSigTimeoutTime_ELSDM" SG_ 276 GeneratorSetpointOverride 0;
BA_ "GenSigTimeoutTime_ESL" SG_ 276 GeneratorSetpointOverride 0;
BA_ "GenSigTimeoutTime_GNMM" SG_ 276 GeneratorSetpointOverride 0;
VAL_ 269 MaxRegenStat 0 "Not_Possible" 1 "Possible";
VAL_ 269 BSGChrgIdleSpeedTarget 8191 "SNA";
VAL_ 269 BSGActualTorque 1023 "SNA";
VAL_ 276 ShiftRangeState 0 "Between_Range" 1 "Park" 2 "Reverse" 3 "Neutral" 4 "DRIVE" 5 "ONE" 6 "TWO" 7 "THREE" 8 "FOUR" 9 "FIVE" 10 "SIX" 15 "SNA";
VAL_ 276 MinCreepWheelTrq_Enable 0 "Disable" 1 "Enable";
VAL_ 276 InputSpdRaw 4095 "SNA";
VAL_ 276 HybTransSt 0 "INIT" 1 "Neutral_Stable_State" 2 "EVT_Mode1_Stable_State" 3 "EVT_Mode2_Stable_State" 4 "Gear1_Stable_State" 5 "Gear2_Stable_State" 6 "Gear3_Stable_State" 7 "Gear4_Stable_State" 8 "G1_G2_SP" 9 "G1_G2_TP" 10 "G2_G1_SP" 11 "G2_G1_TP" 12 "G2_G3_SP" 13 "G2_G3_TP" 14 "G3_G2_SP" 15 "G3_G2_TP" 16 "G3_G4_SP" 17 "G3_G4_TP" 18 "G4_G3_SP" 19 "G4_G3_TP" 20 "EVT_M1_Gear1_SP" 21 "EVT_M1_Gear2_SP" 22 "EVT_M2_Gear2_SP" 23 "EVT_M2_Gear3_SP" 24 "EVT_M2_Gear4_SP" 25 "Neutral_EVT_M1_Shift" 26 "Neutral_EVT_M2_Shift" 27 "Shift_Neutral" 28 "EVT_M1_EVT_M2_QS" 29 "EVT_M2_EVT_M1_QS" 30 "EVT_M1_SP" 31 "EVT_M2_SP" 32 "G1_Abort_G1G2_TP" 33 "G2_Abort_G2G3_TP" 34 "G3_Abort_G3G4_TP" 35 "G2_Abort_G2G1_TP" 36 "G3_Abort_G3G2_TP" 37 "G4_Abort_G4G3_TP" 38 "Init_Neut" 39 "M3" 40 "NeutToM3" 41 "M1ToM2_PwrOnC2CSpdPhs" 42 "M1ToM2_PwrOnC2CTorqPhs" 43 "M2ToM1_PwrOffC2CSpdPhs" 44 "M2ToM1_PwrOffC2CTorqPhs" 45 "M1ToM3_PwrOnC2CSpdPhs" 46 "M1ToM3_PwrOnC2CTorqPhs" 47 "M3ToM1_PwrOffC2CSpdPhs" 48 "M3ToM1_PwrOffC2CTorqPhs" 49 "M3ToG4" 50 "G2ToG4_PwrOnC2CSpdPhs" 51 "G2ToG4_PwrOnC2CTorqPhs" 52 "G4ToG2_PwrOffC2CSpdPhs" 53 "G4ToG2_PwrOffC2CTorqPhs" 54 "M1Abort_FromM1ToM2_C2CSpdPhs" 55 "M1Abort_FromM1ToM2_C2CTorqPhs" 56 "M1Abort_FromM1ToM3_C2CSpdPhs" 57 "M1Abort_FromM1ToM3_C2CTorqPhs" 58 "M2Abort_FromM2ToM1_C2CSpdPhs" 59 "M2Abort_FromM2ToM1_C2CTorqPhs" 60 "M3Abort" 61 "M3Abort_FromM3ToM1_C2CSpdPhs" 62 "M3Abort_FromM3ToM1_C2CTorqPhs" 63 "INV" 64 "G2Abort_FromG2ToG4_C2CSpdPhs" 65 "G2Abort_FromG2ToG4_C2CTorqPhs" 66 "G4Abort_FromG4ToG2_C2CSpdPhs" 67 "G4Abort_FromG4ToG2_C2CTorqPhs";
VAL_ 276 HybEstEngTorq 4095 "SNA";
VAL_ 276 HybCmndEngTorqRespTyp 0 "Inactive" 1 "PL" 2 "MR" 3 "SNA";
VAL_ 276 HybCmndEngTorqPrdtd 4095 "SNA";
VAL_ 276 HybCmndEngTorqImmed 4095 "SNA";
VAL_ 276 Hyb_EngStrtStopType 0 "No Action" 1 "Hybrid Torque Start" 2 "Engine Torque Start" 3 "Low Power Start" 4 "Green Engine Start" 5 "Generic Torque Start" 6 "Smooth Autostart" 7 "Normal Autostart" 8 "Aggressive Autostart" 9 "Generic Autostart" 10 "Compression Test" 11 "Controlled Stop" 12 "Immediate Stop" 13 "Reverse Autostart" 14 "Reserved" 15 "SNA";
VAL_ 276 HEV_ESS_Mode 0 "EngOff" 1 "IS" 2 "STPA" 3 "EFA" 4 "ETS" 5 "PT" 6 "DFA" 7 "SPPA" 8 "SF" 9 "CT" 15 "SNA";
VAL_ 276 EngTrqReserveCmd 255 "SNA";
VAL_ 271 T_min_raw_Aggressive 65535 "SNA";
VAL_ 271 T_max_raw 65535 "SNA";
VAL_ 271 Sum_FW_ID_Slw 31 "SNA";
VAL_ 271 Sum_FW_ID_Fst 31 "SNA";
VAL_ 271 MinPrdtdEngRunTorqCapV 0 "Valid" 1 "Not_Valid";
VAL_ 271 MinPrdtdEngRunTorqCap 4095 "SNA";
VAL_ 271 MinImmedEngTorqCapV 0 "Valid" 1 "Not_Valid";
VAL_ 271 MinImmedEngTorqCap 4095 "SNA";
VAL_ 271 MinEngTorqCapV 0 "Valid" 1 "Not_Valid";
VAL_ 271 MinEngTorqCap 4095 "SNA";
VAL_ 271 MinAirFlowMinSparkTorqCap 4095 "SNA";
VAL_ 271 MaxPrdtdEngTorqCapV 0 "Valid" 1 "Not_Valid";
VAL_ 271 MaxPrdtdEngTorqCap 4095 "SNA";
VAL_ 271 MaxOffEngTorqCap 4095 "SNA";
VAL_ 271 HybActEngTorqRespTyp 0 "Inactive" 1 "Pleasability_Limited" 2 "Maximum_Range";
VAL_ 271 ETRQ_Mode 7 "SNA";
VAL_ 271 ESS_Engine_State_EE 1 "ENS_STOPPED" 2 "ENS_RQ_ST" 3 "ENS_RUN" 4 "ENS_STOP_PEND" 5 "ENS_ST_PRTCT" 6 "ENS_ST_INH" 7 "ENS_DSBL" 8 "ENS_IHB_LATCH" 9 "ENS_ST" 10 "KEY_START" 11 "CHANGED_MIND" 12 "KEY_TORQUE_START" 13 "ENS_DISARM_RUN" 15 "SNA";
VAL_ 271 EngTrqReserveReq 255 "SNA";
VAL_ 271 EngRqStTyp 0 "N_RQ" 1 "KS_NORM" 2 "KS_LP" 3 "KS_LPB" 4 "KS_GEN" 5 "AS_SM" 6 "AS_NORM" 7 "AS_AGG" 8 "AS_GEN" 9 "CT" 15 "SNA";
VAL_ 271 Engine_Sync_720 0 "NOT_SYNCED" 1 "SYNC_720_ACHIEVED";
VAL_ 271 EngAirFlwStdyStTorqV 0 "Valid" 1 "Not_Valid";
VAL_ 271 EngAirFlwStdyStTorq 4095 "SNA";
VAL_ 271 EngActuatorsStat 0 "ACPP" 1 "SCPP" 2 "ACPA";
VAL_ 271 EngActStdyStTorqV 0 "Valid" 1 "Not_Valid";
VAL_ 271 EngActStdyStTorq 4095 "SNA";
VAL_ 271 ECM_IMMO_STAT_CANePT 0 "IS" 1 "KILL" 2 "RUN" 3 "SNA";
VAL_ 271 DrvrIntndedAxleTorqRawV 0 "Valid" 1 "Not_Valid";
VAL_ 271 DrvrIntndedAxleTorqRaw 65535 "SNA";
VAL_ 271 Crank_Maturing_Fault 0 "False" 1 "True";
VAL_ 271 Crank_Locked 0 "NOT_LOCKED" 1 "CRANK_LOCKED";
VAL_ 271 CmndFlyWheelTorqRespTyp 0 "Inactive" 1 "PL" 2 "MR";
VAL_ 271 CmndFlyWheelTorqPrdtd 4095 "SNA";
VAL_ 271 CmndFlyWheelTorqPotential 4095 "SNA";
VAL_ 271 Cam_Int_2_Locked 0 "CAM_UNLOCKED" 1 "CAM_LOCKED";
VAL_ 271 Cam_Int_1_Locked 0 "CAM_UNLOCKED" 1 "CAM_LOCKED";
VAL_ 271 Cam_Exh_2_Locked 0 "CAM_UNLOCKED" 1 "CAM_LOCKED";
VAL_ 271 Cam_Exh_1_Locked 0 "CAM_UNLOCKED" 1 "CAM_LOCKED";
VAL_ 271 AccPosV 0 "False" 1 "True";
VAL_ 269 PropulsionMode 0 "Hybrid_Parallel" 1 "EV_Only" 2 "Hybrid_Series" 7 "SNA";
VAL_ 276 PropulsionSystemActive 0 "Not_Active" 1 "Active";
VAL_ 276 HCP_Comm_Fail_CAN 0 "No_Fault" 1 "HCP_LOC_CAN_TCM" 2 "HCP_LOC_CAN_ECM" 3 "HCP_LOC_CAN_ECM_TCM" 7 "HCP_Bus_Failure_CAN";
VAL_ 271 ECMReq_Remedial_Stop 0 "DEFAULT" 1 "Remedial_Stp_Req" 2 "Remedial_Stp_Req_w_Limp" 3 "SNA";
VAL_ 271 ECM_Comm_Fail_CAN 0 "No_Fault" 1 "ECM_LOC_CAN_TCM" 2 "ECM_LOC_CAN_HCP" 3 "ECM_LOC_CAN_HCP_TCM" 7 "ECM_Bus_Failure_CAN";
VAL_ 271 EngCylDeactMd 0 "CYL_ACT" 1 "DAP" 2 "HTCA" 3 "RAP";
VAL_ 276 MinCreepWheelTrq 16383 "SNA";
VAL_ 271 CmndAxleTorqRespTyp 0 "Inactive" 1 "PL" 2 "MR";
VAL_ 276 NiTi_Disable 0 "False" 1 "True";
VAL_ 276 Hyb_MotorB_Speed 65534 "Initialization" 65535 "SNA";
VAL_ 276 Hyb_SumTorqueMin 2047 "SNA";
VAL_ 276 Hyb_SumTorqueMax 2047 "SNA";
VAL_ 276 Hyb_SumTorqueStatic 2047 "SNA";
VAL_ 271 T_Min_Mgate 65535 "SNA";
VAL_ 269 REPRGD_PFC_CLR_HCP 0 "Do Nothing" 1 "Set Incomplete";
VAL_ 269 EstRegenBrkFWTorq 4095 "SNA";
VAL_ 269 CODE_CLR_HCP 0 "Not Clear" 1 "Clear";
VAL_ 276 DriveModeSts_EPT 0 "Drive_Mode_Unavailable" 1 "Eco_Drive" 2 "Sport_Hybrid" 3 "Extend" 4 "ESave" 8 "Electric" 9 "Blended" 15 "SNA";
VAL_ 271 T_min_raw 65535 "SNA";
VAL_ 276 HCP_VTD_Freeze 0 "No_reset" 1 "Lifetime_and_Recent_Clear" 2 "Recent_Clear" 3 "Freeze";
VAL_ 271 ECM_VTD_Freeze 0 "No_reset" 1 "Lifetime_and_Recent_Clear" 2 "Recent_Clear" 3 "Freeze";
VAL_ 269 AHH_ModifyAccel_Req 0 "Not_Active" 1 "Active" 3 "SNA";
VAL_ 271 MAP_4_BAR_PHEV 511 "SNA";
VAL_ 2654486582 CBV_bit4_ActiveWakeupBit_1E384036 0 "PassiveWakeup" 1 "ActiveWakeup";
VAL_ 2654486582 CBV_bit6_PartialNtwInfBit_1E384036 0 "NM_PDU_contains_no_Partial_Network_request_information" 1 "NM_PDU_contains_Partial_Network_request_information";
VAL_ 2654486582 CBV_bit0_RepeatMessageRequestBit_1E384036 0 "Repeat_Message_State_not_requested" 1 "Repeat_Message_State_requested";
VAL_ 2654486582 CBV_bit3_NMCoordinatorBit_1E384036 0 "Start_of_synchronized_shutdown_is_not_requested_by_main_coordinator" 1 "Start_of_synchronized_shutdown_is_requested_by_main_coordinator";
VAL_ 2654486550 CBV_bit6_PartialNtwInfBit_1E384016 0 "NM_PDU_contains_no_Partial_Network_request_information" 1 "NM_PDU_contains_Partial_Network_request_information";
VAL_ 2654486550 CBV_bit0_RepeatMessageRequestBit_1E384016 0 "Repeat_Message_State_not_requested" 1 "Repeat_Message_State_requested";
VAL_ 2654486550 CBV_bit3_NMCoordinatorBit_1E384016 0 "Start_of_synchronized_shutdown_is_not_requested_by_main_coordinator" 1 "Start_of_synchronized_shutdown_is_requested_by_main_coordinator";
VAL_ 2654486550 CBV_bit4_ActiveWakeupBit_1E384016 0 "PassiveWakeup" 1 "ActiveWakeup";
VAL_ 271 RedSpkAuthorityAvbl 0 "Not_Available" 1 "Available";
VAL_ 271 EngMinSparkNomCurrAirTorqCap 2047 "SNA";
SIG_GROUP_ 269 HYBRID_POWERTRAIN2_Pkt 1 : MaxRegenStat IdleSpeedActiveSts CRC_HYBRID_POWERTRAIN2 BSGChrgIdleSpeedTarget BSGActualTorque PropulsionMode REPRGD_PFC_CLR_HCP EstRegenBrkFWTorq CODE_CLR_HCP AeCoast_Ramp AHH_ModifyAccel_Req MessageCounter_HYBRID_POWERTRAI_10D;
SIG_GROUP_ 276 HYBRID_POWERTRAIN1_Pkt 1 : TransInpSpdPrfl ShiftRangeState NiTi_Achieved MinCreepWheelTrq_Enable LV_SystemFailure InputSpdRaw HybTransSt Hybrid_Remedial_Stop HybFeedback_Engine HybEstEngTorqV HybEstEngTorq HybDFCO_Req HybCrnkAbrted HybCmndEngTorqRespTyp HybCmndEngTorqPrdtd HybCmndEngTorqImmed Hyb_EngStrtStopType HEV_ESS_Mode GeneratorSetpointOverride EngTrqReserveCmd EngCntrlMode EngActDmpgDsblReq Eng_Off_Allowed ECMPrepIdleRes CRC_HYBRID_POWERTRAIN1 PropulsionSystemActive HybFstTrqRq_Trans HCP_Comm_Fail_CAN MinCreepWheelTrq NiTi_Disable Hyb_MotorB_Speed Hyb_SumTorqueMin Hyb_SumTorqueMax Hyb_SumTorqueStatic DriveModeSts_EPT HCP_VTD_Freeze MessageCounter_HYBRID_POWERTRAI_114;
SIG_GROUP_ 271 ENGINE_HYBD_FD_1_Pkt 1 : TLC_LRN_Rq T_min_raw_Aggressive T_max_raw Sum_FW_ID_Slw Sum_FW_ID_Fst PTCrnkAbrted PT_CrnkAct MinPrdtdEngRunTorqCapV MinPrdtdEngRunTorqCap MinImmedEngTorqCapV MinImmedEngTorqCap MinEngTorqCapV MinEngTorqCap MinAirFlowMinSparkTorqCapV MinAirFlowMinSparkTorqCap MessageCounter_ENGINE_HYBD_FD_1 MaxPrdtdEngTorqCapV MaxPrdtdEngTorqCap MaxOffEngTorqCap HybActEngTorqRespTyp Feedback_HCP ETRQ_Mode ESS_Engine_State_EE EngTrqReserveReq EngSysFld EngRunCrnkAct EngRqStTyp EngOffRecom Engine_Sync_720 EngDFCO_St EngDFCO_Req EngDFCO_Allw EngCmbstnCmnd EngAirFlwStdyStTorqV EngAirFlwStdyStTorq EngActuatorsStat EngActStdyStTorqV EngActStdyStTorq ECU_A2D_Failure ECM_IMMO_STAT_CANePT DrvrIntndedAxleTorqRawV DrvrIntndedAxleTorqRaw CylOff CRC_ENGINE_HYBD_FD_1 Crank_Maturing_Fault Crank_Locked CmndFlyWheelTorqRespTyp CmndFlyWheelTorqPrdtd CmndFlyWheelTorqPotential Cam_Int_2_Locked Cam_Int_1_Locked Cam_Exh_2_Locked Cam_Exh_1_Locked AccPosV AccPos ECMReq_Remedial_Stop ECM_Comm_Fail_CAN EngCylDeactMd EngCylDeactEnCondMet CmndAxleTorqRespTyp T_Min_Mgate T_min_raw ECM_VTD_Freeze MAP_4_BAR_PHEV RedSpkAuthorityAvbl EngMinSparkNomCurrAirTorqCap;
